VERSION "created by canmatrix"

NS_ :

BS_:

BU_: TCM iBooster HCU CIM SCM Right_Hand_Control Left_Hand_Control GPS VCM IC_2 XM GMRS Radio_CANtool Diagnostic_Tool_Digital_Wrench Information_System_Controller_1 STEERING_CONTROLLER VEHICLE_SECURITY RADIO_Hub ABS Battery_Management_Cntrl_2 Battery_Management_Cntrl_1 Auxiliary_Power_Unit_2 Auxiliary_Power_Unit_1 Electric_Propulsion_Cntrl_Unit_4 Electric_Propulsion_Cntrl_Unit_3 Electric_Propulsion_Cntrl_Unit_2 Electric_Propulsion_Cntrl_Unit_1 ECM IC

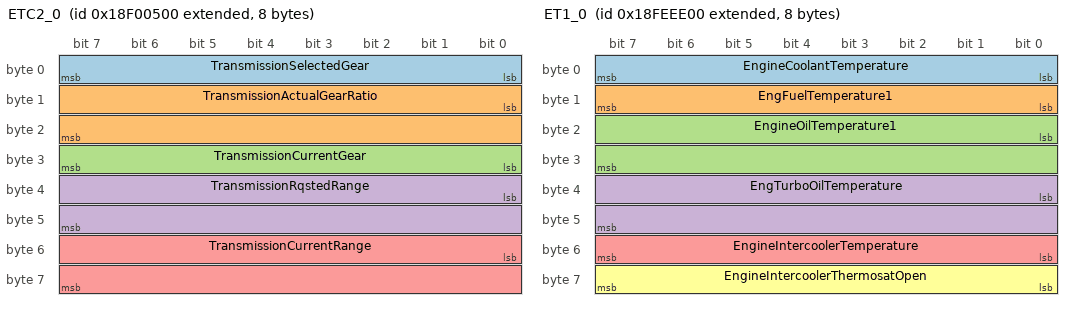
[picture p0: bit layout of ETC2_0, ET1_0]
BO_ 2565866752 ETC2_0: 8 ECM
 SG_ TransmissionSelectedGear : 0|8@1+ (1,-125) [-125.0|125.0] "" IC
 SG_ TransmissionActualGearRatio : 8|16@1+ (0.001,0) [0.0|64.255] "" IC
 SG_ TransmissionCurrentGear : 24|8@1+ (1,-125) [-125.0|125.0] "" IC
 SG_ TransmissionRqstedRange : 32|16@1+ (1,0) [0.0|65535.0] "" IC
 SG_ TransmissionCurrentRange : 48|16@1+ (1,0) [0.0|65535.0] "" IC

BO_ 2566843904 ET1_0: 8 ECM
 SG_ EngineCoolantTemperature : 0|8@1+ (1,-40) [-40.0|210.0] "°C" IC
 SG_ EngFuelTemperature1 : 8|8@1+ (1,-40) [-40.0|210.0] "°C" IC
 SG_ EngineOilTemperature1 : 16|16@1+ (0.03125,-273) [-273.0|1734.96875] "°C" IC
 SG_ EngTurboOilTemperature : 32|16@1+ (0.03125,-273) [-273.0|1734.96875] "°C" IC
 SG_ EngineIntercoolerTemperature : 48|8@1+ (1,-40) [-40.0|210.0] "°C" IC
 SG_ EngineIntercoolerThermosatOpen : 56|8@1+ (0.4,0) [0.0|100.0] "%" IC

BO_ 2566844928 FuelEconomy_0: 8 ECM
 SG_ EngineFuelRate : 0|16@1+ (0.05,0) [0.0|3212.75] "L/h" IC
 SG_ InstantaneousFuelEconomy : 16|16@1+ (0.00195312,0) [0.0|125.5] "km" IC
 SG_ AverageFuelEconomy : 32|16@1+ (0.00195312,0) [0.0|125.5] "km" IC
 SG_ EngineThrottlePosition : 48|8@1+ (0.4,0) [0.0|100.0] "%" IC

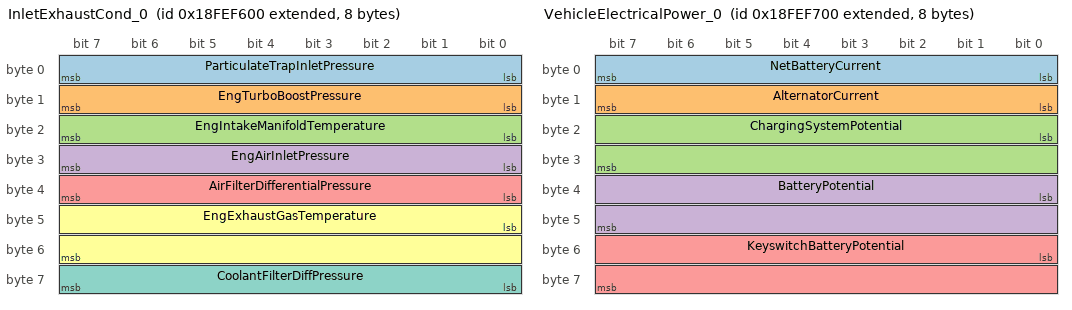
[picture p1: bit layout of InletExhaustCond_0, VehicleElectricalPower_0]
BO_ 2566845952 InletExhaustCond_0: 8 ECM
 SG_ ParticulateTrapInletPressure : 0|8@1+ (0.5,0) [0.0|125.0] "kPa" IC
 SG_ EngTurboBoostPressure : 8|8@1+ (2,0) [0.0|500.0] "kPa" IC
 SG_ EngIntakeManifoldTemperature : 16|8@1+ (1,-40) [-40.0|210.0] "°C" IC
 SG_ EngAirInletPressure : 24|8@1+ (2,0) [0.0|500.0] "kPa" IC
 SG_ AirFilterDifferentialPressure : 32|8@1+ (0.05,0) [0.0|12.5] "kPa" IC
 SG_ EngExhaustGasTemperature : 40|16@1+ (0.03125,-273) [-273.0|1734.96875] "°C" IC
 SG_ CoolantFilterDiffPressure : 56|8@1+ (0.5,0) [0.0|125.0] "kPa" IC

BO_ 2566846208 VehicleElectricalPower_0: 8 ECM
 SG_ NetBatteryCurrent : 0|8@1+ (1,-125) [-125.0|125.0] "A" IC
 SG_ AlternatorCurrent : 8|8@1+ (1,0) [0.0|250.0] "A" IC
 SG_ ChargingSystemPotential : 16|16@1+ (0.05,0) [0.0|3212.75] "V" IC
 SG_ BatteryPotential : 32|16@1+ (0.05,0) [0.0|3212.75] "V" IC
 SG_ KeyswitchBatteryPotential : 48|16@1+ (0.05,0) [0.0|3212.75] "V" IC

BO_ 2566844806 CruiseControlVehSpeed: 8 Right_Hand_Control
 SG_ pCruiseCntrlCounter : 50|4@1+ (1,0) [0.0|15.0] "" Vector__XXX
 SG_ TwoSpeedAxleSwitch : 0|2@1+ (1,0) [0.0|3.0] "" Vector__XXX
 SG_ ParkingBrakeSwitch : 2|2@1+ (1,0) [0.0|3.0] "" Vector__XXX
 SG_ Wheel_BasedVehicleSpeed : 8|16@1+ (0.00390625,0) [0.0|251.0] "km/h" Vector__XXX
 SG_ CruiseCtrlActive : 24|2@1+ (1,0) [0.0|3.0] "" Vector__XXX
 SG_ CruiseCtrlEnableSwitch : 26|2@1+ (1,0) [0.0|3.0] "" Vector__XXX
 SG_ BrakeSwitch : 28|2@1+ (1,0) [0.0|3.0] "" Vector__XXX
 SG_ ClutchSwitch : 30|2@1+ (1,0) [0.0|3.0] "" Vector__XXX
 SG_ CruiseCtrlSetSwitch : 32|2@1+ (1,0) [0.0|3.0] "" Vector__XXX
 SG_ CruiseCtrlCoastSwitch : 34|2@1+ (1,0) [0.0|3.0] "" Vector__XXX
 SG_ CruiseCtrlResumeSwitch : 36|2@1+ (1,0) [0.0|3.0] "" Vector__XXX
 SG_ CruiseCtrlAccelerateSwitch : 38|2@1+ (1,0) [0.0|3.0] "" Vector__XXX
 SG_ CruiseCtrlSetSpeed : 40|8@1+ (1,0) [0.0|250.0] "km/h" Vector__XXX
 SG_ pOdometerDriveBit : 6|2@1+ (1,0) [0.0|3.0] "" Vector__XXX
 SG_ CruiseCtrlPauseSw : 4|2@1+ (1,0) [0.0|3.0] "" Vector__XXX
 SG_ pCCChecksum : 56|8@1+ (1,0) [0.0|255.0] "" Vector__XXX
 SG_ pCruiseEnableStatus : 48|4@1+ (1,0) [0.0|15.0] "" Vector__XXX

BO_ 2565537345 RequestPGN: 3 Information_System_Controller_1
 SG_ RqstedPGN : 0|24@1+ (1,0) [0.0|16777200.0] "" Vector__XXX

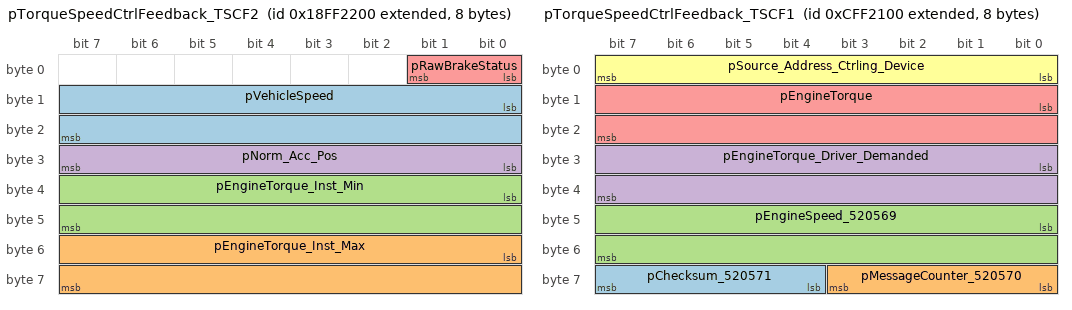
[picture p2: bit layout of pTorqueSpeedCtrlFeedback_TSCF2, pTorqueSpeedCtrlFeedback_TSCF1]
BO_ 2566857216 pTorqueSpeedCtrlFeedback_TSCF2: 8 ECM
 SG_ pVehicleSpeed : 8|16@1+ (0.00390625,0) [0.0|250.996] "km/h" Vector__XXX
 SG_ pEngineTorque_Inst_Max : 48|16@1- (0.03125,0) [-400.0|1607.96875] "Nm" Vector__XXX
 SG_ pEngineTorque_Inst_Min : 32|16@1- (0.03125,0) [-400.0|1607.96875] "Nm" Vector__XXX
 SG_ pNorm_Acc_Pos : 24|8@1+ (0.4,0) [0.0|100.0] "Percent" Vector__XXX
 SG_ pRawBrakeStatus : 0|2@1+ (1,0) [0.0|3.0] "state" Vector__XXX

BO_ 2365530368 pTorqueSpeedCtrlFeedback_TSCF1: 8 ECM
 SG_ pChecksum_520571 : 60|4@1+ (1,0) [0.0|15.0] "" Vector__XXX
 SG_ pMessageCounter_520570 : 56|4@1+ (1,0) [0.0|15.0] "" Vector__XXX
 SG_ pEngineSpeed_520569 : 40|16@1+ (1,0) [0.0|64255.0] "rpm" Vector__XXX
 SG_ pEngineTorque_Driver_Demanded : 24|16@1- (0.03125,0) [-400.0|1607.96875] "Nm" Vector__XXX
 SG_ pEngineTorque : 8|16@1- (0.03125,0) [-400.0|1607.96875] "Nm" Vector__XXX
 SG_ pSource_Address_Ctrling_Device : 0|8@1+ (1,0) [0.0|255.0] "Source Address" Vector__XXX

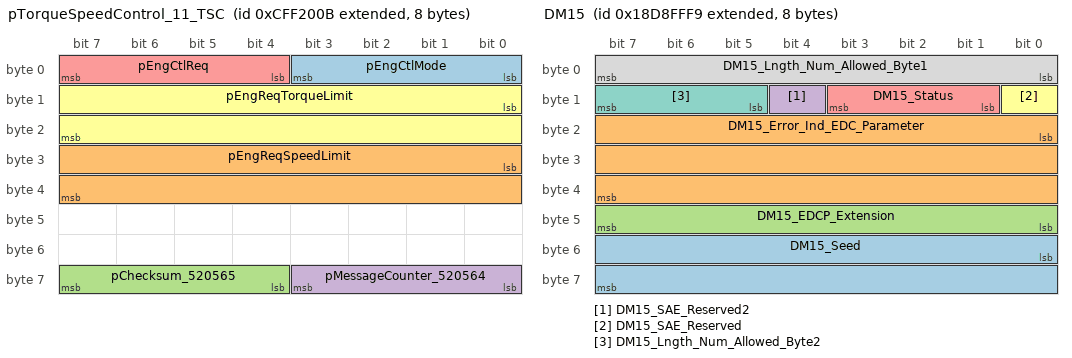
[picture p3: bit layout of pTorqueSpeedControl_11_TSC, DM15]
BO_ 2365530123 pTorqueSpeedControl_11_TSC: 8 ABS
 SG_ pEngCtlMode : 0|4@1+ (1,0) [0.0|15.0] "" Vector__XXX
 SG_ pEngReqSpeedLimit : 24|16@1+ (1,0) [0.0|64255.0] "rpm" Vector__XXX
 SG_ pChecksum_520565 : 60|4@1+ (1,0) [0.0|15.0] "" Vector__XXX
 SG_ pMessageCounter_520564 : 56|4@1+ (1,0) [0.0|15.0] "" Vector__XXX
 SG_ pEngCtlReq : 4|4@1+ (1,0) [0.0|15.0] "" Vector__XXX
 SG_ pEngReqTorqueLimit : 8|16@1- (0.03125,0) [-400.0|1607.96875] "Nm" Vector__XXX

BO_ 2566834822 DM1: 22 Right_Hand_Control
 SG_ DTC5 : 144|32@1+ (1,0) [0.0|4294967295.0] "" Vector__XXX
 SG_ DTC4 : 112|32@1+ (1,0) [0.0|4294967295.0] "" Vector__XXX
 SG_ DTC3 : 80|32@1+ (1,0) [0.0|4294967295.0] "" Vector__XXX
 SG_ DTC2 : 48|32@1+ (1,0) [0.0|4294967295.0] "" Vector__XXX
 SG_ DTC1 : 16|32@1+ (1,0) [0.0|4294967295.0] "" Vector__XXX
 SG_ DM_FlashRedStopLamp : 12|2@1+ (1,0) [0.0|3.0] "" Vector__XXX
 SG_ DM_FlashProtectLamp : 8|2@1+ (1,0) [0.0|3.0] "" Vector__XXX
 SG_ DM_FlashMalfuncIndicatorLamp : 14|2@1+ (1,0) [0.0|3.0] "" Vector__XXX
 SG_ DM_FlashAmberWarningLamp : 10|2@1+ (1,0) [0.0|3.0] "" Vector__XXX
 SG_ DM_ProtectLampStatus : 0|2@1+ (1,0) [0.0|3.0] "" Vector__XXX
 SG_ DM_RedStopLampState : 4|2@1+ (1,0) [0.0|3.0] "" Vector__XXX
 SG_ DM_AmberWrningLmpStatus : 2|2@1+ (1,0) [0.0|3.0] "" Vector__XXX
 SG_ DM_MalfuncnIndicatorLampStatus : 6|2@1+ (1,0) [0.0|3.0] "" Vector__XXX

BO_ 2564358137 DM15: 8 Diagnostic_Tool_Digital_Wrench
 SG_ DM15_Seed : 48|16@1+ (1,0) [0.0|65535.0] "" Vector__XXX
 SG_ DM15_Error_Ind_EDC_Parameter : 16|24@1+ (1,0) [0.0|16777215.0] "" Vector__XXX
 SG_ DM15_EDCP_Extension : 40|8@1+ (1,0) [0.0|255.0] "" Vector__XXX
 SG_ DM15_SAE_Reserved2 : 12|1@1+ (1,0) [1.0|1.0] "" Vector__XXX
 SG_ DM15_Status : 9|3@1+ (1,0) [0.0|7.0] "" Vector__XXX
 SG_ DM15_SAE_Reserved : 8|1@1+ (1,0) [1.0|1.0] "" Vector__XXX
 SG_ DM15_Lngth_Num_Allowed_Byte2 : 13|3@1+ (1,0) [0.0|7.0] "" Vector__XXX
 SG_ DM15_Lngth_Num_Allowed_Byte1 : 0|8@1+ (1,0) [0.0|255.0] "" Vector__XXX

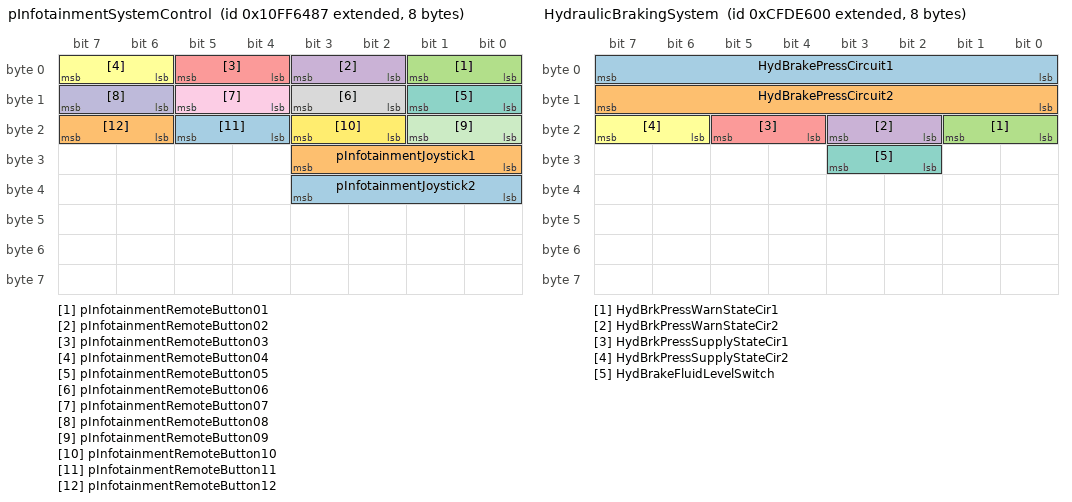
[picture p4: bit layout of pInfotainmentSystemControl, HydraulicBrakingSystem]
BO_ 2432656519 pInfotainmentSystemControl: 8 Left_Hand_Control
 SG_ pInfotainmentJoystick2 : 32|4@1+ (1,0) [0.0|15.0] "" Vector__XXX
 SG_ pInfotainmentJoystick1 : 24|4@1+ (1,0) [0.0|15.0] "" Vector__XXX
 SG_ pInfotainmentRemoteButton01 : 0|2@1+ (1,0) [0.0|3.0] "" Vector__XXX
 SG_ pInfotainmentRemoteButton02 : 2|2@1+ (1,0) [0.0|3.0] "" Vector__XXX
 SG_ pInfotainmentRemoteButton03 : 4|2@1+ (1,0) [0.0|3.0] "" Vector__XXX
 SG_ pInfotainmentRemoteButton04 : 6|2@1+ (1,0) [0.0|3.0] "" Vector__XXX
 SG_ pInfotainmentRemoteButton05 : 8|2@1+ (1,0) [0.0|3.0] "" Vector__XXX
 SG_ pInfotainmentRemoteButton06 : 10|2@1+ (1,0) [0.0|3.0] "" Vector__XXX
 SG_ pInfotainmentRemoteButton07 : 12|2@1+ (1,0) [0.0|3.0] "" Vector__XXX
 SG_ pInfotainmentRemoteButton08 : 14|2@1+ (1,0) [0.0|3.0] "" Vector__XXX
 SG_ pInfotainmentRemoteButton09 : 16|2@1+ (1,0) [0.0|3.0] "" Vector__XXX
 SG_ pInfotainmentRemoteButton10 : 18|2@1+ (1,0) [0.0|3.0] "" Vector__XXX
 SG_ pInfotainmentRemoteButton11 : 20|2@1+ (1,0) [0.0|3.0] "" Vector__XXX
 SG_ pInfotainmentRemoteButton12 : 22|2@1+ (1,0) [0.0|3.0] "" Vector__XXX

BO_ 2432656775 pOperatorSwitchStatus_135: 8 Left_Hand_Control
 SG_ pOperatorButton29 : 58|2@1+ (1,0) [0.0|3.0] "" Vector__XXX
 SG_ pOperatorButton1 : 0|2@1+ (1,0) [0.0|3.0] "" Vector__XXX
 SG_ pOperatorButton2 : 2|2@1+ (1,0) [0.0|3.0] "" Vector__XXX
 SG_ pOperatorButton3 : 4|2@1+ (1,0) [0.0|3.0] "" Vector__XXX
 SG_ pOperatorButton4 : 6|2@1+ (1,0) [0.0|3.0] "" Vector__XXX
 SG_ pOperatorButton5 : 8|2@1+ (1,0) [0.0|3.0] "" Vector__XXX
 SG_ pOperatorButton6 : 10|2@1+ (1,0) [0.0|3.0] "" Vector__XXX
 SG_ pOperatorButton7 : 12|2@1+ (1,0) [0.0|3.0] "" Vector__XXX
 SG_ pOperatorButton8 : 14|2@1+ (1,0) [0.0|3.0] "" Vector__XXX
 SG_ pOperatorButton9 : 16|2@1+ (1,0) [0.0|3.0] "" Vector__XXX
 SG_ pOperatorButton10 : 18|2@1+ (1,0) [0.0|3.0] "" Vector__XXX
 SG_ pOperatorButton11 : 20|2@1+ (1,0) [0.0|3.0] "" Vector__XXX
 SG_ pOperatorButton12 : 22|2@1+ (1,0) [0.0|3.0] "" Vector__XXX
 SG_ pOperatorButton13 : 24|2@1+ (1,0) [0.0|3.0] "" Vector__XXX
 SG_ pOperatorButton14 : 26|2@1+ (1,0) [0.0|3.0] "" Vector__XXX
 SG_ pOperatorButton15 : 28|2@1+ (1,0) [0.0|3.0] "" Vector__XXX
 SG_ pOperatorButton16 : 30|2@1+ (1,0) [0.0|3.0] "" Vector__XXX
 SG_ pOperatorButton17 : 32|2@1+ (1,0) [0.0|3.0] "" Vector__XXX
 SG_ pOperatorButton18 : 34|2@1+ (1,0) [0.0|3.0] "" Vector__XXX
 SG_ pOperatorButton19 : 36|2@1+ (1,0) [0.0|3.0] "" Vector__XXX
 SG_ pOperatorButton20 : 38|2@1+ (1,0) [0.0|3.0] "" Vector__XXX
 SG_ pOperatorButton21 : 40|2@1+ (1,0) [0.0|3.0] "" Vector__XXX
 SG_ pOperatorButton22 : 42|2@1+ (1,0) [0.0|3.0] "" Vector__XXX
 SG_ pOperatorButton23 : 44|2@1+ (1,0) [0.0|3.0] "" Vector__XXX
 SG_ pOperatorButton24 : 46|2@1+ (1,0) [0.0|3.0] "" Vector__XXX
 SG_ pOperatorButton25 : 48|2@1+ (1,0) [0.0|3.0] "" Vector__XXX
 SG_ pOperatorButton26 : 50|2@1+ (1,0) [0.0|3.0] "" Vector__XXX
 SG_ pOperatorButton27 : 52|2@1+ (1,0) [0.0|3.0] "" Vector__XXX
 SG_ pOperatorButton28 : 54|2@1+ (1,0) [0.0|3.0] "" Vector__XXX
 SG_ pSideStandStatus : 56|2@1+ (1,0) [0.0|3.0] "" Vector__XXX

BO_ 2365449728 HydraulicBrakingSystem: 8 ECM
 SG_ HydBrakePressCircuit1 : 0|8@1+ (100,0) [0.0|25000.0] "kPa" Vector__XXX
 SG_ HydBrakePressCircuit2 : 8|8@1+ (100,0) [0.0|25000.0] "kPa" Vector__XXX
 SG_ HydBrkPressWarnStateCir1 : 16|2@1+ (1,0) [0.0|3.0] "" Vector__XXX
 SG_ HydBrkPressWarnStateCir2 : 18|2@1+ (1,0) [0.0|3.0] "" Vector__XXX
 SG_ HydBrkPressSupplyStateCir1 : 20|2@1+ (1,0) [0.0|3.0] "" Vector__XXX
 SG_ HydBrkPressSupplyStateCir2 : 22|2@1+ (1,0) [0.0|3.0] "" Vector__XXX
 SG_ HydBrakeFluidLevelSwitch : 26|2@1+ (1,0) [0.0|3.0] "" Vector__XXX

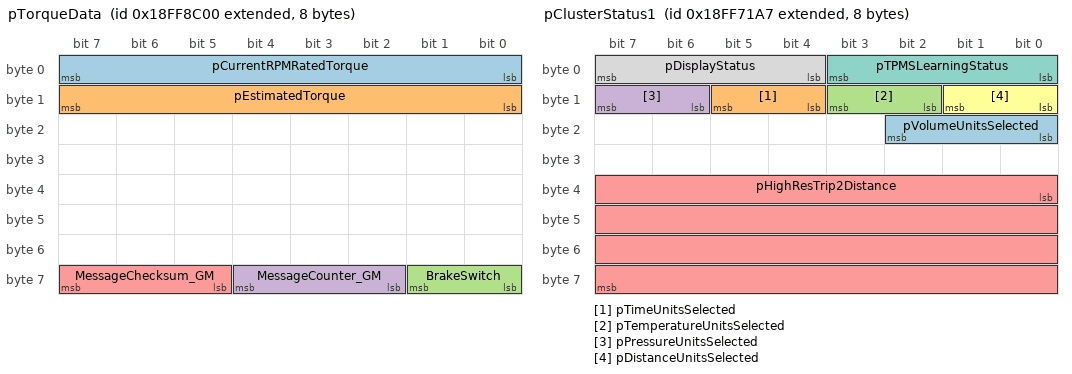
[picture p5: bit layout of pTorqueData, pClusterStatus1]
BO_ 2566884352 pTorqueData: 8 ECM
 SG_ pCurrentRPMRatedTorque : 0|8@1+ (0.03125,-1024) [-1024.0|1024.0] "Nm" Vector__XXX
 SG_ pEstimatedTorque : 8|8@1+ (0.03125,-1024) [-1024.0|1024.0] "Nm" Vector__XXX
 SG_ BrakeSwitch : 56|2@1+ (1,0) [0.0|3.0] "" Vector__XXX
 SG_ MessageCounter_GM : 58|3@1+ (1,0) [0.0|7.0] "" Vector__XXX
 SG_ MessageChecksum_GM : 61|3@1+ (1,0) [0.0|7.0] "" Vector__XXX

BO_ 2566842396 VehicleDirectionSpeed: 8 GPS
 SG_ CompassBearing : 0|16@1+ (0.0078125,0) [0.0|501.99] "Degree" Vector__XXX

BO_ 2566877607 pClusterStatus1: 8 IC_2
 SG_ pVolumeUnitsSelected : 16|3@1+ (1,0) [0.0|7.0] "" Vector__XXX
 SG_ pTimeUnitsSelected : 12|2@1+ (1,0) [0.0|3.0] "" Vector__XXX
 SG_ pTemperatureUnitsSelected : 10|2@1+ (1,0) [0.0|3.0] "" Vector__XXX
 SG_ pPressureUnitsSelected : 14|2@1+ (1,0) [0.0|3.0] "" Vector__XXX
 SG_ pHighResTrip2Distance : 32|32@1+ (0.005,0) [0.0|21055406.0] "km" Vector__XXX
 SG_ pDistanceUnitsSelected : 8|2@1+ (1,0) [0.0|3.0] "" Vector__XXX
 SG_ pTPMSLearningStatus : 0|4@1+ (1,0) [0.0|15.0] "" Vector__XXX
 SG_ pDisplayStatus : 4|4@1+ (1,0) [0.0|15.0] "" Vector__XXX

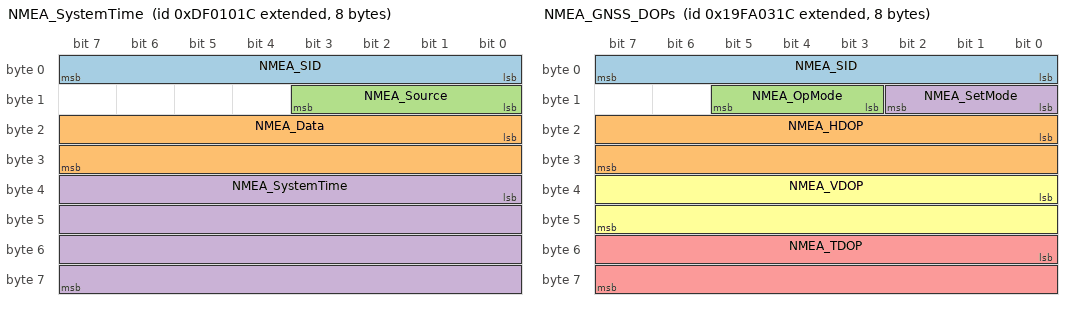
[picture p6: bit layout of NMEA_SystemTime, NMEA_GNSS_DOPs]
BO_ 2381320220 NMEA_SystemTime: 8 GPS
 SG_ NMEA_SID : 0|8@1+ (1,0) [0.0|255.0] "Int" Vector__XXX
 SG_ NMEA_Data : 16|16@1+ (1,0) [0.0|65535.0] "Days" Vector__XXX
 SG_ NMEA_Source : 8|4@1+ (1,0) [0.0|15.0] "" Vector__XXX
 SG_ NMEA_SystemTime : 32|32@1+ (0.0001,0) [0.0|429496.7295] "Seconds" Vector__XXX

BO_ 2314731804 NMEA_PositionRapidUpdate: 8 GPS
 SG_ NMEA_Latitude : 0|32@1- (1e-07,0) [-214.7483648|214.7483647] "Deg" Vector__XXX
 SG_ NMEA_Longitude : 32|32@1- (1e-07,0) [-214.7483648|214.7483647] "Deg" Vector__XXX

BO_ 2583298844 NMEA_GNSS_DOPs: 8 GPS
 SG_ NMEA_SID : 0|8@1+ (1,0) [0.0|255.0] "Int" Vector__XXX
 SG_ NMEA_HDOP : 16|16@1+ (0.01,0) [0.0|655.35] "" Vector__XXX
 SG_ NMEA_OpMode : 11|3@1+ (1,0) [0.0|7.0] "" Vector__XXX
 SG_ NMEA_SetMode : 8|3@1+ (1,0) [0.0|7.0] "" Vector__XXX
 SG_ NMEA_TDOP : 48|16@1+ (0.01,0) [0.0|655.35] "" Vector__XXX
 SG_ NMEA_VDOP : 32|16@1+ (0.01,0) [0.0|655.35] "" Vector__XXX

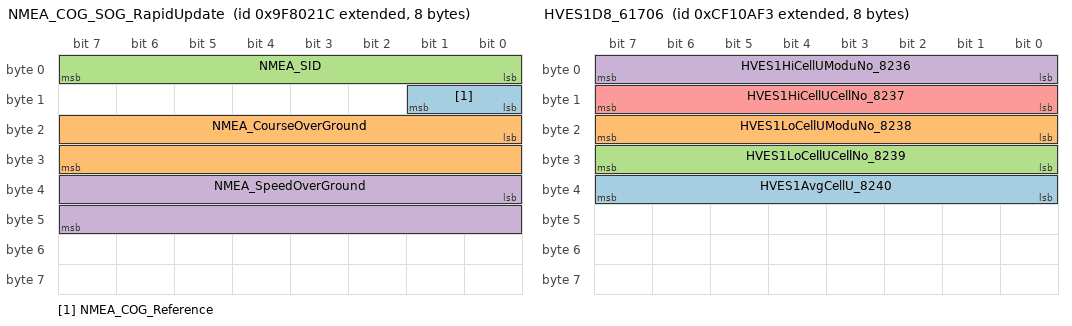
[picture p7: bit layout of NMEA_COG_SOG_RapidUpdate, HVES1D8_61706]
BO_ 2314732060 NMEA_COG_SOG_RapidUpdate: 8 GPS
 SG_ NMEA_COG_Reference : 8|2@1+ (1,0) [0.0|3.0] "" Vector__XXX
 SG_ NMEA_CourseOverGround : 16|16@1+ (0.0001,0) [0.0|6.5535] "Rad" Vector__XXX
 SG_ NMEA_SID : 0|8@1+ (1,0) [0.0|255.0] "Int" Vector__XXX
 SG_ NMEA_SpeedOverGround : 32|16@1+ (0.01,0) [0.0|655.35] "m/s" Vector__XXX

BO_ 2364607475 HVES1D9_61707: 8 Battery_Management_Cntrl_1
 SG_ HVES1LoCellTModuNo_8243 : 16|8@1+ (1,0) [0.0|250.0] "count" Vector__XXX
 SG_ HVES1LoCellTCellNo_8244 : 24|8@1+ (1,0) [0.0|250.0] "count" Vector__XXX
 SG_ HVES1HiCellTModuNo_8241 : 0|8@1+ (1,0) [0.0|250.0] "count" Vector__XXX
 SG_ HVES1HiCellTCellNo_8242 : 8|8@1+ (1,0) [0.0|250.0] "count" Vector__XXX

BO_ 2364607219 HVES1D8_61706: 8 Battery_Management_Cntrl_1
 SG_ HVES1AvgCellU_8240 : 32|8@1+ (1,0) [0.0|250.0] "count" Vector__XXX
 SG_ HVES1LoCellUModuNo_8238 : 16|8@1+ (1,0) [0.0|250.0] "count" Vector__XXX
 SG_ HVES1LoCellUCellNo_8239 : 24|8@1+ (1,0) [0.0|250.0] "count" Vector__XXX
 SG_ HVES1HiCellUModuNo_8236 : 0|8@1+ (1,0) [0.0|250.0] "count" Vector__XXX
 SG_ HVES1HiCellUCellNo_8237 : 8|8@1+ (1,0) [0.0|250.0] "count" Vector__XXX

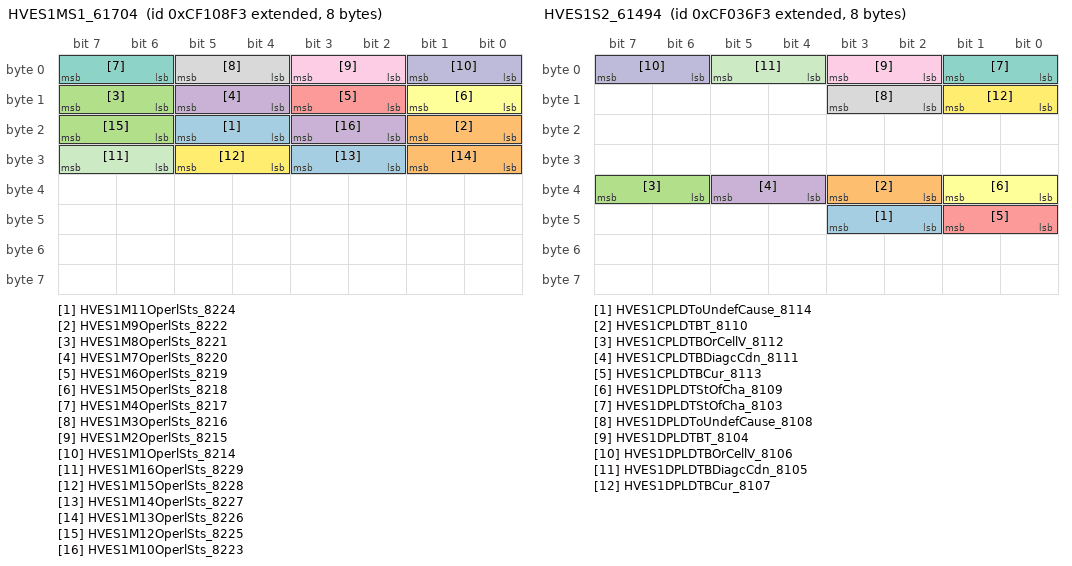
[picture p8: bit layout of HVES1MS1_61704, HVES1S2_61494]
BO_ 2364606707 HVES1MS1_61704: 8 Battery_Management_Cntrl_1
 SG_ HVES1M11OperlSts_8224 : 20|2@1+ (1,0) [0.0|3.0] "bit" Vector__XXX
 SG_ HVES1M9OperlSts_8222 : 16|2@1+ (1,0) [0.0|3.0] "bit" Vector__XXX
 SG_ HVES1M8OperlSts_8221 : 14|2@1+ (1,0) [0.0|3.0] "bit" Vector__XXX
 SG_ HVES1M7OperlSts_8220 : 12|2@1+ (1,0) [0.0|3.0] "bit" Vector__XXX
 SG_ HVES1M6OperlSts_8219 : 10|2@1+ (1,0) [0.0|3.0] "bit" Vector__XXX
 SG_ HVES1M5OperlSts_8218 : 8|2@1+ (1,0) [0.0|3.0] "bit" Vector__XXX
 SG_ HVES1M4OperlSts_8217 : 6|2@1+ (1,0) [0.0|3.0] "bit" Vector__XXX
 SG_ HVES1M3OperlSts_8216 : 4|2@1+ (1,0) [0.0|3.0] "bit" Vector__XXX
 SG_ HVES1M2OperlSts_8215 : 2|2@1+ (1,0) [0.0|3.0] "bit" Vector__XXX
 SG_ HVES1M1OperlSts_8214 : 0|2@1+ (1,0) [0.0|3.0] "bit" Vector__XXX
 SG_ HVES1M16OperlSts_8229 : 30|2@1+ (1,0) [0.0|3.0] "bit" Vector__XXX
 SG_ HVES1M15OperlSts_8228 : 28|2@1+ (1,0) [0.0|3.0] "bit" Vector__XXX
 SG_ HVES1M14OperlSts_8227 : 26|2@1+ (1,0) [0.0|3.0] "bit" Vector__XXX
 SG_ HVES1M13OperlSts_8226 : 24|2@1+ (1,0) [0.0|3.0] "bit" Vector__XXX
 SG_ HVES1M12OperlSts_8225 : 22|2@1+ (1,0) [0.0|3.0] "bit" Vector__XXX
 SG_ HVES1M10OperlSts_8223 : 18|2@1+ (1,0) [0.0|3.0] "bit" Vector__XXX

BO_ 2364552947 HVES1S2_61494: 8 Battery_Management_Cntrl_1
 SG_ HVES1CPLDToUndefCause_8114 : 42|2@1+ (1,0) [0.0|3.0] "bit" Vector__XXX
 SG_ HVES1CPLDTBT_8110 : 34|2@1+ (1,0) [0.0|3.0] "bit" Vector__XXX
 SG_ HVES1CPLDTBOrCellV_8112 : 38|2@1+ (1,0) [0.0|3.0] "bit" Vector__XXX
 SG_ HVES1CPLDTBDiagcCdn_8111 : 36|2@1+ (1,0) [0.0|3.0] "bit" Vector__XXX
 SG_ HVES1CPLDTBCur_8113 : 40|2@1+ (1,0) [0.0|3.0] "bit" Vector__XXX
 SG_ HVES1DPLDTStOfCha_8109 : 32|2@1+ (1,0) [0.0|3.0] "bit" Vector__XXX
 SG_ HVES1DPLDTStOfCha_8103 : 0|2@1+ (1,0) [0.0|3.0] "bit" Vector__XXX
 SG_ HVES1DPLDToUndefCause_8108 : 10|2@1+ (1,0) [0.0|3.0] "bit" Vector__XXX
 SG_ HVES1DPLDTBT_8104 : 2|2@1+ (1,0) [0.0|3.0] "bit" Vector__XXX
 SG_ HVES1DPLDTBOrCellV_8106 : 6|2@1+ (1,0) [0.0|3.0] "bit" Vector__XXX
 SG_ HVES1DPLDTBDiagcCdn_8105 : 4|2@1+ (1,0) [0.0|3.0] "bit" Vector__XXX
 SG_ HVES1DPLDTBCur_8107 : 8|2@1+ (1,0) [0.0|3.0] "bit" Vector__XXX

BO_ 2633785075 HVES1HIST_64606: 8 Battery_Management_Cntrl_1
 SG_ HVES1TotEgyThput_8211 : 24|32@1- (100,0) [0.0|421108121500.0] "Watt-hour" Vector__XXX
 SG_ HVES1TotAccumCha_8212 : 56|32@1- (100,0) [0.0|421108121500.0] "Ah" Vector__XXX
 SG_ HVES1StOfHealth_8121 : 0|8@1- (0.02044,0) [0.0|5.11] "V" Vector__XXX
 SG_ HVES1CtorOpenUndLoa_8122 : 8|16@1+ (1,0) [0.0|64255.0] "count" Vector__XXX

BO_ 2566675955 HVES1CFG_64605: 8 Battery_Management_Cntrl_1
 SG_ HVES1RecomMinSOC_8118 : 48|16@1- (0.0015625,0) [0.0|100.3984375] "%" Vector__XXX
 SG_ HVES1RecomMinOpergV_8116 : 16|16@1- (0.05,0) [0.0|3212.75] "V" Vector__XXX
 SG_ HVES1RecomMinOpergT_8208 : 96|16@1- (0.03125,-273) [-273.0|1734.96875] "deg C" Vector__XXX
 SG_ HVES1RecomMaxSOC_8119 : 64|16@1- (0.0015625,0) [0.0|100.3984375] "%" Vector__XXX
 SG_ HVES1RecomMaxOpergV_8117 : 32|16@1- (0.05,0) [0.0|3212.75] "V" Vector__XXX
 SG_ HVES1RecomMaxOpergT_8120 : 80|16@1- (0.03125,-273) [-273.0|1734.96875] "deg C" Vector__XXX
 SG_ HVES1NomVoltage_8115 : 0|16@1- (0.05,0) [0.0|3212.75] "V" Vector__XXX
 SG_ HVES1CellMinVLim_8210 : 120|8@1- (0.02044,0) [0.0|5.11] "V" Vector__XXX
 SG_ HVES1CellMaxVLim_8209 : 112|8@1- (0.02044,0) [0.0|5.11] "V" Vector__XXX

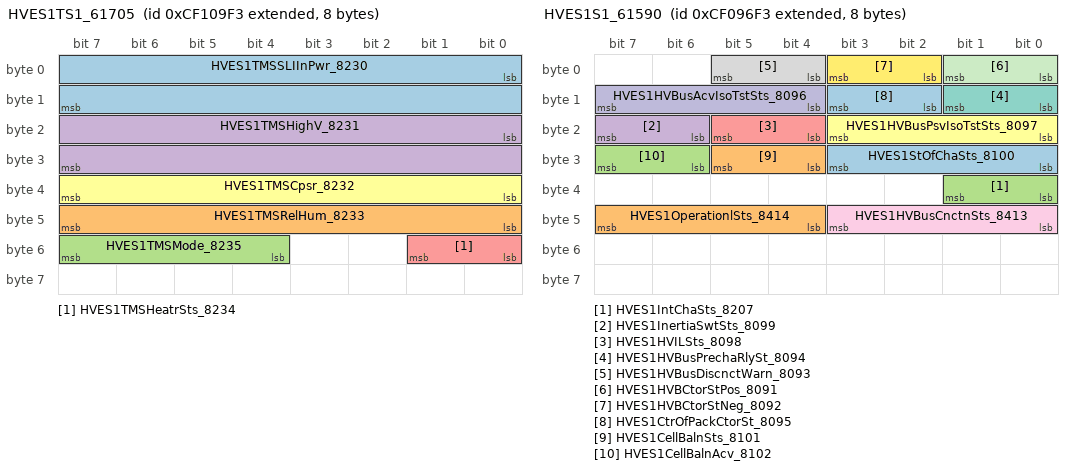
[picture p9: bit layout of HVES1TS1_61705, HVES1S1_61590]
BO_ 2364606963 HVES1TS1_61705: 8 Battery_Management_Cntrl_1
 SG_ HVES1TMSSLIInPwr_8230 : 0|16@1- (0.5,0) [0.0|32127.5] "W" Vector__XXX
 SG_ HVES1TMSRelHum_8233 : 40|8@1- (0.4,0) [0.0|100.0] "%" Vector__XXX
 SG_ HVES1TMSMode_8235 : 52|4@1- (1,0) [0.0|15.0] "bits" Vector__XXX
 SG_ HVES1TMSHighV_8231 : 16|16@1- (0.5,0) [0.0|32127.5] "W" Vector__XXX
 SG_ HVES1TMSHeatrSts_8234 : 48|2@1- (1,0) [0.0|3.0] "bits" Vector__XXX
 SG_ HVES1TMSCpsr_8232 : 32|8@1- (32,0) [0.0|8000.0] "rpm" Vector__XXX

BO_ 2364580083 HVES1D7_61600: 8 Battery_Management_Cntrl_1
 SG_ HVES1MaxChaVLim_8090 : 48|16@1- (0.05,0) [0.0|3212.75] "V" Vector__XXX
 SG_ HVES1DischaEgyCp_8205 : 0|24@1- (0.001,0) [0.0|16449.535] "kWh" Vector__XXX
 SG_ HVES1ChaEgyCp_8206 : 24|24@1- (0.001,0) [0.0|16449.535] "kWh" Vector__XXX

BO_ 2364577523 HVES1S1_61590: 8 Battery_Management_Cntrl_1
 SG_ HVES1StOfChaSts_8100 : 24|4@1+ (1,0) [0.0|15.0] "bits" Vector__XXX
 SG_ HVES1OperationlSts_8414 : 44|4@1+ (1,0) [0.0|15.0] "bit" Vector__XXX
 SG_ HVES1IntChaSts_8207 : 32|2@1- (1,0) [0.0|3.0] "bits" Vector__XXX
 SG_ HVES1InertiaSwtSts_8099 : 22|2@1+ (1,0) [0.0|3.0] "bits" Vector__XXX
 SG_ HVES1HVILSts_8098 : 20|2@1+ (1,0) [0.0|3.0] "bits" Vector__XXX
 SG_ HVES1HVBusPsvIsoTstSts_8097 : 16|4@1- (1,0) [0.0|15.0] "bits" Vector__XXX
 SG_ HVES1HVBusPrechaRlySt_8094 : 8|2@1+ (1,0) [0.0|3.0] "bits" Vector__XXX
 SG_ HVES1HVBusDiscnctWarn_8093 : 4|2@1+ (1,0) [0.0|15.0] "bits" Vector__XXX
 SG_ HVES1HVBusCnctnSts_8413 : 40|4@1- (1,0) [0.0|15.0] "bits" Vector__XXX
 SG_ HVES1HVBusAcvIsoTstSts_8096 : 12|4@1- (1,0) [0.0|15.0] "bits" Vector__XXX
 SG_ HVES1HVBCtorStPos_8091 : 0|2@1- (1,0) [0.0|3.0] "bit" Vector__XXX
 SG_ HVES1HVBCtorStNeg_8092 : 2|2@1- (1,0) [0.0|3.0] "bit" Vector__XXX
 SG_ HVES1CtrOfPackCtorSt_8095 : 10|2@1+ (1,0) [0.0|3.0] "bits" Vector__XXX
 SG_ HVES1CellBalnSts_8101 : 28|2@1+ (1,0) [0.0|3.0] "bit" Vector__XXX
 SG_ HVES1CellBalnAcv_8102 : 30|2@1+ (1,0) [0.0|3.0] "bit" Vector__XXX

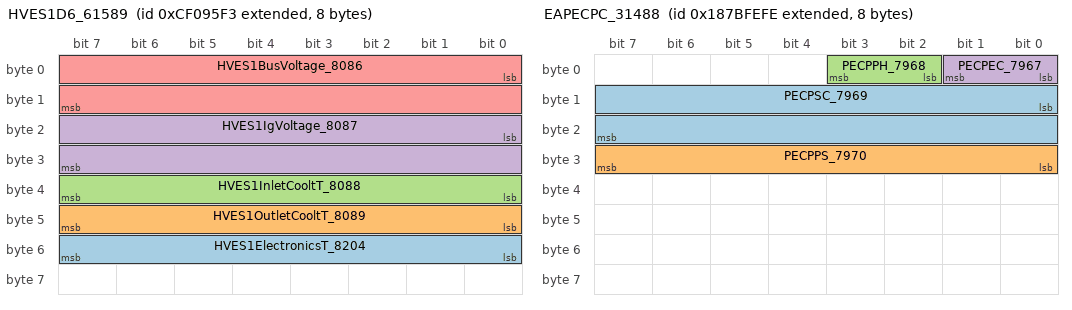
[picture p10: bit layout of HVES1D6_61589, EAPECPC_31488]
BO_ 2364577267 HVES1D6_61589: 8 Battery_Management_Cntrl_1
 SG_ HVES1ElectronicsT_8204 : 48|8@1- (1,-40) [-40.0|210.0] "deg C" Vector__XXX
 SG_ HVES1OutletCooltT_8089 : 40|8@1- (1,-40) [-40.0|210.0] "deg C" Vector__XXX
 SG_ HVES1InletCooltT_8088 : 32|8@1- (1,-40) [-40.0|210.0] "deg C" Vector__XXX
 SG_ HVES1IgVoltage_8087 : 16|16@1- (0.01,0) [0.0|642.55] "V" Vector__XXX
 SG_ HVES1BusVoltage_8086 : 0|16@1- (0.05,0) [0.0|3212.75] "V" Vector__XXX

BO_ 2364577011 HVES1D4_61588: 8 Battery_Management_Cntrl_1
 SG_ HVES1MinCellStOCha_8084 : 32|16@1- (0.0015625,0) [0.0|100.3984375] "%" Vector__XXX
 SG_ HVES1MaxCellStOCha_8085 : 48|16@1- (0.0015625,0) [0.0|100.3984375] "%" Vector__XXX
 SG_ HVES1DchaCurLim_8082 : 0|16@1- (0.05,-1600) [-1600.0|1612.75] "A" Vector__XXX
 SG_ HVES1ChaCurLim_8083 : 16|16@1- (0.05,-1600) [-1600.0|1612.75] "A" Vector__XXX

BO_ 2364576755 HVES1D4_61587: 8 Battery_Management_Cntrl_1
 SG_ HVES1DischargeCap_8079 : 0|16@1- (0.01,0) [0.0|642.55] "Ah" Vector__XXX
 SG_ HVES1ChargeCap_8080 : 16|16@1- (0.01,0) [0.0|642.55] "Ah" Vector__XXX
 SG_ HVES1CellBalnCt_8081 : 32|16@1- (1,0) [0.0|64255.0] "count" Vector__XXX

BO_ 2364576499 HVES1D3_61586: 8 Battery_Management_Cntrl_1
 SG_ HVES1LowestCellT_8076 : 16|16@1- (0.03125,-273) [-273.0|1734.96875] "degrees C" Vector__XXX
 SG_ HVES1HighestCellT_8075 : 0|16@1- (0.03125,-273) [-273.0|1734.96875] "degrees C" Vector__XXX
 SG_ HVES1CellTDftlSts_8078 : 56|2@1- (1,0) [0.0|3.0] "bits" Vector__XXX
 SG_ HVES1AverageCellT_8077 : 32|16@1- (0.03125,-273) [-273.0|1734.96875] "degrees C" Vector__XXX

BO_ 2364576243 HVES1D2_61585: 8 Battery_Management_Cntrl_1
 SG_ HVES1LowCellVolt_5923 : 32|16@1- (0.001,0) [0.0|64.255] "V" Vector__XXX
 SG_ HVES1HiCellVolt_5922 : 16|16@1- (0.001,0) [0.0|64.255] "V" Vector__XXX
 SG_ HVES1FastUpdStOCh_5921 : 0|16@1- (0.0015625,0) [0.0|100.3984375] "%" Vector__XXX
 SG_ HVES1CellVoltDftlSts_5924 : 56|4@1- (1,0) [0.0|15.0] "bot" Vector__XXX

BO_ 2364575987 HVES1D1_61584: 8 Battery_Management_Cntrl_1
 SG_ HVES1VoltageLevel_5919 : 32|16@1- (0.05,0) [0.0|3212.75] "V" Vector__XXX
 SG_ HVES1Current_5920 : 48|16@1- (0.05,-1600) [-1600.0|1612.75] "A" Vector__XXX
 SG_ HVES1AvlChPwr_5918 : 16|16@1- (0.05,0) [0.0|3212.75] "kW" Vector__XXX
 SG_ HVES1AvlDchaPwr_5917 : 0|16@1- (0.05,0) [0.0|3212.75] "kW" Vector__XXX

BO_ 2558263038 EAPECPC_31488: 8 Vector__XXX
 SG_ PECPSC_7969 : 8|16@1+ (0.5,0) [0.0|32767.5] "rpm" Vector__XXX
 SG_ PECPPS_7970 : 24|8@1+ (0.5,0) [0.0|127.5] "%" Vector__XXX
 SG_ PECPPH_7968 : 2|2@1+ (1,0) [0.0|3.0] "" Vector__XXX
 SG_ PECPEC_7967 : 0|2@1+ (1,0) [0.0|3.0] "" Vector__XXX

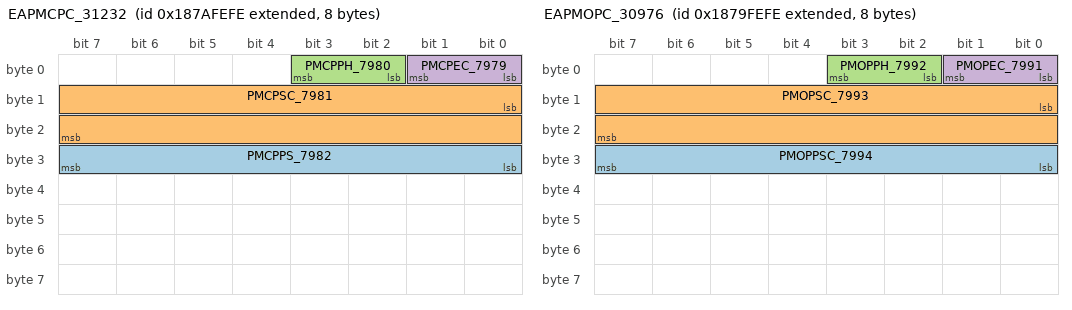
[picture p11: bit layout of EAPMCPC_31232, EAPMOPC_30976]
BO_ 2558197502 EAPMCPC_31232: 8 Vector__XXX
 SG_ PMCPPS_7982 : 24|8@1+ (0.5,0) [0.0|127.5] "%" Vector__XXX
 SG_ PMCPSC_7981 : 8|16@1+ (0.5,0) [0.0|32767.5] "rpm" Vector__XXX
 SG_ PMCPPH_7980 : 2|2@1+ (1,0) [0.0|3.0] "" Vector__XXX
 SG_ PMCPEC_7979 : 0|2@1+ (1,0) [0.0|3.0] "" Vector__XXX

BO_ 2558131966 EAPMOPC_30976: 8 Vector__XXX
 SG_ PMOPPSC_7994 : 24|8@1+ (0.5,0) [0.0|127.5] "%" Vector__XXX
 SG_ PMOPSC_7993 : 8|16@1+ (0.5,0) [0.0|32767.5] "rpm" Vector__XXX
 SG_ PMOPPH_7992 : 2|2@1+ (1,0) [0.0|3.0] "" Vector__XXX
 SG_ PMOPEC_7991 : 0|2@1+ (1,0) [0.0|3.0] "" Vector__XXX

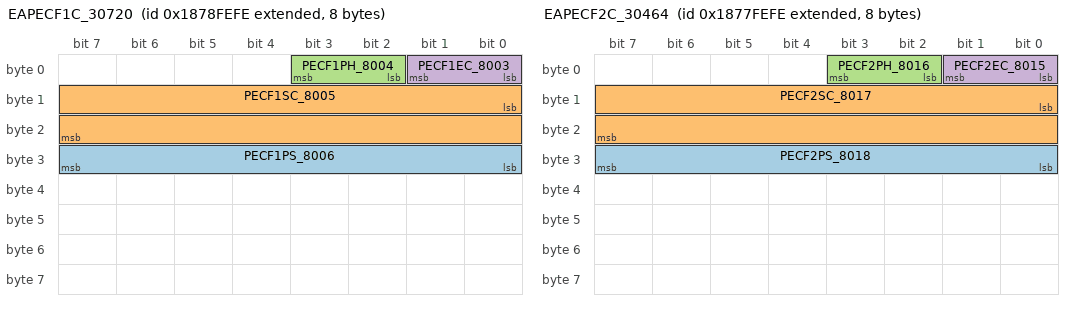
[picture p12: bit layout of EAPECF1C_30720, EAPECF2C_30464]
BO_ 2558066430 EAPECF1C_30720: 8 Vector__XXX
 SG_ PECF1PS_8006 : 24|8@1+ (0.5,0) [0.0|127.5] "%" Vector__XXX
 SG_ PECF1SC_8005 : 8|16@1+ (0.5,0) [0.0|32767.5] "rpm" Vector__XXX
 SG_ PECF1PH_8004 : 2|2@1+ (1,0) [0.0|3.0] "" Vector__XXX
 SG_ PECF1EC_8003 : 0|2@1+ (1,0) [0.0|3.0] "" Vector__XXX

BO_ 2558000894 EAPECF2C_30464: 8 Vector__XXX
 SG_ PECF2PS_8018 : 24|8@1+ (0.5,0) [0.0|127.5] "%" Vector__XXX
 SG_ PECF2SC_8017 : 8|16@1+ (0.5,0) [0.0|32767.5] "rpm" Vector__XXX
 SG_ PECF2PH_8016 : 2|2@1+ (1,0) [0.0|3.0] "" Vector__XXX
 SG_ PECF2EC_8015 : 0|2@1+ (1,0) [0.0|3.0] "" Vector__XXX

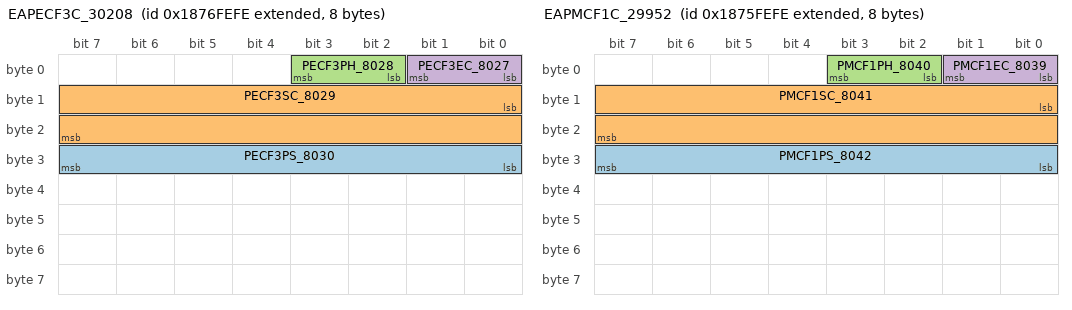
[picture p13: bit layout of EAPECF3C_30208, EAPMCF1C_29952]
BO_ 2557935358 EAPECF3C_30208: 8 Vector__XXX
 SG_ PECF3PS_8030 : 24|8@1+ (0.5,0) [0.0|127.5] "%" Vector__XXX
 SG_ PECF3SC_8029 : 8|16@1+ (0.5,0) [0.0|32767.5] "rpm" Vector__XXX
 SG_ PECF3PH_8028 : 2|2@1+ (1,0) [0.0|3.0] "" Vector__XXX
 SG_ PECF3EC_8027 : 0|2@1+ (1,0) [0.0|3.0] "" Vector__XXX

BO_ 2557869822 EAPMCF1C_29952: 8 Vector__XXX
 SG_ PMCF1PS_8042 : 24|8@1+ (0.5,0) [0.0|127.5] "%" Vector__XXX
 SG_ PMCF1SC_8041 : 8|16@1+ (0.5,0) [0.0|32767.5] "rpm" Vector__XXX
 SG_ PMCF1PH_8040 : 2|2@1+ (1,0) [0.0|3.0] "" Vector__XXX
 SG_ PMCF1EC_8039 : 0|2@1+ (1,0) [0.0|3.0] "" Vector__XXX

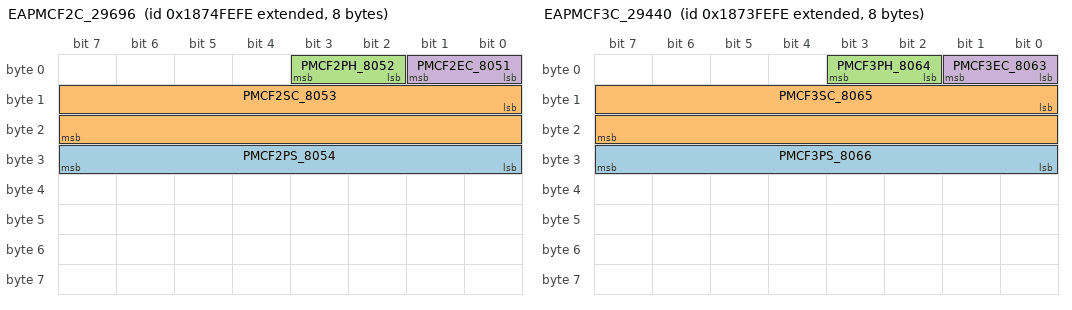
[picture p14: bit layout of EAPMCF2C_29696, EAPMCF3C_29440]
BO_ 2557804286 EAPMCF2C_29696: 8 Vector__XXX
 SG_ PMCF2PS_8054 : 24|8@1+ (0.5,0) [0.0|127.5] "%" Vector__XXX
 SG_ PMCF2SC_8053 : 8|16@1+ (0.5,0) [0.0|32767.5] "rpm" Vector__XXX
 SG_ PMCF2PH_8052 : 2|2@1+ (1,0) [0.0|3.0] "" Vector__XXX
 SG_ PMCF2EC_8051 : 0|2@1+ (1,0) [0.0|3.0] "" Vector__XXX

BO_ 2557738750 EAPMCF3C_29440: 8 Vector__XXX
 SG_ PMCF3PS_8066 : 24|8@1+ (0.5,0) [0.0|127.5] "%" Vector__XXX
 SG_ PMCF3SC_8065 : 8|16@1+ (0.5,0) [0.0|32767.5] "rpm" Vector__XXX
 SG_ PMCF3PH_8064 : 2|2@1+ (1,0) [0.0|3.0] "" Vector__XXX
 SG_ PMCF3EC_8063 : 0|2@1+ (1,0) [0.0|3.0] "" Vector__XXX

BO_ 2557673214 ODMCC_29184: 37 Vector__XXX
 SG_ ODMFB5CC_8203 : 272|24@1+ (1,0) [0.0|16449535.0] "" Vector__XXX
 SG_ ODMFB5CC_8202 : 248|24@1+ (1,0) [0.0|16449535.0] "" Vector__XXX
 SG_ ODMFB5CC_8201 : 224|24@1+ (1,0) [0.0|16449535.0] "" Vector__XXX
 SG_ ODMFB5CC_8200 : 200|24@1+ (1,0) [0.0|16449535.0] "" Vector__XXX
 SG_ ODMFB5CC_8199 : 176|24@1+ (1,0) [0.0|16449535.0] "" Vector__XXX
 SG_ ODMFB7CC_8198 : 152|24@1+ (1,0) [0.0|16449535.0] "" Vector__XXX
 SG_ ODMFB6CC_8197 : 128|24@1+ (1,0) [0.0|16449535.0] "" Vector__XXX
 SG_ ODMFB5CC_8196 : 104|24@1+ (1,0) [0.0|16449535.0] "" Vector__XXX
 SG_ ODMFB4CC_8195 : 80|24@1+ (1,0) [0.0|16449535.0] "" Vector__XXX
 SG_ ODMFB2CC_8193 : 32|24@1+ (1,0) [0.0|16449535.0] "" Vector__XXX
 SG_ ODMFB3CC_8194 : 56|24@1+ (1,0) [0.0|16449535.0] "" Vector__XXX
 SG_ ODMFB1CC_8192 : 8|24@1+ (1,0) [0.0|16449535.0] "" Vector__XXX
 SG_ ODMCIN_8191 : 0|8@1+ (1,0) [0.0|255.0] "" Vector__XXX

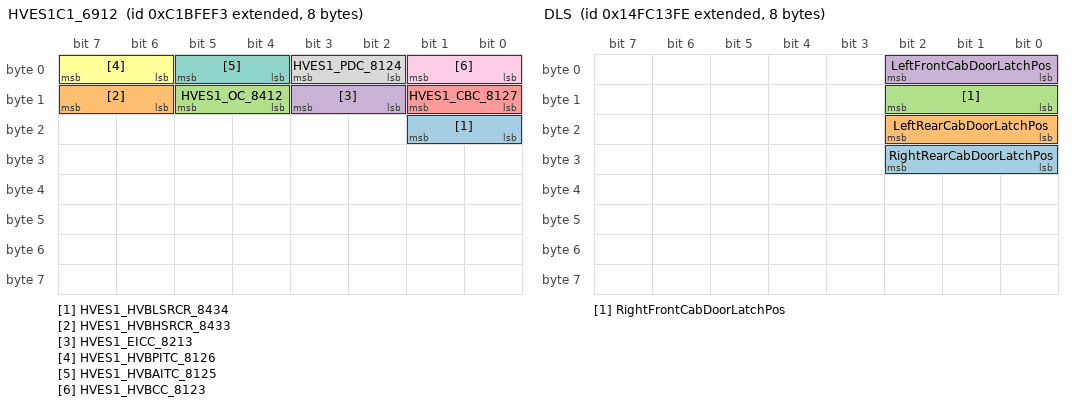
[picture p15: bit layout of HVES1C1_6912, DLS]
BO_ 2350644979 HVES1C1_6912: 8 Battery_Management_Cntrl_1
 SG_ HVES1_HVBLSRCR_8434 : 16|2@1+ (1,0) [0.0|3.0] "" Vector__XXX
 SG_ HVES1_HVBHSRCR_8433 : 14|2@1+ (1,0) [0.0|3.0] "" Vector__XXX
 SG_ HVES1_OC_8412 : 12|2@1+ (1,0) [0.0|3.0] "" Vector__XXX
 SG_ HVES1_EICC_8213 : 10|2@1+ (1,0) [0.0|3.0] "" Vector__XXX
 SG_ HVES1_CBC_8127 : 8|2@1+ (1,0) [0.0|3.0] "" Vector__XXX
 SG_ HVES1_HVBPITC_8126 : 6|2@1+ (1,0) [0.0|3.0] "" Vector__XXX
 SG_ HVES1_HVBAITC_8125 : 4|2@1+ (1,0) [0.0|3.0] "" Vector__XXX
 SG_ HVES1_PDC_8124 : 2|2@1+ (1,0) [0.0|3.0] "" Vector__XXX
 SG_ HVES1_HVBCC_8123 : 0|2@1+ (1,0) [0.0|3.0] "" Vector__XXX

BO_ 2566658558 PLST1: 8 Vector__XXX
 SG_ TotalHaulCycleCount : 32|32@1+ (1,0) [0.0|4211081215.0] "" Vector__XXX
 SG_ TotalDeliveredPayloadWeight : 0|32@1+ (100,0) [0.0|421108121500.0] "kg" Vector__XXX

BO_ 2566658302 PLST2: 8 Vector__XXX
 SG_ TotalPayloadTransactionCount : 0|32@1+ (1,0) [0.0|4211081215.0] "" Vector__XXX

BO_ 2499549182 PLT1: 8 Vector__XXX

BO_ 2499548926 PLT2: 8 Vector__XXX

BO_ 2499548670 VEP6: 8 Vector__XXX

BO_ 2499548158 DLS: 8 Vector__XXX
 SG_ RightRearCabDoorLatchPos : 24|3@1+ (1,0) [0.0|7.0] "" Vector__XXX
 SG_ LeftRearCabDoorLatchPos : 16|3@1+ (1,0) [0.0|7.0] "" Vector__XXX
 SG_ RightFrontCabDoorLatchPos : 8|3@1+ (1,0) [0.0|7.0] "" Vector__XXX
 SG_ LeftFrontCabDoorLatchPos : 0|3@1+ (1,0) [0.0|7.0] "" Vector__XXX

BO_ 2499547902 CDC: 8 Vector__XXX
 SG_ MirrorRight2HeatCmd : 54|2@1+ (1,0) [0.0|3.0] "" Vector__XXX
 SG_ MirrorLeft2HeatCmd : 52|2@1+ (1,0) [0.0|3.0] "" Vector__XXX
 SG_ MirrorRight1HeatCmd : 50|2@1+ (1,0) [0.0|3.0] "" Vector__XXX
 SG_ MirrorLeft1HeatCmd : 48|2@1+ (1,0) [0.0|3.0] "" Vector__XXX
 SG_ MirrorRight2VerticalCmd : 46|2@1+ (1,0) [0.0|3.0] "" Vector__XXX
 SG_ MirrorRight2HorizontalCmd : 44|2@1+ (1,0) [0.0|3.0] "" Vector__XXX
 SG_ MirrorLeft2VerticalCmd : 42|2@1+ (1,0) [0.0|3.0] "" Vector__XXX
 SG_ MirrorLeft2HorizontalCmd : 40|2@1+ (1,0) [0.0|3.0] "" Vector__XXX
 SG_ MirrorRight1VerticalCmd : 38|2@1+ (1,0) [0.0|3.0] "" Vector__XXX
 SG_ MirrorRight1HorizontalCmd : 36|2@1+ (1,0) [0.0|3.0] "" Vector__XXX
 SG_ MirrorLeft1VerticalCmd : 34|2@1+ (1,0) [0.0|3.0] "" Vector__XXX
 SG_ MirrorLeft1HorizontalCmd : 32|2@1+ (1,0) [0.0|3.0] "" Vector__XXX
 SG_ RightRearWindowPosCmd : 27|3@1+ (1,0) [0.0|7.0] "" Vector__XXX
 SG_ LeftRearWindowPosCmd : 24|3@1+ (1,0) [0.0|7.0] "" Vector__XXX
 SG_ RightFrontWindowPosCmd : 19|3@1+ (1,0) [0.0|7.0] "" Vector__XXX
 SG_ LeftFrontWindowPosCmd : 16|3@1+ (1,0) [0.0|7.0] "" Vector__XXX
 SG_ RemoteCabDoorLockReq : 8|3@1+ (1,0) [0.0|7.0] "" Vector__XXX
 SG_ DoorsLockActCmd : 0|3@1+ (1,0) [0.0|7.0] "" Vector__XXX

BO_ 2566656510 TGFI: 8 Vector__XXX
 SG_ EngTotalGasIdleFuelVolumeUsed : 32|32@1+ (0.5,0) [0.0|2105540607.5] "m³" Vector__XXX
 SG_ EngTotalGasFuelVolumeUsed : 0|32@1+ (0.5,0) [0.0|2105540607.5] "m³" Vector__XXX

BO_ 2565929214 ADASIS3: 8 Vector__XXX

BO_ 2565928958 ADASIS2: 8 Vector__XXX

BO_ 2565928702 ADASIS1: 8 Vector__XXX

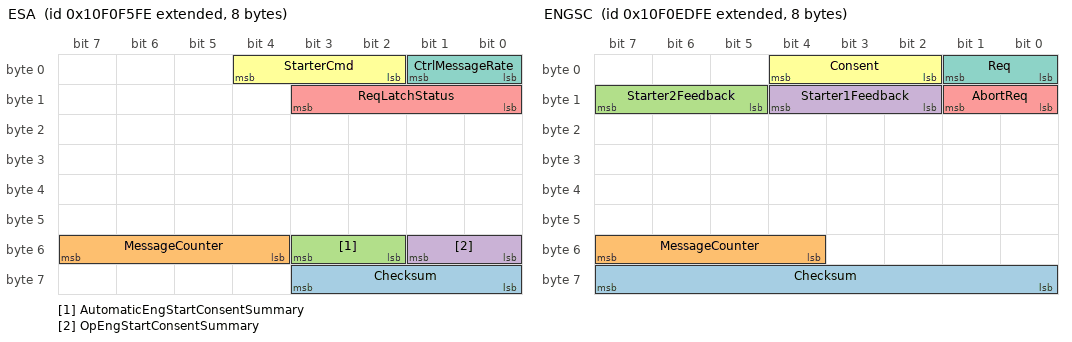
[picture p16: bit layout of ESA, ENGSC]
BO_ 2431710718 ESA: 8 Vector__XXX
 SG_ Checksum : 56|4@1+ (1,0) [0.0|15.0] "" Vector__XXX
 SG_ MessageCounter : 52|4@1+ (1,0) [0.0|15.0] "" Vector__XXX
 SG_ AutomaticEngStartConsentSummary : 50|2@1+ (1,0) [0.0|3.0] "" Vector__XXX
 SG_ OpEngStartConsentSummary : 48|2@1+ (1,0) [0.0|3.0] "" Vector__XXX
 SG_ ReqLatchStatus : 8|4@1+ (1,0) [0.0|15.0] "" Vector__XXX
 SG_ StarterCmd : 2|3@1+ (1,0) [0.0|7.0] "" Vector__XXX
 SG_ CtrlMessageRate : 0|2@1+ (1,0) [0.0|3.0] "" Vector__XXX

BO_ 2431708670 ENGSC: 8 Vector__XXX
 SG_ Checksum : 56|8@1+ (1,0) [0.0|255.0] "" Vector__XXX
 SG_ MessageCounter : 52|4@1+ (1,0) [0.0|15.0] "" Vector__XXX
 SG_ Starter2Feedback : 13|3@1+ (1,0) [0.0|7.0] "" Vector__XXX
 SG_ Starter1Feedback : 10|3@1+ (1,0) [0.0|7.0] "" Vector__XXX
 SG_ AbortReq : 8|2@1+ (1,0) [0.0|3.0] "" Vector__XXX
 SG_ Consent : 2|3@1+ (1,0) [0.0|7.0] "" Vector__XXX
 SG_ Req : 0|2@1+ (1,0) [0.0|3.0] "" Vector__XXX

BO_ 2566661118 LFC2: 8 Vector__XXX
 SG_ EngTotalDieselFuelDemand : 0|32@1+ (0.5,0) [0.0|2105540607.5] "L" Vector__XXX

BO_ 2633769726 EEC19: 8 Vector__XXX
 SG_ TotalEngEnergy : 0|32@1+ (1,0) [0.0|4211081215.0] "kWh" Vector__XXX

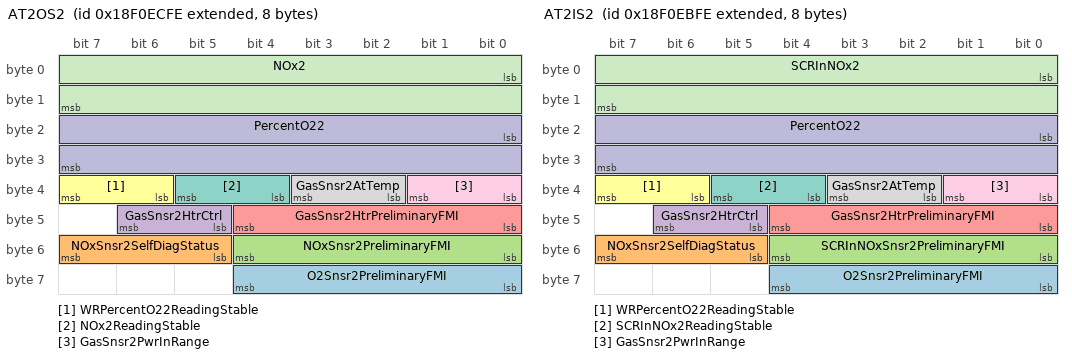
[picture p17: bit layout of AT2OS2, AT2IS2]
BO_ 2565926142 AT2OS2: 8 Vector__XXX
 SG_ O2Snsr2PreliminaryFMI : 56|5@1+ (1,0) [0.0|31.0] "" Vector__XXX
 SG_ NOxSnsr2SelfDiagStatus : 53|3@1+ (1,0) [0.0|7.0] "" Vector__XXX
 SG_ NOxSnsr2PreliminaryFMI : 48|5@1+ (1,0) [0.0|31.0] "" Vector__XXX
 SG_ GasSnsr2HtrCtrl : 45|2@1+ (1,0) [0.0|3.0] "" Vector__XXX
 SG_ GasSnsr2HtrPreliminaryFMI : 40|5@1+ (1,0) [0.0|31.0] "" Vector__XXX
 SG_ WRPercentO22ReadingStable : 38|2@1+ (1,0) [0.0|3.0] "" Vector__XXX
 SG_ NOx2ReadingStable : 36|2@1+ (1,0) [0.0|3.0] "" Vector__XXX
 SG_ GasSnsr2AtTemp : 34|2@1+ (1,0) [0.0|3.0] "" Vector__XXX
 SG_ GasSnsr2PwrInRange : 32|2@1+ (1,0) [0.0|3.0] "" Vector__XXX
 SG_ PercentO22 : 16|16@1+ (0.000514,-12) [-12.0|21.02707] "%" Vector__XXX
 SG_ NOx2 : 0|16@1+ (0.05,-200) [-200.0|3012.75] "ppm" Vector__XXX

BO_ 2565925886 AT2IS2: 8 Vector__XXX
 SG_ O2Snsr2PreliminaryFMI : 56|5@1+ (1,0) [0.0|31.0] "" Vector__XXX
 SG_ NOxSnsr2SelfDiagStatus : 53|3@1+ (1,0) [0.0|7.0] "" Vector__XXX
 SG_ SCRInNOxSnsr2PreliminaryFMI : 48|5@1+ (1,0) [0.0|31.0] "" Vector__XXX
 SG_ GasSnsr2HtrCtrl : 45|2@1+ (1,0) [0.0|3.0] "" Vector__XXX
 SG_ GasSnsr2HtrPreliminaryFMI : 40|5@1+ (1,0) [0.0|31.0] "" Vector__XXX
 SG_ WRPercentO22ReadingStable : 38|2@1+ (1,0) [0.0|3.0] "" Vector__XXX
 SG_ SCRInNOx2ReadingStable : 36|2@1+ (1,0) [0.0|3.0] "" Vector__XXX
 SG_ GasSnsr2AtTemp : 34|2@1+ (1,0) [0.0|3.0] "" Vector__XXX
 SG_ GasSnsr2PwrInRange : 32|2@1+ (1,0) [0.0|3.0] "" Vector__XXX
 SG_ PercentO22 : 16|16@1+ (0.000514,-12) [-12.0|21.02707] "%" Vector__XXX
 SG_ SCRInNOx2 : 0|16@1+ (0.05,-200) [-200.0|3012.75] "ppm" Vector__XXX

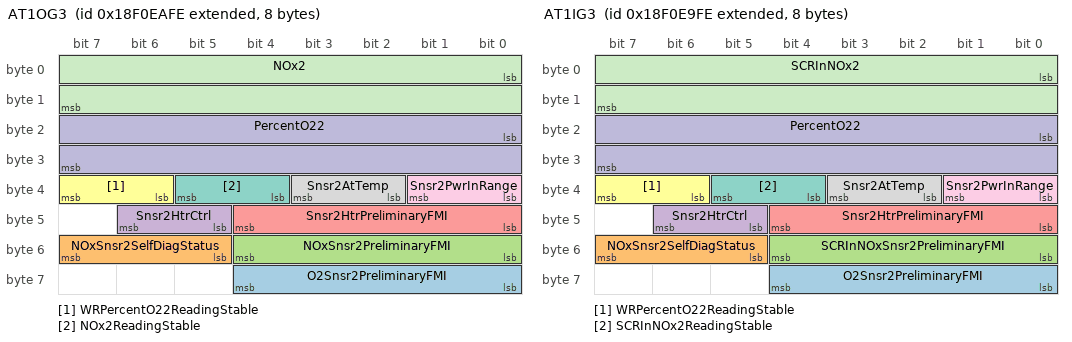
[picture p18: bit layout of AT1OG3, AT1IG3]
BO_ 2565925630 AT1OG3: 8 Vector__XXX
 SG_ O2Snsr2PreliminaryFMI : 56|5@1+ (1,0) [0.0|31.0] "" Vector__XXX
 SG_ NOxSnsr2SelfDiagStatus : 53|3@1+ (1,0) [0.0|7.0] "" Vector__XXX
 SG_ NOxSnsr2PreliminaryFMI : 48|5@1+ (1,0) [0.0|31.0] "" Vector__XXX
 SG_ Snsr2HtrCtrl : 45|2@1+ (1,0) [0.0|3.0] "" Vector__XXX
 SG_ Snsr2HtrPreliminaryFMI : 40|5@1+ (1,0) [0.0|31.0] "" Vector__XXX
 SG_ WRPercentO22ReadingStable : 38|2@1+ (1,0) [0.0|3.0] "" Vector__XXX
 SG_ NOx2ReadingStable : 36|2@1+ (1,0) [0.0|3.0] "" Vector__XXX
 SG_ Snsr2AtTemp : 34|2@1+ (1,0) [0.0|3.0] "" Vector__XXX
 SG_ Snsr2PwrInRange : 32|2@1+ (1,0) [0.0|3.0] "" Vector__XXX
 SG_ PercentO22 : 16|16@1+ (0.000514,-12) [-12.0|21.02707] "%" Vector__XXX
 SG_ NOx2 : 0|16@1+ (0.05,-200) [-200.0|3012.75] "ppm" Vector__XXX

BO_ 2565925374 AT1IG3: 8 Vector__XXX
 SG_ O2Snsr2PreliminaryFMI : 56|5@1+ (1,0) [0.0|31.0] "" Vector__XXX
 SG_ NOxSnsr2SelfDiagStatus : 53|3@1+ (1,0) [0.0|7.0] "" Vector__XXX
 SG_ SCRInNOxSnsr2PreliminaryFMI : 48|5@1+ (1,0) [0.0|31.0] "" Vector__XXX
 SG_ Snsr2HtrCtrl : 45|2@1+ (1,0) [0.0|3.0] "" Vector__XXX
 SG_ Snsr2HtrPreliminaryFMI : 40|5@1+ (1,0) [0.0|31.0] "" Vector__XXX
 SG_ WRPercentO22ReadingStable : 38|2@1+ (1,0) [0.0|3.0] "" Vector__XXX
 SG_ SCRInNOx2ReadingStable : 36|2@1+ (1,0) [0.0|3.0] "" Vector__XXX
 SG_ Snsr2AtTemp : 34|2@1+ (1,0) [0.0|3.0] "" Vector__XXX
 SG_ Snsr2PwrInRange : 32|2@1+ (1,0) [0.0|3.0] "" Vector__XXX
 SG_ PercentO22 : 16|16@1+ (0.000514,-12) [-12.0|21.02707] "%" Vector__XXX
 SG_ SCRInNOx2 : 0|16@1+ (0.05,-200) [-200.0|3012.75] "ppm" Vector__XXX

BO_ 2364598526 TFAC2: 8 Vector__XXX
 SG_ FuelAct4CtrlCmd : 48|16@1+ (0.0025,0) [0.0|160.6375] "%" Vector__XXX
 SG_ FuelAct3CtrlCmd : 32|16@1+ (0.0025,0) [0.0|100.0] "%" Vector__XXX

BO_ 2558525182 TSIC_32512: 8 Vector__XXX
 SG_ Num7586 : 24|8@1+ (1,0) [0.0|255.0] "" Vector__XXX
 SG_ Location_7585 : 16|8@1+ (1,0) [0.0|0.0] "" Vector__XXX
 SG_ Num_7584 : 8|8@1+ (1,0) [0.0|250.0] "" Vector__XXX
 SG_ NumOfTireSensors_7583 : 0|8@1+ (1,0) [0.0|250.0] "" Vector__XXX

BO_ 2350841598 ALTC: 8 Vector__XXX
 SG_ TrqRampMaxSpdCmd : 32|8@1+ (32,0) [0.0|8000.0] "rpm" Vector__XXX
 SG_ TrqRampTimeCmd : 24|8@1+ (0.1,0) [0.1|25.0] "s" Vector__XXX
 SG_ ExcitationMaxCurrentLmt : 16|8@1+ (0.25,0) [0.0|62.5] "A" Vector__XXX
 SG_ SetpointVoltageCmd : 0|16@1+ (0.001,0) [0.0|64.255] "V" Vector__XXX

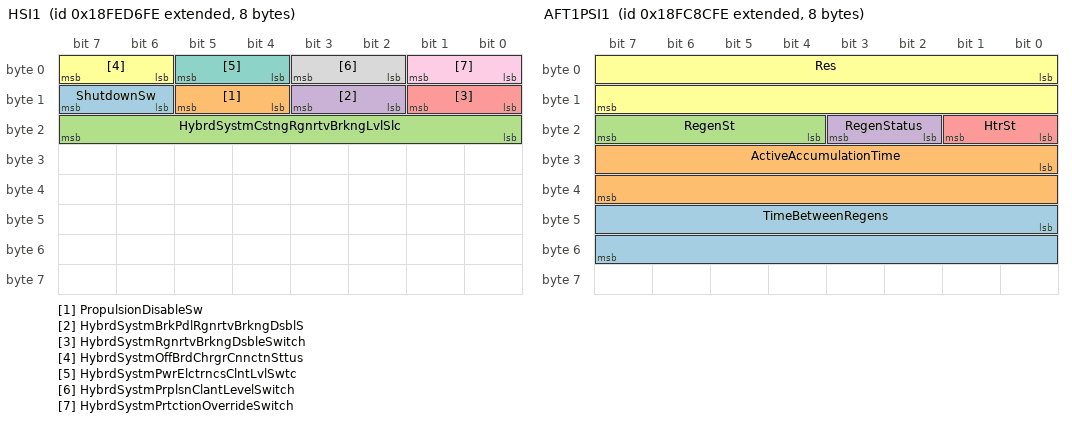
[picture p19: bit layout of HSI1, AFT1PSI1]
BO_ 2566838014 HSI1: 8 Vector__XXX
 SG_ ShutdownSw : 14|2@1+ (1,0) [0.0|3.0] "" Vector__XXX
 SG_ PropulsionDisableSw : 12|2@1+ (1,0) [0.0|3.0] "" Vector__XXX
 SG_ HybrdSystmCstngRgnrtvBrkngLvlSlc : 16|8@1+ (0.4,0) [0.0|100.0] "%" Vector__XXX
 SG_ HybrdSystmBrkPdlRgnrtvBrkngDsblS : 10|2@1+ (1,0) [0.0|3.0] "" Vector__XXX
 SG_ HybrdSystmRgnrtvBrkngDsbleSwitch : 8|2@1+ (1,0) [0.0|3.0] "" Vector__XXX
 SG_ HybrdSystmOffBrdChrgrCnnctnSttus : 6|2@1+ (1,0) [0.0|3.0] "" Vector__XXX
 SG_ HybrdSystmPwrElctrncsClntLvlSwtc : 4|2@1+ (1,0) [0.0|3.0] "" Vector__XXX
 SG_ HybrdSystmPrplsnClantLevelSwitch : 2|2@1+ (1,0) [0.0|3.0] "" Vector__XXX
 SG_ HybrdSystmPrtctionOverrideSwitch : 0|2@1+ (1,0) [0.0|3.0] "" Vector__XXX

BO_ 2566761726 EFI: 8 Vector__XXX
 SG_ EngIdleFuelFlowRateThreshold : 8|32@1+ (0.001,0) [0.0|4211081.215] "L/h" Vector__XXX
 SG_ NmbrOfFlCnsmptnMntrngTransducers : 0|8@1+ (1,0) [0.0|250.0] "" Vector__XXX

BO_ 2566756350 LFI3: 8 Vector__XXX
 SG_ EngFuelReturnTemp : 8|8@1+ (1,-40) [-40.0|210.0] "°C" Vector__XXX
 SG_ EngFuelSupplyTemp : 0|8@1+ (1,-40) [-40.0|210.0] "°C" Vector__XXX

BO_ 2566756094 LFI2: 8 Vector__XXX
 SG_ EngFuelReturnFlowRate : 32|32@1+ (0.001,0) [0.0|4211081.215] "L/h" Vector__XXX
 SG_ EngFuelSupplyFlowRate : 0|32@1+ (0.001,0) [0.0|4211081.215] "L/h" Vector__XXX

BO_ 2566687998 AFT1PSI1: 8 Vector__XXX
 SG_ TimeBetweenRegens : 40|16@1+ (6,0) [0.0|385530.0] "s" Vector__XXX
 SG_ ActiveAccumulationTime : 24|16@1+ (6,0) [0.0|385530.0] "s" Vector__XXX
 SG_ RegenSt : 20|4@1+ (1,0) [0.0|15.0] "" Vector__XXX
 SG_ RegenStatus : 18|2@1+ (1,0) [0.0|3.0] "" Vector__XXX
 SG_ HtrSt : 16|2@1+ (1,0) [0.0|3.0] "" Vector__XXX
 SG_ Res : 0|16@1+ (1,0) [0.0|62500.0] "kohm" Vector__XXX

CM_ BO_ 2565866752  "Electronic Transmission Controller 2";
CM_ BO_ 2566843904  "Engine Temperature 1";
CM_ BO_ 2566844928  "Engine Fuel Economy Data";
CM_ BO_ 2566845952  "Engine Intake and Exhaust Pressure and Temperature Information";
CM_ BO_ 2566846208  "Vehicle Electrical Power Information";
CM_ BO_ 2566844806  "Cruise Control Status and Vehicle Speed Information";
CM_ BO_ 2565537345  "Used to comfirm that a message has been received by a module.";
CM_ BO_ 2566857216  "Feedback from the engine or motor controller to be used in conjunction with making torque/speed requests.  To be used with PGN 65312 and PGN 65313.";
CM_ BO_ 2365530368  "Feedback from the engine or motor controller to be used in conjunction with making torque/speed requests.  To be used with PGN 65312 and PGN 65314.";
CM_ BO_ 2365530123  "Used to request/limit torque and speed of an engine or motor.  To be used with PGN 65313 and PGN 65314.";
CM_ BO_ 2566834822  "Active diagnostic trouble codes";
CM_ BO_ 2564358137  "Memory Access Response / Output State Control";
CM_ BO_ 2432656519  "Infotaiment Button Status";
CM_ BO_ 2432656775  "Indicates the status of multiple operator controlled switches.";
CM_ BO_ 2365449728  "Used for information on a hydraulic brake system.";
CM_ BO_ 2566884352  "Torque Data of Engine";
CM_ BO_ 2566842396  "Vehicle dynamics information";
CM_ BO_ 2566877607  "Instrument Cluster Information";
CM_ BO_ 2364607475  "Data set 9 (thermal) for High Voltage Energy Storage pack (or system) 1.";
CM_ BO_ 2364607219  "Data set 8 (electrical data) for High Voltage Energy Storage pack (or system) 1.";
CM_ BO_ 2364606707  "Module Status message 1 for High Voltage Energy Storage pack (or system) 1.";
CM_ BO_ 2364552947  "Status data set 2 for High Voltage Energy Storage pack (or system) 1.";
CM_ BO_ 2633785075  "Historical data for High Voltage Energy Storage pack (or system) 1.";
CM_ BO_ 2566675955  "Configuration data for High Voltage Energy Storage pack (or system) 1.  Note that configuration data should not dynamically change during vehicle operation.";
CM_ BO_ 2364606963  "A collection of data that High Voltage Energy Storage 1 Thermal Management System sends to the Hybrid Controller.";
CM_ BO_ 2364580083  "Data set 7 (electrical) for High Voltage Energy Storage pack (or system) 1.";
CM_ BO_ 2364577523  "Status data set 1 for High Voltage Energy Storage pack (or system) 1.";
CM_ BO_ 2364577267  "Data set 6 (external or interface data) for High Voltage Energy Storage pack (or system) 1.";
CM_ BO_ 2364577011  "Data set 5 (electrical data) for High Voltage Energy Storage pack (or system) 1.";
CM_ BO_ 2364576755  "Data set 4 (electrical data) for High Voltage Energy Storage pack (or system) 1.";
CM_ BO_ 2364576499  "Data set 3 (thermal data) for High Voltage Energy Storage pack (or system) 1.";
CM_ BO_ 2364576243  "Data set 2 (electrical data) for High Voltage Energy Storage pack (or system) 1.";
CM_ BO_ 2364575987  "Data set 1 (electrical data) for High Voltage Energy Storage pack (or system) 1.";
CM_ BO_ 2558263038  "Electrified Accessory Power Electronics Coolant Pump Command - The command message to the electrified accessory: Power Electronics Coolant Pump.  See PGN 64511 for the corresponding status message.";
CM_ BO_ 2558197502  "Electrified Accessory Propulsion Motor Coolant Pump Command - The command message to the electrified accessory: Propulsion Motor Coolant pump.  See PGN 64510 for the corresponding status message.";
CM_ BO_ 2558131966  "Electrified Accessory Propulsion Motor Oil Pump Command - The command message to the electrified accessory: Propulsion Motor Oil pump.  See PGN 64509 for the corresponding status message.";
CM_ BO_ 2558066430  "Electrified Accessory Power Electronics Coolant Fan 1 Command - The command message to the electrified accessory: Power Electronics Coolant Fan 1.  See PGN 64508 for the corresponding status message.";
CM_ BO_ 2558000894  "Electrified Accessory Power Electronics Coolant Fan 2 Command - The command message to the electrified accessory: Power Electronics Coolant Fan 2.  See PGN 64507 for the corresponding status message.";
CM_ BO_ 2557935358  "Electrified Accessory Power Electronics Coolant Fan 3 Command - The command message to the electrified accessory: Power Electronics Coolant Fan 3.  See PGN 64506 for the corresponding status message.";
CM_ BO_ 2557869822  "Electrified Accessory Propulsion Motor Coolant Fan 1 Command - The command message to the electrified accessory: Propulsion Motor Coolant Fan 1.  See PGN 64505 for the corresponding status message.";
CM_ BO_ 2557804286  "Electrified Accessory Propulsion Motor Coolant Fan 2 Command - The command message to the electrified accessory: Propulsion Motor Coolant Fan 2.  See PGN 64504 for the corresponding status message.";
CM_ BO_ 2557738750  "Electrified Accessory Propulsion Motor Coolant Fan 3 Command - The command message to the electrified accessory: Propulsion Motor Coolant Fan 3.  See PGN 64503 for the corresponding status message.";
CM_ BO_ 2350644979  "High Voltage Energy Storage 1 Control 1 - Control commands to be sent to High Voltage Energy Storage pack (or system) 1.";
CM_ BO_ 2566658558  "Payload System Totals 1
Payload measurement system accumulators related to the haul cycle productivity.";
CM_ BO_ 2566658302  "Payload System Totals 2
Payload measurement system accumulators.";
CM_ BO_ 2499549182  "Payload Temperature 1
Payload temperatures";
CM_ BO_ 2499548926  "Payload Temperature 2
Payload temperatures";
CM_ BO_ 2499548670  "Vehicle Electrical Power 6
Voltage and current measurements for batteries 3 and 4.";
CM_ BO_ 2499548158  "Door Latch Status
This message provides status of the cabin door  latches. Doors are numbered left to right, front to back.";
CM_ BO_ 2499547902  "Cab Door Control
This message requests or commands the cabin door functionality; door latches, windows, and mirrors. Doors are numbered left to right, front to back.";
CM_ BO_ 2566656510  "Total Gaseous Fuel Information
Reports the total fuel information of systems using gaseous fuel.";
CM_ BO_ 2565929214  "Advanced Driver Assistance Systems Interface Specification 3
Refer to ADASIS for specific message and parameter definitions. See the ADASIS1  (PGN xxx) for more information.";
CM_ BO_ 2565928958  "Advanced Driver Assistance Systems Interface Specification 2
Refer to ADASIS for specific message and parameter  definitions. See ADASIS1 (PGN 61686) for more information.";
CM_ BO_ 2565928702  "Advanced Driver Assistance Systems Interface Specification 1
Advanced Driver Assistance Systems Interface Specification (ADASIS) defines parameters that describe the upcoming vehicle's environment, including the attributes about the current ...";
CM_ BO_ 2431710718  "Engine Start Arbitrator
Message from the engine start arbitrator, used to manage engine starts.
Default broadcast rate of 20 ms unless the arbitrator is transmitting Engine Start Control Message Rate (SPN 7752) indicating a switch to 250 ms or on ...";
CM_ BO_ 2431708670  "Engine Start Control
Message used to manage engine starts.
Default broadcast rate of 20 ms unless the sending  device has received Engine Start Control Message Rate (SPN 7752j) from the engine start arbitrator indicating a  switch to 250 ms or on ...";
CM_ BO_ 2566661118  "Fuel Consumption (Liquid) 2
Engine fuel consumption accumulators.";
CM_ BO_ 2633769726  "Electronic Engine Controller 19
Engine related parameters";
CM_ BO_ 2565926142  "Aftertreatment 2 Outlet Sensor 2
The purpose of this PGN is to group the aftertreatment outlet sensor data for bank 2.  These values include the NOx, %O2, status of the sensors with respect to the power being supplied and the heating element, ...";
CM_ BO_ 2565925886  "Aftertreatment 2 Intake Sensor 2
The purpose of this PGN is to group the aftertreatment intake sensor data for bank 2.  These values include the NOx, %O2, status of the sensors with respect to the power being supplied and the heating element, ...";
CM_ BO_ 2565925630  "Aftertreatment 1 Outlet Gas 3
The purpose of this PGN is to group the aftertreatment outlet sensor data for bank 1.  These values include the NOx, %O2, Status of the sensors with respect to the power being supplied and the heating element, errors ...";
CM_ BO_ 2565925374  "Aftertreatment 1 Intake Gas 3
The purpose of this PGN is to group the aftertreatment intake sensor data for bank 1.  These values include the NOx, %O2, Status of the sensors with respect to the power being supplied and the heating element, errors ...";
CM_ BO_ 2364598526  "Engine Throttle / Fuel Actuator Control Command 2
Used to control networked electronic throttle control actuator and/or fuel control actuator valves.
Otherwise, this PGN can be used to monitor commanded % positioning to electronic throttle control ...";
CM_ BO_ 2558525182  "Tire Sensor Identification Command - The tire sensor identification number command for each monitored tire.
The command will be used to program sensor identification numbers for individual tire. Since there are multiple tire sensors to report, the ...";
CM_ BO_ 2350841598  "Alternator Control
Parameters to control the alternator.";
CM_ BO_ 2566838014  "Hybrid System Inputs 1
This message can be sent by any controller that has hybrid system related information.";
CM_ BO_ 2566761726  "Engine Fuel Information
Configuration information for engine fuel system.";
CM_ BO_ 2566756350  "Fuel Information 3 (Liquid)
Message for reporting information associated with liquid fuel.";
CM_ BO_ 2566756094  "Fuel Information 2 (Liquid)
Message for reporting information associated with liquid fuel.";
CM_ BO_ 2566687998  "Aftertreatment 1 Particulate Sensor Information 1
This message contains information for the particulate sensor in bank 1 of a 2 bank system or the particulate sensor in a single bank system.
This sensor is downstream of the DPF.";
CM_ SG_ 2565866752 TransmissionSelectedGear "The gear that the transmission will attempt to achieve during the current shift if a shift is in progress,
or the next shift if one is pending";
CM_ SG_ 2565866752 TransmissionActualGearRatio "Actual ratio of input shaft speed to output shaft speed";
CM_ SG_ 2565866752 TransmissionCurrentGear "The gear currently engaged in the transmission or the last gear engaged while the transmission is in
the process of shifting to the new or selected gear";
CM_ SG_ 2565866752 TransmissionRqstedRange "Range selected by the operator.";
CM_ SG_ 2565866752 TransmissionCurrentRange "Range currently being commanded by the transmission control system.";
CM_ SG_ 2566843904 EngineCoolantTemperature "Temperature of the liquid in the engine cooling system.";
CM_ SG_ 2566843904 EngFuelTemperature1 "Temperature of fuel (or gass) passing through the first fuel control system. Se SPN 3468 for the second control system.";
CM_ SG_ 2566843904 EngineOilTemperature1 "Temperature of the engine lubricant.";
CM_ SG_ 2566843904 EngTurboOilTemperature "Temperature of the turbocharger lubricant.";
CM_ SG_ 2566843904 EngineIntercoolerTemperature "Not approved for use at Polaris at this time.";
CM_ SG_ 2566843904 EngineIntercoolerThermosatOpen "Not approved for use at Polaris at this time.
(The current position of the thermostat used to regulate the temperature of the engine intercooler.)";
CM_ SG_ 2566844928 EngineFuelRate "Amount of fuel consumed by engine per unit of time";
CM_ SG_ 2566844928 InstantaneousFuelEconomy "Current fuel economy at current vehicle velocity.";
CM_ SG_ 2566844928 AverageFuelEconomy "Average of instantaneous fuel economy for that segment of vehicle operation of interest.";
CM_ SG_ 2566844928 EngineThrottlePosition "The position of the valve used to regulatethe supply of a fluid, usually air or fuel/air mixture, to an engine.";
CM_ SG_ 2566845952 ParticulateTrapInletPressure "Not approved for use at Polaris at this time.";
CM_ SG_ 2566845952 EngTurboBoostPressure "The gauge pressure measurement of the air intake manifold.  If there are multiple air pressure sensors in the intake stream, this is the last one in flow direction before entering the combustion chamber.";
CM_ SG_ 2566845952 EngIntakeManifoldTemperature "Temperature of pre-combustion air found in intake manifold of engine air supply system.";
CM_ SG_ 2566845952 EngAirInletPressure "Absolue air pressure at inlet to intake manifold or air box.";
CM_ SG_ 2566845952 AirFilterDifferentialPressure "Not approved for use at Polaris at this time.";
CM_ SG_ 2566845952 EngExhaustGasTemperature "Temperature of combustion byproducts leaving the engine. See SPNs 2433 and 2434 for engines with more than one exhaust gas temperature measurement.";
CM_ SG_ 2566845952 CoolantFilterDiffPressure "Not approved for use at Polaris at this time.";
CM_ SG_ 2566846208 NetBatteryCurrent "Net flow of electrical current into/out of the battery or batteries.";
CM_ SG_ 2566846208 AlternatorCurrent "Measure of electrical current flow from the alternator. Alternator Current (High Range/Resolution) parameter SPN 1795 has a higher range and resolution of the same parameter.";
CM_ SG_ 2566846208 ChargingSystemPotential "Electrical potential measured at the charging system output. The charging system may be any device charging the batteries. This includes alternators, generators, solid state charger,
and other charging devices.";
CM_ SG_ 2566846208 BatteryPotential "This parameter measures the first souce of battery potential as measured at the input of the ECM/actuator etc. coming from one or more batteries, irrespective of the distance between the component
and the battery.";
CM_ SG_ 2566846208 KeyswitchBatteryPotential "Battery potential measured at the input of the electronic control unit supplied through a keyswitch or similar switching device.";
CM_ SG_ 2566844806 pCruiseCntrlCounter "Rolling Counter (ensures updated message is used).";
CM_ SG_ 2566844806 TwoSpeedAxleSwitch "Switch signal which indicates the current axle range.";
CM_ SG_ 2566844806 ParkingBrakeSwitch "Switch signal which indicates when the parking brake is set. In general the switch actuated by the operator's park brake control,
whether a pedal, lever, or other control mechanism.";
CM_ SG_ 2566844806 Wheel_BasedVehicleSpeed "Speed of the vehicle as calculated from wheel or tailshaft speed.";
CM_ SG_ 2566844806 CruiseCtrlActive "Cruise control is switched on.  It is not ensured that the engine is controlled by cruise control, as in the case of a large driver's demand the engine is controlled by the driver while
cruise control is active.";
CM_ SG_ 2566844806 CruiseCtrlEnableSwitch "Switch signal which indicates that it is possible to manage the cruise control function";
CM_ SG_ 2566844806 BrakeSwitch "Switch signal which indicates that the driver operated brake foot pedal is being pressed";
CM_ SG_ 2566844806 ClutchSwitch "Switch signal which indicates that the clutch pedal is being pressed.  It is necessary for a safe drivetrain behavior that the clutch switch is set before the clutch is opened (cruise control function).";
CM_ SG_ 2566844806 CruiseCtrlSetSwitch "Switch signal of the cruise control activator which indicates that the activator is in the position 'set'.";
CM_ SG_ 2566844806 CruiseCtrlCoastSwitch "Switch signal of the cruise control activator which indicates that the activator is in the position 'coast'";
CM_ SG_ 2566844806 CruiseCtrlResumeSwitch "Switch signal of the cruise control activator which indicates that the activator is in the position 'resume'";
CM_ SG_ 2566844806 CruiseCtrlAccelerateSwitch "Switch signal of the cruise control activator which indicates that the activator is in the position 'accelerate'";
CM_ SG_ 2566844806 CruiseCtrlSetSpeed "Value of set (chosen) velocity of velocity control system.";
CM_ SG_ 2566844806 pOdometerDriveBit "Alternate state (A->B, B->A) each time the vehicle has moved a defined distance (currently 40m).";
CM_ SG_ 2566844806 CruiseCtrlPauseSw "Switch signal which indicates the positon of the Cruise Control Pause Switch used on Remote Cruise Control applications. The Cruise Control Pause Switch signal temporarily
disables the Cruise Control function.";
CM_ SG_ 2566844806 pCCChecksum "XOR of bytes 0-6 (ensures data is valid before use)";
CM_ SG_ 2566844806 pCruiseEnableStatus "The Cruise Control System has been enabled by the operator.  (Amber Light)";
CM_ SG_ 2566857216 pVehicleSpeed "Indication of the current vehicle speed.";
CM_ SG_ 2566857216 pEngineTorque_Inst_Max "Maximum instantaneous torque available from the engine.";
CM_ SG_ 2566857216 pEngineTorque_Inst_Min "Minimum instantaneous torque available from the engine.";
CM_ SG_ 2566857216 pNorm_Acc_Pos "Indication of the current accelerator pedal position normalized to 0 to 100 %.";
CM_ SG_ 2365530368 pChecksum_520571 "Used to verify the signal path from the transmitting device to the receiving device. The message checksum is calculated using the first 7 data bytes, the message counter and the bytes of the message identifier.";
CM_ SG_ 2365530368 pMessageCounter_520570 "Message counter that increments by one for each transmission from 0 to 15 and then rolls over.
The message counter is used to detect situations where the transmitting ECU malfunction repeats the same frame all the time";
CM_ SG_ 2365530368 pEngineSpeed_520569 "Indication of the current engine or motor speed.";
CM_ SG_ 2365530368 pEngineTorque_Driver_Demanded "Indication of the driver demanded engine or motor output torque.";
CM_ SG_ 2365530368 pEngineTorque "Indication of the actual engine or motor output torque.  Estimated torque is acceptable if actual is not available.";
CM_ SG_ 2365530368 pSource_Address_Ctrling_Device "Indication of the source address of the device from which the torque/speed request is being honored.  If an internal torque request is being honored, the controller will transmit its own source address.";
CM_ SG_ 2365530123 pEngCtlMode "Defines which sort of command is used.  Used to tell the engine or motor controller the type of torque/speed request or limit to use.";
CM_ SG_ 2365530123 pEngReqSpeedLimit "used when the pEngine Control Mode is in a speed request or limit mode. This value shall be ignored by the controller when pEngine Control Mode is set to No Control Request, Engine Torque Request, Engine Torque Limit, or any undefined values.";
CM_ SG_ 2365530123 pChecksum_520565 "Used to verify the signal path from the transmitting device to the receiving device. The message checksum is calculated using the first 7 data bytes, the message counter and the bytes of the message identifier.";
CM_ SG_ 2365530123 pMessageCounter_520564 "Message counter that increments by one for each transmission from 0 to 15 and then rolls over.";
CM_ SG_ 2365530123 pEngCtlReq "Used to tell the engine or motor controller what function is the requestor of the torque/speed request or limit.
This mode tells the engine control system the governor characteristics that are desired during speed control.";
CM_ SG_ 2365530123 pEngReqTorqueLimit "Used when the pEngine Control Mode is in a torque request or limit mode. This value shall be ignored by the controller when pEngine Control Mode is set to No Control Request, Engine Speed Request, Engine Speed Limit or any undefined values.
";
CM_ SG_ 2566834822 DTC5 "Diagnostic Trouble Code";
CM_ SG_ 2566834822 DTC4 "Diagnostic Trouble Code";
CM_ SG_ 2566834822 DTC3 "Diagnostic Trouble Code";
CM_ SG_ 2566834822 DTC2 "Diagnostic Trouble Code";
CM_ SG_ 2566834822 DTC1 "Diagnostic Trouble Code";
CM_ SG_ 2566834822 DM_FlashRedStopLamp "Flash status of the Red Stop Lamp";
CM_ SG_ 2566834822 DM_FlashProtectLamp "Flash status of the Stop Protect Lamp";
CM_ SG_ 2566834822 DM_FlashMalfuncIndicatorLamp "Flash status of the Malfunction Indicator Lamp";
CM_ SG_ 2566834822 DM_FlashAmberWarningLamp "Flash status of the Amber Warning Lamp";
CM_ SG_ 2566834822 DM_ProtectLampStatus "This lamp is used to relay trouble code informatio that is reporting a problem with a vehicle system that is most
probably not electronic subsystem related.";
CM_ SG_ 2566834822 DM_RedStopLampState "This lamp is uesed to relay trouble code information that is of a severe enought condition that it warrants stopping the vehicle.";
CM_ SG_ 2566834822 DM_AmberWrningLmpStatus "This lamp is used to relay trouble code information that is reporting a problem with the vehicle system but the vehicle need
not be immediately stopped.";
CM_ SG_ 2566834822 DM_MalfuncnIndicatorLampStatus "A lamp used to relay only emissions-related trouble code information.";
CM_ SG_ 2432656519 pInfotainmentJoystick2 "Switch signal which requests that all engine fueling and spark stop.";
CM_ SG_ 2432656519 pInfotainmentJoystick1 "Switch signal which requests that all engine fueling and spark stop.";
CM_ SG_ 2432656519 pInfotainmentRemoteButton01 "Volume Down";
CM_ SG_ 2432656519 pInfotainmentRemoteButton02 "Volume Up";
CM_ SG_ 2432656519 pInfotainmentRemoteButton03 "Tune Down";
CM_ SG_ 2432656519 pInfotainmentRemoteButton04 "Tune Up";
CM_ SG_ 2432656519 pInfotainmentRemoteButton05 "Source";
CM_ SG_ 2432656519 pInfotainmentRemoteButton06 "Mute";
CM_ SG_ 2432656519 pInfotainmentRemoteButton07 "ICOM";
CM_ SG_ 2432656519 pInfotainmentRemoteButton08 "COM";
CM_ SG_ 2432656519 pInfotainmentRemoteButton09 "Squelch (SQ) Down";
CM_ SG_ 2432656519 pInfotainmentRemoteButton10 "Squelch (SQ) Up";
CM_ SG_ 2432656519 pInfotainmentRemoteButton11 "Push To Talk (PTT)";
CM_ SG_ 2432656519 pInfotainmentRemoteButton12 "Preset";
CM_ SG_ 2432656775 pOperatorButton29 "Drive Mode - 1()";
CM_ SG_ 2432656775 pOperatorButton1 "Instrument Cluster Control - 1";
CM_ SG_ 2432656775 pOperatorButton2 "Instrument Cluster Control  - 2";
CM_ SG_ 2432656775 pOperatorButton3 "Headlamp - 1 (Low)";
CM_ SG_ 2432656775 pOperatorButton4 "Headlamp - 2 (High)";
CM_ SG_ 2432656775 pOperatorButton5 "Headlamp - 3 (Driving)";
CM_ SG_ 2432656775 pOperatorButton6 "Turn - 1 (Left)";
CM_ SG_ 2432656775 pOperatorButton7 "Turn - 2 (Right)";
CM_ SG_ 2432656775 pOperatorButton8 "Turn - 3 (Cancel)";
CM_ SG_ 2432656775 pOperatorButton9 "Hazard";
CM_ SG_ 2432656775 pOperatorButton10 "Cruise - 1 (On)";
CM_ SG_ 2432656775 pOperatorButton11 "Cruise - 2 (Set)";
CM_ SG_ 2432656775 pOperatorButton12 "Cruise - 3 (Accel)";
CM_ SG_ 2432656775 pOperatorButton13 "Horn";
CM_ SG_ 2432656775 pOperatorButton14 "Start";
CM_ SG_ 2432656775 pOperatorButton15 "Warmer - 1";
CM_ SG_ 2432656775 pOperatorButton16 "Warmer - 2";
CM_ SG_ 2432656775 pOperatorButton17 "Warmer - 3";
CM_ SG_ 2432656775 pOperatorButton18 "Warmer - 4";
CM_ SG_ 2432656775 pOperatorButton19 "Windshield Wiper";
CM_ SG_ 2432656775 pOperatorButton20 "Engine On";
CM_ SG_ 2432656775 pOperatorButton21 "Reverse";
CM_ SG_ 2432656775 pOperatorButton22 "Homelink 1";
CM_ SG_ 2432656775 pOperatorButton23 "Homelink 2";
CM_ SG_ 2432656775 pOperatorButton24 "Throttle Safety Switch - 1";
CM_ SG_ 2432656775 pOperatorButton25 "Windshield - 1 (Up)";
CM_ SG_ 2432656775 pOperatorButton26 "Windshield - 2 (Down)";
CM_ SG_ 2432656775 pOperatorButton27 "Hand Brake Switch";
CM_ SG_ 2432656775 pOperatorButton28 "Clutch Switch";
CM_ SG_ 2432656775 pSideStandStatus "Status of the side stand switch of a motorcycle";
CM_ SG_ 2365449728 HydBrakePressCircuit1 "Gague hydraulic pressure in circuit 1 of the hydraulic brake system. For single circuit systems use this SPN. For independant front/rear hydraulic circuits, use this SPN for front brake circuit pressure.";
CM_ SG_ 2365449728 HydBrakePressCircuit2 "Gague hydraulic pressure in circuit 2 of the hydraulic brake system. For independant front/rear hydraulic circuits, use this SPN for rear brake circuit pressure.";
CM_ SG_ 2365449728 HydBrkPressWarnStateCir1 "Signal which indicates whether the hydraulic brake pressure of circuit 1 is below the warning level.";
CM_ SG_ 2365449728 HydBrkPressWarnStateCir2 "Signal which indicates whether the hydraulic brake pressure of circuit 2 is below the warning level.";
CM_ SG_ 2365449728 HydBrkPressSupplyStateCir1 "Signal which indicates whether the hydraulic brake pressure supply of circuit 1 is reliable; that is, able to support continued braking.";
CM_ SG_ 2365449728 HydBrkPressSupplyStateCir2 "Signal which indicates whether the hydraulic brake pressure supply of circuit 2 is reliable; that is, able to support continued braking.";
CM_ SG_ 2365449728 HydBrakeFluidLevelSwitch "Signal which indicates whether the hydraulic fluid level in the reservoir(s) is sufficient.";
CM_ SG_ 2566884352 pCurrentRPMRatedTorque "Contains the rated torque for the current RPM (un-throttled and optimal spark).";
CM_ SG_ 2566884352 pEstimatedTorque "Estimated torque value based on current engine conditions.";
CM_ SG_ 2566884352 BrakeSwitch "Switch signal which indicates that the driver operated brake foot pedal is being pressed";
CM_ SG_ 2566884352 MessageChecksum_GM "The message checksum is used to verify the signal path from the transmitting device to the receiving device.";
CM_ SG_ 2566842396 CompassBearing "Present compass bearing of vehicle.";
CM_ SG_ 2566877607 pVolumeUnitsSelected "Active display volume units beased on user selection or auto-configuration.";
CM_ SG_ 2566877607 pTimeUnitsSelected "Active display time units beased on user selection or auto-configuration.";
CM_ SG_ 2566877607 pTemperatureUnitsSelected "Active display temperature units beased on user selection or auto-configuration.";
CM_ SG_ 2566877607 pPressureUnitsSelected "Active display pressure units beased on user selection or auto-configuration.";
CM_ SG_ 2566877607 pHighResTrip2Distance "Secondary distance travled during all or part of a journey.";
CM_ SG_ 2566877607 pDistanceUnitsSelected "Active display distance units beased on user selection or auto-configuration.";
CM_ SG_ 2566877607 pTPMSLearningStatus "Status of the Tire Pressure Monitor System learning process.";
CM_ SG_ 2566877607 pDisplayStatus "Status of the radio display to the radio stating what the display is showing";
CM_ SG_ 2381320220 NMEA_SID "Switch signal which indicates whether the accelerator pedal low idle switch is opened or closed.";
CM_ SG_ 2583298844 NMEA_SID "Switch signal which indicates whether the accelerator pedal low idle switch is opened or closed.";
CM_ SG_ 2314732060 NMEA_SID "Switch signal which indicates whether the accelerator pedal low idle switch is opened or closed.";
CM_ SG_ 2364607475 HVES1LoCellTModuNo_8243 "Identifies the location of the module containing the HVES1 Highest Cell Temperature (SPN 8075).";
CM_ SG_ 2364607475 HVES1LoCellTCellNo_8244 "Identifies the location of the HVES1 Highest Cell Temperature (SPN 8075) within the HVES1 Highest Cell Temperature Module Number (SPN 8241).";
CM_ SG_ 2364607475 HVES1HiCellTModuNo_8241 "Identifies the location of the module containing the HVES1 Highest Cell Voltage (SPN 5922).";
CM_ SG_ 2364607475 HVES1HiCellTCellNo_8242 "ntifies the location of HVES1 Highest Cell Voltage (SPN 5922) within the HVES1 Highest Cell Voltage Module Number (SPN 8236).";
CM_ SG_ 2364607219 HVES1AvgCellU_8240 "The average cell voltage in the High Voltage Energy Storage 1 pack (or system).";
CM_ SG_ 2364607219 HVES1LoCellUModuNo_8238 "Identifies the location of the module containing the HVES1 Lowest Cell Temperature (SPN 8076).";
CM_ SG_ 2364607219 HVES1LoCellUCellNo_8239 "Identifies the location of the HVES1 Lowest Cell Temperature (SPN 8076) within the HVES1 Lowest Cell Temperature Module Number (SPN 8243).";
CM_ SG_ 2364607219 HVES1HiCellUModuNo_8236 "Identifies the location of the module containing the HVES1 Highest Cell Voltage (SPN 5922).";
CM_ SG_ 2364607219 HVES1HiCellUCellNo_8237 "ntifies the location of HVES1 Highest Cell Voltage (SPN 5922) within the HVES1 Highest Cell Voltage Module Number (SPN 8236).";
CM_ SG_ 2364606707 HVES1M11OperlSts_8224 "Not Operational is used when the module is initializing or not able to function (e.g. internal module level monitors have failed).  Operational indicates that the module is fully functional.  Error is used when the module status is not known.";
CM_ SG_ 2364606707 HVES1M9OperlSts_8222 "Not Operational is used when the module is initializing or not able to function (e.g. internal module level monitors have failed).  Operational indicates that the module is fully functional.  Error is used when the module status is not known.";
CM_ SG_ 2364606707 HVES1M8OperlSts_8221 "Not Operational is used when the module is initializing or not able to function (e.g. internal module level monitors have failed).  Operational indicates that the module is fully functional.  Error is used when the module status is not known.";
CM_ SG_ 2364606707 HVES1M7OperlSts_8220 "Not Operational is used when the module is initializing or not able to function (e.g. internal module level monitors have failed).  Operational indicates that the module is fully functional.  Error is used when the module status is not known.";
CM_ SG_ 2364606707 HVES1M6OperlSts_8219 "Not Operational is used when the module is initializing or not able to function (e.g. internal module level monitors have failed).  Operational indicates that the module is fully functional.  Error is used when the module status is not known.";
CM_ SG_ 2364606707 HVES1M5OperlSts_8218 "Not Operational is used when the module is initializing or not able to function (e.g. internal module level monitors have failed).  Operational indicates that the module is fully functional.  Error is used when the module status is not known.";
CM_ SG_ 2364606707 HVES1M4OperlSts_8217 "Not Operational is used when the module is initializing or not able to function (e.g. internal module level monitors have failed).  Operational indicates that the module is fully functional.  Error is used when the module status is not known.";
CM_ SG_ 2364606707 HVES1M3OperlSts_8216 "Not Operational is used when the module is initializing or not able to function (e.g. internal module level monitors have failed).  Operational indicates that the module is fully functional.  Error is used when the module status is not known.";
CM_ SG_ 2364606707 HVES1M2OperlSts_8215 "Not Operational is used when the module is initializing or not able to function (e.g. internal module level monitors have failed).  Operational indicates that the module is fully functional.  Error is used when the module status is not known.";
CM_ SG_ 2364606707 HVES1M1OperlSts_8214 "Not Operational is used when the module is initializing or not able to function (e.g. internal module level monitors have failed).  Operational indicates that the module is fully functional.  Error is used when the module status is not known.";
CM_ SG_ 2364606707 HVES1M16OperlSts_8229 "Not Operational is used when the module is initializing or not able to function (e.g. internal module level monitors have failed).  Operational indicates that the module is fully functional.  Error is used when the module status is not known.";
CM_ SG_ 2364606707 HVES1M15OperlSts_8228 "Not Operational is used when the module is initializing or not able to function (e.g. internal module level monitors have failed).  Operational indicates that the module is fully functional.  Error is used when the module status is not known.";
CM_ SG_ 2364606707 HVES1M14OperlSts_8227 "Not Operational is used when the module is initializing or not able to function (e.g. internal module level monitors have failed).  Operational indicates that the module is fully functional.  Error is used when the module status is not known.";
CM_ SG_ 2364606707 HVES1M13OperlSts_8226 "Not Operational is used when the module is initializing or not able to function (e.g. internal module level monitors have failed).  Operational indicates that the module is fully functional.  Error is used when the module status is not known.";
CM_ SG_ 2364606707 HVES1M12OperlSts_8225 "Not Operational is used when the module is initializing or not able to function (e.g. internal module level monitors have failed).  Operational indicates that the module is fully functional.  Error is used when the module status is not known.";
CM_ SG_ 2364606707 HVES1M10OperlSts_8223 "Not Operational is used when the module is initializing or not able to function (e.g. internal module level monitors have failed).  Operational indicates that the module is fully functional.  Error is used when the module status is not known.";
CM_ SG_ 2364552947 HVES1CPLDToUndefCause_8114 "Indicates whether or not HVES1 charge power is being limited due to an undefined cause.";
CM_ SG_ 2364552947 HVES1CPLDTBT_8110 "Indicates whether or not HVES1 charge power is being limited due to battery temperature.";
CM_ SG_ 2364552947 HVES1CPLDTBOrCellV_8112 "Indicates whether or not HVES1 charge power is being limited due to a battery or cell voltage level.";
CM_ SG_ 2364552947 HVES1CPLDTBDiagcCdn_8111 "Indicates whether or not HVES1 charge power is being limited due to a battery diagnostic condition.";
CM_ SG_ 2364552947 HVES1CPLDTBCur_8113 "Indicates whether or not HVES1 charge power is being limited due to battery current.";
CM_ SG_ 2364552947 HVES1DPLDTStOfCha_8109 "Indicates whether or not HVES1 charge power is being limited due to state of charge.";
CM_ SG_ 2364552947 HVES1DPLDTStOfCha_8103 "Indicates whether or not HVES1 discharge power is being limited due to state of charge.";
CM_ SG_ 2364552947 HVES1DPLDToUndefCause_8108 "Indicates whether or not HVES1 discharge power is being limited due to an undefined cause.";
CM_ SG_ 2364552947 HVES1DPLDTBT_8104 "Indicates whether or not HVES1 discharge power is being limited due to battery temperature.";
CM_ SG_ 2364552947 HVES1DPLDTBOrCellV_8106 "Indicates whether or not HVES1 discharge power is being limited due to a battery or cell voltage level.";
CM_ SG_ 2364552947 HVES1DPLDTBDiagcCdn_8105 "Indicates whether or not HVES1 discharge power is being limited due to a battery diagnostic condition.";
CM_ SG_ 2364552947 HVES1DPLDTBCur_8107 "Indicates whether or not HVES1 discharge power is being limited due to battery current.";
CM_ SG_ 2633785075 HVES1TotEgyThput_8211 "The total energy throughput which has flowed through High Voltage Energy Storage 1 pack (or system).  This parameter is the sum of the absolute values of the Energy into and out of HVES1.  ";
CM_ SG_ 2633785075 HVES1TotAccumCha_8212 "The total accumulated amp hours which have flowed through High Voltage Energy Storage 1 pack (or system).  This parameter is the sum of the absolute values of the Ampere hours into and out of HVES1.  ";
CM_ SG_ 2633785075 HVES1StOfHealth_8121 "This value should begin at 100%, and end at 0% when “no” energy is able to be put in or taken out.  “No” could be absolute zero, or it could be some rated value of the pack.";
CM_ SG_ 2633785075 HVES1CtorOpenUndLoa_8122 "The current level shall be defined by the HVES manufacturer, but in general should be a level at which the contactor life may be reduced if repeated cycles occur.";
CM_ SG_ 2566675955 HVES1RecomMinSOC_8118 "Per the HVES manufacturer, this is the recommended minimum state of charge for High Voltage Energy Storage 1 pack (or system) operation.  Operating below this value may compromise HVES life.";
CM_ SG_ 2566675955 HVES1RecomMinOpergV_8116 "Per the HVES manufacturer, this is the minimum recommended voltage level for High Voltage Energy Storage 1 pack (or system) operation.  Operating below this value may compromise HVES life.";
CM_ SG_ 2566675955 HVES1RecomMinOpergT_8208 "Per the HVES manufacturer, this is the recommended minimum temperature for High Voltage Energy Storage 1 pack (or system) operation.  Operating below this value may damage HVES hardware, or compromise HVES life.";
CM_ SG_ 2566675955 HVES1RecomMaxSOC_8119 "Per the HVES manufacturer, this is the recommended maximum state of charge for High Voltage Energy Storage 1 pack (or system) operation.  Operating above this value may compromise HVES life.";
CM_ SG_ 2566675955 HVES1RecomMaxOpergV_8117 "Per the HVES manufacturer, this is the maximum recommended voltage level for High Voltage Energy Storage 1 pack (or system) operation.  Operating above this value may compromise HVES life.";
CM_ SG_ 2566675955 HVES1RecomMaxOpergT_8120 "Per the HVES manufacturer, this is the recommended maximum temperature for High Voltage Energy Storage 1 pack (or system) operation.  Operating above this value may damage HVES hardware, or compromise HVES life.";
CM_ SG_ 2566675955 HVES1NomVoltage_8115 "Per the HVES manufacturer, this is the nominal operating voltage of the High Voltage Energy Storage 1 pack (or system), e.g. “300V” or “600V”.";
CM_ SG_ 2566675955 HVES1CellMinVLim_8210 "Per the HVES manufacturer, this is the minimum cell voltage for High Voltage Energy Storage 1 pack (or system) operation.  Operating below this value may damage HVES hardware, or compromise HVES life.";
CM_ SG_ 2566675955 HVES1CellMaxVLim_8209 "Per the HVES manufacturer, this is the maximum cell voltage for High Voltage Energy Storage 1 pack (or system) operation.  Operating above this value may damage HVES hardware, or compromise HVES life.";
CM_ SG_ 2364606963 HVES1TMSSLIInPwr_8230 "In multiple HVES configurations, this is the low-voltage power consumed by the HVES1 Thermal Management System (TMS).   If there is only one HVES, or a single TMS for all HVES, then this represents the total low-voltage power consumed.  ";
CM_ SG_ 2364606963 HVES1TMSRelHum_8233 "When the High Voltage Energy Storage 1 Thermal Management System is equipped with a relative humidity sensor, this is the  measured Relative Humidity.";
CM_ SG_ 2364606963 HVES1TMSMode_8235 " The heat transfer medium may be (e.g. liquid or air).  The cooling system may be fans, liquid coolant, or a combination of mediums.  The system may include an air and/or liquid conditioning system with active Cooling, Heating, and/or Drying capabilities.";
CM_ SG_ 2364606963 HVES1TMSHighV_8231 "In multiple HVES configurations, this is the high-voltage power consumed by the HVES1 Thermal Management System (TMS).   If there is only one HVES, or a single TMS for all HVES, then this represents the total high voltage power consumed.";
CM_ SG_ 2364606963 HVES1TMSHeatrSts_8234 "This is the state of the High Voltage Energy Storage 1 heater";
CM_ SG_ 2364606963 HVES1TMSCpsr_8232 "When the High Voltage Energy Storage 1 Thermal Management System is equipped with an active cooling system (e.g. air conditioner), this is the Compressor Speed.";
CM_ SG_ 2364580083 HVES1MaxChaVLim_8090 "The maximum voltage level not to be exceeded while charging the High Voltage Energy Storage 1 pack (or system).  If this parameter is not supported, the maximum charge voltage should be limited to SPN 8117 (HVES1 Recommended Maximum Operating Voltage).";
CM_ SG_ 2364580083 HVES1DischaEgyCp_8205 "The amount of stored electrical energy in High Voltage Energy Storage 1 pack (or system) that is available for use by the hybrid system, i.e. “how full is the tank”.  See HVES1 Discharge Capacity (SPN 8079) for Ampere-hours (Ah).";
CM_ SG_ 2364580083 HVES1ChaEgyCp_8206 "The amount of stored electrical energy in High Voltage Energy Storage 1 pack (or system) that is available for use by the hybrid system, i.e. “how full is the tank”.  See HVES1 Discharge Capacity (SPN 8079) for Ampere-hours (Ah).";
CM_ SG_ 2364577523 HVES1StOfChaSts_8100 "Status of the High Voltage Energy Storage 1 pack (or system) State of Charge (SOC).  Note:  A given HVES controller may not support all of the states.";
CM_ SG_ 2364577523 HVES1OperationlSts_8414 "Provides feedback on where the HVES1 pack (or system) is in its operating spectrum, and includes feedback in response to the Operation Consent [i.e. HVES1 Operation Consent (SPN 8412)] and Power Down Command";
CM_ SG_ 2364577523 HVES1IntChaSts_8207 "Indicates that the charger in the HVES1 is on.  External chargers may use the External Energy Source Connection Status (SPN 7898) and related SPNs.";
CM_ SG_ 2364577523 HVES1InertiaSwtSts_8099 "Switch indicating that an impact has been sensed by the HVES1 pack (or system).   May require action.  For example, a controller may elect to take HVES1 off-line to reduce an electrocution hazard during or after a vehicle crash.";
CM_ SG_ 2364577523 HVES1HVILSts_8098 "Status of the High Voltage Interlock Loop from the viewpoint of the High Voltage Energy Storage 1 pack (or system).";
CM_ SG_ 2364577523 HVES1HVBusPsvIsoTstSts_8097 "Status of the high-voltage bus electrical passive isolation test as performed by the High Voltage Energy Storage 1 pack (or system).";
CM_ SG_ 2364577523 HVES1HVBusPrechaRlySt_8094 " Position of the high-voltage bus contactor pre-charge relay.  When this relay is closed, the High Voltage Energy Storage 1 pack (or system) is bringing the high-voltage bus up to its operating level.";
CM_ SG_ 2364577523 HVES1HVBusDiscnctWarn_8093 "Indicates that the High Voltage Energy Storage 1 pack (or system) is about to disconnect from the high voltage bus due to unacceptable conditions.";
CM_ SG_ 2364577523 HVES1HVBusCnctnSts_8413 "This parameter provides high level feedback on the HVES1 pack (or system) high voltage bus connection.  For specific contactor information, see  (SPN 8091),  (SPN 8095), and  (SPN 8094).";
CM_ SG_ 2364577523 HVES1HVBusAcvIsoTstSts_8096 "Status of the high-voltage bus electrical active isolation test as performed by the High Voltage Energy Storage 1 pack (or system).";
CM_ SG_ 2364577523 HVES1HVBCtorStPos_8091 " When this contactor is closed, the positive side of HVES1 is connected to the positive side.  In systems where all contactors are controlled as a single unit, this parameter may be used to convey the overall contactor status.";
CM_ SG_ 2364577523 HVES1HVBCtorStNeg_8092 " If a system controls the positive, negative, and center contactors as a single unit, then SPN 8091 should be used to convey overall contactor status.";
CM_ SG_ 2364577523 HVES1CtrOfPackCtorSt_8095 " When this contactor is closed, the positive half of the HVES1 pack (or system) is connected to the negative half.  If a system controls the positive, negative, and center contactors as a single unit, then SPN 8091 should be used.";
CM_ SG_ 2364577523 HVES1CellBalnSts_8101 "Indicates whether or not the cells in the High Voltage Energy Storage 1 pack (or system) are balanced.";
CM_ SG_ 2364577267 HVES1ElectronicsT_8204 "The temperature of the electronics or control modules in the High Voltage Energy Storage 1 pack (or system).  If there are mulitple temperature sensors then this parameter would be set to the maximum sensor reading.";
CM_ SG_ 2364577267 HVES1OutletCooltT_8089 "The temperature of liquid coolant as it exits the High Voltage Energy Storage 1 pack (or system).";
CM_ SG_ 2364577267 HVES1InletCooltT_8088 "The temperature of liquid coolant as it enters the High Voltage Energy Storage 1 pack (or system).";
CM_ SG_ 2364577267 HVES1IgVoltage_8087 "The voltage level at the ignition input of the High Voltage Energy Storage 1 pack (or system) controller.";
CM_ SG_ 2364577267 HVES1BusVoltage_8086 "The voltage level of the high voltage bus, as measured by the High Voltage Energy Storage 1 pack (or system) on the bus side (not the battery side) of its contactors.";
CM_ SG_ 2364577011 HVES1MinCellStOCha_8084 "Indicates the state of charge of the lowest-charged cell in the High Voltage Energy Storage 1 pack (or system).  0% means no charge remaining, 100% means the cell is fully charged.   If a single state of charge value covers more than one cell, the value";
CM_ SG_ 2364577011 HVES1MaxCellStOCha_8085 "Indicates the state of charge of the highest-charged cell in the High Voltage Energy Storage 1 pack (or system).  0% means no charge remaining, 100% means the cell is fully charged.  If a single state of charge value covers more than one cell";
CM_ SG_ 2364577011 HVES1DchaCurLim_8082 "The maximum permissible current flow out of the High Voltage Energy Storage 1 pack (or system).  This parameter is defined from the high voltage energy storage system's point of view.  A negative value represents current flowing out of";
CM_ SG_ 2364577011 HVES1ChaCurLim_8083 "The maximum permissible current flow into the High Voltage Energy Storage 1 pack (or system).  This parameter is defined from the high voltage energy storage system's point of view.  A positive value represents current flowing into";
CM_ SG_ 2364576755 HVES1DischargeCap_8079 "The amount of stored electrical charge in the High Voltage Energy Storage 1 pack (or system) that is available for use by the hybrid system, i.e. “how full is the tank”.  See HVES1 Discharge Energy Capacity (SPN 8205) for kilowatt-hours (kWh).";
CM_ SG_ 2364576755 HVES1ChargeCap_8080 "The amount of unused electrical charge storage in the High Voltage Energy Storage 1 pack (or system) that is available to be filled by charging, i.e. “how much empty space is remaining in the tank”.  See HVES1 Charge Energy Capacity (SPN 8206)";
CM_ SG_ 2364576755 HVES1CellBalnCt_8081 "The number of cells that are currently being balanced in the High Voltage Energy Storage 1 pack (or system).";
CM_ SG_ 2364576499 HVES1LowestCellT_8076 "The lowest temperature level reported by any cell in the High Voltage Energy Storage 1 pack (or system).  If a single temperature sensor covers more than one cell, the value in this parameter is for the smallest group of cells measured.";
CM_ SG_ 2364576499 HVES1HighestCellT_8075 "The highest temperature level reported by any cell in the High Voltage Energy Storage 1 pack (or system).  If a single temperature sensor covers more than one cell, the value in this parameter is for the smallest group of cells measured.";
CM_ SG_ 2364576499 HVES1AverageCellT_8077 "The average temperature level of all cells in the High Voltage Energy Storage 1 pack (or system).";
CM_ SG_ 2364576243 HVES1LowCellVolt_5923 "The lowest voltage level reported by any cell in the High Voltage Energy Storage 1 pack (or system).   If a single voltage sensor covers more than one cell, the value in this parameter is for the smallest group of cells measured.  See HVES1 Lowest";
CM_ SG_ 2364576243 HVES1HiCellVolt_5922 "Highest Cell Voltage Cell Number (SPN 8237) for cell location information.";
CM_ SG_ 2364576243 HVES1FastUpdStOCh_5921 "Indicates the High Voltage Energy Storage 1 pack (or system) state of charge.  0% means no charge remaining, 100% means the system is fully charged in terms of physical limits of the energy storage system.  Acceptable state of charge upper and";
CM_ SG_ 2364576243 HVES1CellVoltDftlSts_5924 "Indicates whether or not the differential between the highest and lowest cell voltages are within acceptable limits, according to the High Voltage Energy Storage 1 pack (or system).   The actual voltage differential can be calculated by ";
CM_ SG_ 2364575987 HVES1VoltageLevel_5919 "The voltage level of the High Voltage Energy Storage 1 pack (or system).  This parameter should be synchronized with SPN 5920 (HVES1 Current) such that a realized power value can be calculated.  If the HVES component physically ";
CM_ SG_ 2364575987 HVES1Current_5920 "The current in or out of the High Voltage Energy
";
CM_ SG_ 2364575987 HVES1AvlChPwr_5918 "The rate at which the High Voltage Energy Storage 1 pack (or system) can currently receive energy from a regenerative or recharging system.";
CM_ SG_ 2364575987 HVES1AvlDchaPwr_5917 "The rate at which the High Voltage Energy Storage 1 pack (or system) can currently provide energy for propulsion or other uses.";
CM_ SG_ 2558263038 PECPSC_7969 "Speed command to the Power Electronics Coolant Pump.
";
CM_ SG_ 2558263038 PECPPS_7970 "Power Electronics Coolant Pump Percent Speed Command";
CM_ SG_ 2558263038 PECPPH_7968 "Command to allow the Power Electronics Coolant Pump to remain alive independently of the electrical enable input to the Accessory Motor.
00 - Power Hold Disabled
01 - Power Hold Enabled
10 - Reserved
11 - Don't Care/Take no action";
CM_ SG_ 2558263038 PECPEC_7967 "Enable and direction command to the Power Electonics Coolant Pump.
00 - Accessory Motor Off
01 - Accessory Motor On Normal/Default Direction
10 - Accessory Motor On Reverse Direction
11 - Don't Care/Take no action";
CM_ SG_ 2558197502 PMCPPS_7982 "Speed command to the Propulsion Motor Coolant Pump in percentage of maximum speed.";
CM_ SG_ 2558197502 PMCPSC_7981 "Speed command to the Propulsion Motor Coolant Pump. ";
CM_ SG_ 2558197502 PMCPPH_7980 "Command to allow the Propulsion Motor Coolant Pump to remain alive independently of the electrical enable input to the Accessory Motor.
00 - Power Hold Disabled
01 - Power Hold Enabled
10 - Reserved
11 - Don't Care/Take no action";
CM_ SG_ 2558197502 PMCPEC_7979 "Enable and direction command to the Propulsion Motor Coolant Pump.
00 - Accessory Motor Off
01 - Accessory Motor On Normal/Default Direction
10 - Accessory Motor On Reverse Direction
11 - Don't Care/Take no action";
CM_ SG_ 2558131966 PMOPPSC_7994 "Speed command to the Propulsion Motor Oil Pump in percentage of maximum speed.
";
CM_ SG_ 2558131966 PMOPSC_7993 "Speed command to the Propulsion Motor Oil Pump. ";
CM_ SG_ 2558131966 PMOPPH_7992 "Command to allow the Propulsion Motor Oil Pump to remain alive independently of the electrical enable input to the Accessory Motor.
00 - Power Hold Disabled
01 - Power Hold Enabled
10 - Reserved
11 - Don't Care/Take no action";
CM_ SG_ 2558131966 PMOPEC_7991 "Enable and direction command to the Propulsion Motor Oil Pump.
00 - Accessory Motor Off
01 - Accessory Motor On Normal/Default Direction
10 - Accessory Motor On Reverse Direction
11 - Don't Care/Take no action";
CM_ SG_ 2558066430 PECF1PS_8006 "Speed command to the Power Electronics Coolant Fan 1 in percentage of maximum speed.";
CM_ SG_ 2558066430 PECF1SC_8005 "Speed command to the Power Electronics Coolant Fan 1.";
CM_ SG_ 2558066430 PECF1PH_8004 "Command to allow the Power Electronics Coolant Fan 1 to remain alive independently of the electrical enable input to the Accessory Motor.
00 - Power Hold Disabled
01 - Power Hold Enabled
10 - Reserved
11 - Don't Care/Take no action";
CM_ SG_ 2558066430 PECF1EC_8003 "Enable and direction command to the Power Electonics Coolant Fan 1.
00 - Accessory Motor Off
01 - Accessory Motor On Normal/Default Direction
10 - Accessory Motor On Reverse Direction
11 - Don't Care/Take no action";
CM_ SG_ 2558000894 PECF2PS_8018 "Speed command to the Power Electronics Coolant Fan 2 in percentage of maximum speed.";
CM_ SG_ 2558000894 PECF2SC_8017 "Speed command to the Power Electronics Coolant Fan 2.";
CM_ SG_ 2558000894 PECF2PH_8016 "Command to allow the Power Electronics Coolant Fan 2 to remain alive independently of the electrical enable input to the Accessory Motor.
00 - Power Hold Disabled
01 - Power Hold Enabled
10 - Reserved
11 - Don't Care/Take no action";
CM_ SG_ 2558000894 PECF2EC_8015 "Enable and direction command to the Power Electonics Coolant Fan 2.
00 - Accessory Motor Off
01 - Accessory Motor On Normal/Default Direction
10 - Accessory Motor On Reverse Direction
11 - Don't Care/Take no action";
CM_ SG_ 2557935358 PECF3PS_8030 "Speed command to the Power Electronics Coolant Fan 3 in percentage of maximum speed.";
CM_ SG_ 2557935358 PECF3SC_8029 "Speed command to the Power Electronics Coolant Fan 3.";
CM_ SG_ 2557935358 PECF3PH_8028 "Command to allow the Power Electronics Coolant Fan 3 to remain alive independently of the electrical enable input to the Accessory Motor.
00 - Power Hold Disabled
01 - Power Hold Enabled
10 - Reserved
11 - Don't Care/Take no action";
CM_ SG_ 2557935358 PECF3EC_8027 "Enable and direction command to the Power Electonics Coolant Fan 3.
00 - Accessory Motor Off
01 - Accessory Motor On Normal/Default Direction
10 - Accessory Motor On Reverse Direction
11 - Don't Care/Take no action";
CM_ SG_ 2557869822 PMCF1PS_8042 "Speed command to the Propulsion Motor Coolant Fan 1 in percentage of maximum speed.";
CM_ SG_ 2557869822 PMCF1SC_8041 "Speed command to the Propulsion Motor Coolant Fan 1.";
CM_ SG_ 2557869822 PMCF1PH_8040 "Command to allow the Propulsion Motor Coolant Fan 1 to remain alive independently of the electrical enable input to the Accessory Motor.
00 - Power Hold Disabled
01 - Power Hold Enabled
10 - Reserved
11 - Don't Care/Take no action";
CM_ SG_ 2557869822 PMCF1EC_8039 "Enable and direction command to the Propulsion Motor Coolant Fan 1.
00 - Accessory Motor Off
01 - Accessory Motor On Normal/Default Direction
10 - Accessory Motor On Reverse Direction
11 - Don't Care/Take no action";
CM_ SG_ 2557804286 PMCF2PS_8054 "Speed command to the Propulsion Motor Coolant Fan 2 in percentage of maximum speed.";
CM_ SG_ 2557804286 PMCF2SC_8053 "Speed command to the Propulsion Motor Coolant Fan 2.";
CM_ SG_ 2557804286 PMCF2PH_8052 "Command to allow the Propulsion Motor Coolant Fan 2 to remain alive independently of the electrical enable input to the Accessory Motor.
00 - Power Hold Disabled
01 - Power Hold Enabled
10 - Reserved
11 - Don't Care/Take no action";
CM_ SG_ 2557804286 PMCF2EC_8051 "Enable and direction command to the Power Motor Coolant Fan 2.
00 - Accessory Motor Off
01 - Accessory Motor On Normal/Default Direction
10 - Accessory Motor On Reverse Direction
11 - Don't Care/Take no action";
CM_ SG_ 2557738750 PMCF3PS_8066 "Speed command to the Propulsion Motor Coolant Fan 3 in percentage of maximum speed.";
CM_ SG_ 2557738750 PMCF3SC_8065 "Speed command to the Propulsion Motor Coolant Fan 3.";
CM_ SG_ 2557738750 PMCF3PH_8064 "Command to allow the Propulsion Motor Coolant Fan 3 to remain alive independently of the electrical enable input to the Accessory Motor.
00 - Power Hold Disabled
01 - Power Hold Enabled
10 - Reserved
11 - Don't Care/Take no action";
CM_ SG_ 2557738750 PMCF3EC_8063 "Enable and direction command to the Power Motor Coolant Fan 3.
00 - Accessory Motor Off
01 - Accessory Motor On Normal/Default Direction
10 - Accessory Motor On Reverse Direction
11 - Don't Care/Take no action";
CM_ SG_ 2557673214 ODMFB5CC_8203 "New starting value for total count of particles detected in Ferrous bin 6.";
CM_ SG_ 2557673214 ODMFB5CC_8202 "New starting value for total count of particles detected in Ferrous bin 5.";
CM_ SG_ 2557673214 ODMFB5CC_8201 "New starting value for total count of particles detected in Ferrous bin 4.";
CM_ SG_ 2557673214 ODMFB5CC_8200 "New starting value for total count of particles detected in Ferrous bin 3.";
CM_ SG_ 2557673214 ODMFB5CC_8199 "New starting value for total count of particles detected in Ferrous bin 2.";
CM_ SG_ 2557673214 ODMFB7CC_8198 "New starting value for total count of particles detected in Non-Ferrous bin 1.";
CM_ SG_ 2557673214 ODMFB6CC_8197 "New starting value for total count of particles detected in Ferrous bin 6.";
CM_ SG_ 2557673214 ODMFB5CC_8196 "New starting value for total count of particles detected in Ferrous bin 5.";
CM_ SG_ 2557673214 ODMFB4CC_8195 "New starting value for total count of particles detected in Ferrous bin 3.";
CM_ SG_ 2557673214 ODMFB2CC_8193 "New starting value for total count of particles detected in Ferrous bin 2.";
CM_ SG_ 2557673214 ODMFB3CC_8194 "New starting value for total count of particles detected in Ferrous bin 4.";
CM_ SG_ 2557673214 ODMCIN_8191 "Identification number of the Oil Debris Monitoring (ODM) sensor being configured. Identification numbers are application specific.";
CM_ SG_ 2566658558 TotalHaulCycleCount "The total accumulated number of haul cycles over the life of the product.
This should be a monotonically increasing number that sums Haul Cycle Count (SPN 6847). If transactions are supported via Payload Delivery Transaction Status (SPN 7702) then ...";
CM_ SG_ 2566658558 TotalDeliveredPayloadWeight "The accumulated delivered payload mass over the life of the product.
This should be a monotonically increasing number that sums delivered payload weights (SPN 6849) If transactions are supported (Payload Delivery Transaction Status, SPN 7702) then ...";
CM_ SG_ 2566658302 TotalPayloadTransactionCount "The accumulated number of completed payload delivery transactions over the life of the product.
If transaction status monitoring is supported via Payload Delivery Transaction Status (SPN 7702) then total payload transaction count may increment when ...";
CM_ SG_ 2499548158 RightRearCabDoorLatchPos "Status of the right rear cab door latch. Door latches may have 3 positions indicating fully open, 1st detent or \"ajar\", and 2nd detent or fully closed.
000 = Door Latch Open
001 = Door Latch Fully Closed/Latched
010 = Door Latch Ajar
011 = ...";
CM_ SG_ 2499548158 LeftRearCabDoorLatchPos "Status of the left rear cab door latch. Door latches may have 3 positions indicating fully open, 1st detent or \"ajar\", and 2nd detent or fully closed.
000 = Door Latch Open
001 = Door Latch Fully Closed/Latched
010 = Door Latch Ajar
011 = ...";
CM_ SG_ 2499548158 RightFrontCabDoorLatchPos "Status of the right front cab door latch (passenger door for left-hand steer vehicles). Door latches may have 3 positions indicating fully open, 1st detent or \"ajar\", and 2nd detent or fully closed.
000 = Door Latch Open
001 = Door Latch Fully ...";
CM_ SG_ 2499548158 LeftFrontCabDoorLatchPos "Status of the left front cab door latch (driver door for left-hand steer vehicles). Door latches may have 3 positions indicating fully open, 1st detent or \"ajar\", and 2nd detent or fully closed.
000 = Door Latch Open
001 = Door Latch Fully ...";
CM_ SG_ 2499547902 MirrorRight2HeatCmd "Command to activate heater for second mirror on the right side (passenger side for left-hand steer vehicle).  Mirror heat may be expected to latch in the \"on\" state upon receipt of the command, stay on while the command is \"take no action\" and turn ...";
CM_ SG_ 2499547902 MirrorLeft2HeatCmd "Command to activate heater for second mirror on the left side (driver side for left-hand steer vehicle).  Mirror heat may be expected to latch in the \"on\" state upon receipt of the command, stay on while the command is \"take no action\" and turn off ...";
CM_ SG_ 2499547902 MirrorRight1HeatCmd "Command to activate heater for primary mirror on the right side (passenger side for left-hand steer vehicle).  Mirror heat may be expected to latch in the \"on\" state upon receipt of the command, stay on while the command is \"take no action\" and turn ...";
CM_ SG_ 2499547902 MirrorLeft1HeatCmd "Command to activate heater for primary mirror on the left side (driver side for left-hand steer vehicle).  Mirror heat may be expected to latch in the \"on\" state upon receipt of the command, stay on while the command is \"take no action\" and turn off ...";
CM_ SG_ 2499547902 MirrorRight2VerticalCmd "Commands vertical position change of the second mirror on the right side (passenger side for lefthand steer vehicles).
00 = Move up
01 = Move down
10 = Reserved
11 = Take no action";
CM_ SG_ 2499547902 MirrorRight2HorizontalCmd "Commands horizontal position change of the second mirror on the right side (passenger side for lefthand steer vehicles).
00 = Move left
01 = Move right
10 = Reserved
11 = Take no action";
CM_ SG_ 2499547902 MirrorLeft2VerticalCmd "Commands vertical position change of the second mirror on the left side (driver side for left-hand steer vehicles).
00 = Move up
01 = Move down
10 = Reserved
11 = Take no action";
CM_ SG_ 2499547902 MirrorLeft2HorizontalCmd "Commands horizontal position change of the second mirror on the left side (driver side for left-hand steer vehicles).
00 = Move left
01 = Move right
10 = Reserved
11 = Take no action";
CM_ SG_ 2499547902 MirrorRight1VerticalCmd "Commands vertical position change of the primary mirror on the right side (passenger side for lefthand steer vehicles).
00 = Move up
01 = Move down
10 = Reserved
11 = Take no action";
CM_ SG_ 2499547902 MirrorRight1HorizontalCmd "Commands horizontal position change of the primary mirror on the right side (passenger side for lefthand steer vehicles).
00 = Move left
01 = Move right
10 = Reserved
11 = Take no action";
CM_ SG_ 2499547902 MirrorLeft1VerticalCmd "Commands vertical position change of the primary mirror on the left side (driver side for left-hand steer vehicles).
00 = Move up
01 = Move down
10 = Reserved
11 = Take no action";
CM_ SG_ 2499547902 MirrorLeft1HorizontalCmd "Commands horizontal position change of the primary mirror on the left side (driver side for left-hand steer vehicles).
00 = Move left
01 = Move right
10 = Reserved
11 = Take no action";
CM_ SG_ 2499547902 RightRearWindowPosCmd "Commands position change of the right rear window.
000 = Window move up
001 = Window move down
010 = Window auto up
011 = Window auto down
100 = Reserved
101 = Reserved
110 = Reserved
111 = Take no action";
CM_ SG_ 2499547902 LeftRearWindowPosCmd "Commands position change of left rear window.
000 = Window move up
001 = Window move down
010 = Window auto up
011 = Window auto down
100 = Reserved
101 = Reserved
110 = Reserved
111 = Take no action";
CM_ SG_ 2499547902 RightFrontWindowPosCmd "Commands position change of right front window (passenger door window on left-hand steer vehicles).
000 = Window move up
001 = Window move down
010 = Window auto up
011 = Window auto down
100 = Reserved
101 = Reserved
110 = Reserved
111 = ...";
CM_ SG_ 2499547902 LeftFrontWindowPosCmd "Commands position change of left front window (driver door window on left-hand steer vehicles).
000 = Window move up
001 = Window move down
010 = Window auto up
011 = Window auto down
100 = Reserved
101 = Reserved
110 = Reserved
111 = Take ...";
CM_ SG_ 2499547902 RemoteCabDoorLockReq "Request to the cab door lock controller from Remote Keyless Entry or or other external device to lock or unlock doors.
This parameter is different from Cab Doors Lock Actuation Command (SPN xxxx) because this is a request to actuate door locks ...";
CM_ SG_ 2499547902 DoorsLockActCmd "Commands cab door latch state change: lock or unlock.
000 = Unlock left front cab door latch (driver door on LH steer vehicles)
001 = Unlock right front cab door latch (front passenger door for LH steer vehicles)
010 = Unlock left rear cab door ...";
CM_ SG_ 2566656510 EngTotalGasIdleFuelVolumeUsed "Accumulated volume of engine gaseous fuel used during vehicle operation under idle conditions, in standard cubic meters.";
CM_ SG_ 2566656510 EngTotalGasFuelVolumeUsed "Accumulated volume of engine gaseous fuel used during vehicle operation, in standard cubic meters.
See SPN 1040 for alternate units.";
CM_ SG_ 2431710718 Checksum "Checksum to allow detection of data integrity issues. The receiving node shall calculate the checksum and compare its calculated value with the received checksum. In case of a mismatch the message shall be discarded.
The message checksum is ...";
CM_ SG_ 2431710718 MessageCounter "Message counter to allow detection of data integrity issues. The counter is incremented every time a device sends out the Engine Start Control message. When the counter has reached a value of 15 it starts over at 0 for the next message cycle ...";
CM_ SG_ 2431710718 AutomaticEngStartConsentSummary "Arbitrator’s summary of the consent statuses of all devices which the arbitrator considers for automatic start requests. The purpose of this parameter is for requesters to determine if an automatic start request would be honored at the current time.
...";
CM_ SG_ 2431710718 OpEngStartConsentSummary "Arbitrator’s summary of the consent statuses of all devices which the arbitrator considers for operator start requests. The purpose of this parameter is for requesters to determine if an operator start request would be honored at the current time.
...";
CM_ SG_ 2431710718 ReqLatchStatus "Indicates the arbitrator’s latch status for engine start requests. All “unlatched” states shall transition to state “0 - Start Request not received” after 1000 ms unless a different state becomes more appropriate in the meantime. While this time may ...";
CM_ SG_ 2431710718 StarterCmd "Command from the arbitrator to the engine starter controller(s).
The arbitrator takes input from consenters and requesters to initiate an engine start. This signal is used by the arbitrator to command the first or second starter instance.
Starter ...";
CM_ SG_ 2431710718 CtrlMessageRate "This signal is sent by the arbitrator to control the rate at which other participants send the Engine Start Control Message (ENGSC). The arbitrator sets this signal to the slower rate after the first engine start attempt after initial power-up is ...";
CM_ SG_ 2431708670 Checksum "Checksum to allow detection of data integrity issues. The receiving node shall calculate the checksum and compare its calculated value with the received checksum. In case of a mismatch the message shall be discarded.
The message checksum is ...";
CM_ SG_ 2431708670 MessageCounter "Message counter to allow detection of data integrity issues. The counter is incremented every time a device sends out the Engine Start Control message. When the counter has reached a value of 15 it starts over at 0 for the next message cycle ...";
CM_ SG_ 2431708670 Starter2Feedback "Feedback of the current state of second engine starter. This signal is intended to be used by the arbitrator as feedback to its command signal (SPN 7753).
Additional details regarding the starter state may be available in SPN 1675.
000 = Starter ...";
CM_ SG_ 2431708670 Starter1Feedback "Feedback of the current state of first engine starter. This signal is intended to be used by the arbitrator as feedback to its command signal (SPN 7753).
Additional details regarding the starter state may be available in SPN 1675.
000 = Starter ...";
CM_ SG_ 2431708670 AbortReq "Indicates the sender’s desire to abort an engine start. This signal is used by requesters and consenters to request that the arbitrator cancel an engine start that is in progress.
The sender of this signal may increase the broadcast rate ...";
CM_ SG_ 2431708670 Consent "Indicates the sender’s consent to start the engine for different start types. An operator-requested engine start is a start that is initiated directly by the operator (i.e. via the key switch). An automatic engine start is one that is initiated by a ...";
CM_ SG_ 2431708670 Req "Indicates the sender’s desire to start the engine. The engine start arbitrator latches this signal and, if possible, completes the engine start regardless of a change of state of this signal. Use Engine Start Abort Request (SPN 7747) to un-latch the ...";
CM_ SG_ 2566661118 EngTotalDieselFuelDemand "Accumulated amount of liquid fuel that would have been used during engine operation, including actual diesel fuel used and the diesel fuel that was displaced by gaseous fuel.
This is the cumulative value of SPN 7596.";
CM_ SG_ 2633769726 TotalEngEnergy "The total amount of energy delivered by the engine. It is accumulated over the life of the engine.";
CM_ SG_ 2565926142 O2Snsr2PreliminaryFMI "Used to identify the applicable J1939-73 FMI detected in the aftertreatment outlet oxygen second sensor by the manufacturer’s sensor control software in exhaust bank 2.  When there is no failure FMI 31 is sent.  In the case of multiple failures the ...";
CM_ SG_ 2565926142 NOxSnsr2SelfDiagStatus "Self-diagnosis result status for second NOx sensor ATO2 (Aftertreatment Outlet Bank 2)
000 Diagnosis not active
001 NOx Sensor ATO2 Self Diagnosis active flag
010 NOx Sensor ATO2 Self Diagnosis Result Complete
011 NOx Sensor ATO2 Self Diagnosis ...";
CM_ SG_ 2565926142 NOxSnsr2PreliminaryFMI "Used to identify the applicable J1939-73 FMI detected in the aftertreatment outlet NOx second sensor by the manufacturer’s sensor control software in exhaust bank 2.  When there is no failure FMI 31 is sent.  In the case of multiple failures the ...";
CM_ SG_ 2565926142 GasSnsr2HtrCtrl "Indicates the heater status in the warm-up process.  Upon receiving a power-up command, the gas second sensor ramps up according to a manufacturer defined profile.  The Preheat 1, Preheat 2, and Automatic messages are regions within this profile in ...";
CM_ SG_ 2565926142 GasSnsr2HtrPreliminaryFMI "Used to identify the applicable J1939-73 FMI detected in the heater of the outlet exhaust gas second sensor, either NOx or O2, by the manufacturer’s sensor control software in exhaust bank 2.  When there is no failure FMI 31 is sent.  In the case of ...";
CM_ SG_ 2565926142 WRPercentO22ReadingStable "Indicates that the percent oxygen reading of the aftertreatment outlet gas second sensor, either NOx or O2, is stable as determined by the manufacturer's control software in exhaust bank 2.
For a single exhaust bank system, refer to parameters in ...";
CM_ SG_ 2565926142 NOx2ReadingStable "Indicates that the NOx reading of the aftertreatment outlet NOx second sensor is stable as determined by the manufacturer’s control software in exhaust bank 2.
For a single exhaust bank system, refer to parameters in PGNs 61454, 61455, 64946, ...";
CM_ SG_ 2565926142 GasSnsr2AtTemp "Indicates that the heater element of the aftertreatment outlet gas second sensor, either NOx or O2, is within the manufacturer’s specified range for accurate measurements in exhaust bank 2.
For a single exhaust bank system, refer to parameters in ...";
CM_ SG_ 2565926142 GasSnsr2PwrInRange "Indicates that the power supplied to the aftertreatment outlet gas second sensor, either NOx or O2, is within the manufacturer’s specification in exhaust bank 2.
For a single exhaust bank system, refer to parameters in PGNs 61454, 61455, 64946, ...";
CM_ SG_ 2565926142 PercentO22 "The actual oxidation factor (percent oxygen) of the gas within the exhaust stream.  For positive values, the parameter represents the percent oxygen in excess of the amount required for stoichiometric combustion.  For negative values, the parameter ...";
CM_ SG_ 2565926142 NOx2 "The amount of combined NO and NO2 in the exhaust entering the aftertreatment system measured by the second NOx sensor at the aftertreatment outlet, represented in NOx molecule parts per million non-NOx molecules in exhaust bank 2.
For a single ...";
CM_ SG_ 2565925886 O2Snsr2PreliminaryFMI "Used to identify the applicable J1939-73 FMI detected in the aftertreatment intake oxygen second sensor by the manufacturer’s sensor control software in exhaust bank 2.  When there is no failure FMI 31 is sent.  In the case of multiple failures the ...";
CM_ SG_ 2565925886 NOxSnsr2SelfDiagStatus "Self-diagnosis result status for NOx second sensor ATI2 (Aftertreatment Intake Bank 2)
000 Diagnosis not active
001 NOx Sensor ATI2 Self Diagnosis active flag
010 NOx Sensor ATI2 Self Diagnosis Result Complete
011 NOx Sensor ATI2 Self Diagnosis ...";
CM_ SG_ 2565925886 SCRInNOxSnsr2PreliminaryFMI "Used to identify the applicable J1939-73 FMI detected in the aftertreatment intake NOx second sensor by the manufacturer’s sensor control software in exhaust bank 2.  When there is no failure FMI 31 is sent.  In the case of multiple failures the ...";
CM_ SG_ 2565925886 GasSnsr2HtrCtrl "Indicates the heater status in the warm-up process.  Upon receiving a power-up command, the second gas sensor ramps up according to a manufacturer defined profile.  The Preheat 1, Preheat 2, and Automatic messages are regions within this profile in ...";
CM_ SG_ 2565925886 GasSnsr2HtrPreliminaryFMI "Used to identify the applicable J1939-73 FMI detected in the heater of the intake exhaust gas second sensor, either NOx or O2, by the manufacturer’s sensor control software in exhaust bank 2.  When there is no failure FMI 31 is sent.  In the case of ...";
CM_ SG_ 2565925886 WRPercentO22ReadingStable "Indicates that the percent oxygen reading of the aftertreatment intake gas second sensor, either NOx or O2, is stable as determined by the manufacturer's control software in exhaust bank 2.
For a single exhaust bank system, refer to parameters in ...";
CM_ SG_ 2565925886 SCRInNOx2ReadingStable "Indicates that the NOx reading of the aftertreatment intake NOx second sensor is stable as determined by the manufacturer’s control software in exhaust bank 2.
For a single exhaust bank system, refer to parameters in PGNs 61454, 61455, 64946, ...";
CM_ SG_ 2565925886 GasSnsr2AtTemp "Indicates that the heater element of the aftertreatment intake gas second sensor, either NOx or O2, is within the manufacturer’s specified range for accurate measurements in exhaust bank 2.
For a single exhaust bank system, refer to parameters in ...";
CM_ SG_ 2565925886 GasSnsr2PwrInRange "Indicates that the power supplied to the aftertreatment intake gas second sensor, either NOx or O2, is within the manufacturer’s specification in exhaust bank 2.
For a single exhaust bank system, refer to parameters in PGNs 61454, 61455, 64946, ...";
CM_ SG_ 2565925886 PercentO22 "The actual oxidation factor (percent oxygen) of the gas within the exhaust stream.  For positive values, the parameter represents the percent oxygen in excess of the amount required for stoichiometric combustion.  For negative values, the parameter ...";
CM_ SG_ 2565925886 SCRInNOx2 "The amount of combined NO and NO2 in the exhaust entering the aftertreatment system measured by the second NOx sensor at the aftertreatment intake, represented in NOx molecule parts per million non-NOx molecules in exhaust bank 2.
For a single ...";
CM_ SG_ 2565925630 O2Snsr2PreliminaryFMI "Used to identify the applicable J1939-73 FMI detected in the aftertreatment outlet oxygen second sensor by the manufacturer’s sensor control software in exhaust bank 1.  When there is no failure FMI 31 is sent.  In the case of multiple failures the ...";
CM_ SG_ 2565925630 NOxSnsr2SelfDiagStatus "Self-diagnosis result status for NOx second sensor ATO1 (Aftertreatment Outlet Bank 1)
000 Diagnosis not active
001 NOx Sensor ATO1 Self Diagnosis active flag
010 NOx Sensor ATO1 Self Diagnosis Result Complete
011 NOx Sensor ATO1 Self Diagnosis ...";
CM_ SG_ 2565925630 NOxSnsr2PreliminaryFMI "Used to identify the applicable J1939-73 FMI detected in the aftertreatment outlet NOx second sensor by the manufacturer’s sensor control software in exhaust bank 1.  When there is no failure FMI 31 is sent.  In the case of multiple failures the ...";
CM_ SG_ 2565925630 Snsr2HtrCtrl "Indicates the heater status in the warm-up process.  Upon receiving a power-up command, the gas second sensor ramps up according to a manufacturer defined profile.  The Preheat 1, Preheat 2, and Automatic messages are regions within this profile in ...";
CM_ SG_ 2565925630 Snsr2HtrPreliminaryFMI "Used to identify the applicable J1939-73 FMI detected in the heater of the outlet exhaust gas second sensor, either NOx or O2, by the manufacturer’s sensor control software in exhaust bank 1.  When there is no failure FMI 31 is sent.  In the case of ...";
CM_ SG_ 2565925630 WRPercentO22ReadingStable "Indicates that the percent oxygen reading of the aftertreatment outlet gas second sensor, either NOx or O2, is stable as determined by the manufacturer's control software in exhaust bank 1.
00 - Not stable
01 - Stable
10 - Error
11 - Not ...";
CM_ SG_ 2565925630 NOx2ReadingStable "Indicates that the NOx reading of the aftertreatment outlet NOx second sensor is stable as determined by the manufacturer’s control software in exhaust bank 1.
00 - Not stable
01 - Stable
10 - Error
11 - Not available";
CM_ SG_ 2565925630 Snsr2AtTemp "Indicates that the heater element of the aftertreatment outlet gas second sensor, either NOx or O2, is within the manufacturer’s specified range for accurate measurements in exhaust bank 1.
00 - Not in range
01 - In range
10 - Error
11 - Not ...";
CM_ SG_ 2565925630 Snsr2PwrInRange "Indicates that the second measurement of power supplied to the aftertreatment outlet gas sensor, either NOx or O2, is within the manufacturer’s specification in exhaust bank 1. This parameter reports the status as reported by the sensor.
00 - Not ...";
CM_ SG_ 2565925630 PercentO22 "The second measurement of the actual oxidation factor (percent oxygen) of the gas within the exhaust stream.  For positive values, the parameter represents the percent oxygen in excess of the amount required for stoichiometric combustion.  For ...";
CM_ SG_ 2565925630 NOx2 "The second measurement of the amount of combined NO and NO2 in the exhaust exiting the aftertreatment system measured by a NOx sensor at the aftertreatment outlet, represented in NOx molecule parts per million non-NOx molecules in exhaust bank 1.";
CM_ SG_ 2565925374 O2Snsr2PreliminaryFMI "Used to identify the second applicable J1939-73 FMI detected in the aftertreatment intake oxygen sensor by the manufacturer’s sensor control software in exhaust bank 1.  When there is no failure FMI 31 is sent.  In the case of multiple failures the ...";
CM_ SG_ 2565925374 NOxSnsr2SelfDiagStatus "Self-diagnosis result status for the second NOx sensor ATI1 (Aftertreatment Intake Bank 1)
000 Diagnosis not active
001 NOx Sensor ATI1 Self Diagnosis active flag
010 NOx Sensor ATI1 Self Diagnosis Result Complete
011 NOx Sensor ATI1 Self ...";
CM_ SG_ 2565925374 SCRInNOxSnsr2PreliminaryFMI "Used to identify the applicable J1939-73 FMI detected in the aftertreatment intake NOx second sensor by the manufacturer’s sensor control software in exhaust bank 1.  When there is no failure FMI 31 is sent.  In the case of multiple failures the ...";
CM_ SG_ 2565925374 Snsr2HtrCtrl "Indicates the heater status in the warm-up process.  Upon receiving a power-up command, the second gas sensor ramps up according to a manufacturer defined profile.  The Preheat 1, Preheat 2, and Automatic messages are regions within this profile in ...";
CM_ SG_ 2565925374 Snsr2HtrPreliminaryFMI "Used to identify the second applicable J1939-73 FMI detected in the heater of the intake exhaust gas sensor, either NOx or O2, by the manufacturer’s sensor control software in exhaust bank 1.  When there is no failure FMI 31 is sent.  In the case of ...";
CM_ SG_ 2565925374 WRPercentO22ReadingStable "Indicates that the second measurement of the percent oxygen reading of the aftertreatment intake gas sensor, either NOx or O2, is stable as determined by the manufacturer's control software in exhaust bank 1.
00 - Not stable
01 - Stable
10 - ...";
CM_ SG_ 2565925374 SCRInNOx2ReadingStable "Indicates that the NOx reading of the aftertreatment intake NOx second sensor is stable as determined by the manufacturer’s control software in exhaust bank 1.
00 - Not stable
01 - Stable
10 - Error
11 - Not available";
CM_ SG_ 2565925374 Snsr2AtTemp "Indicates that the heater element of the aftertreatment intake gas second sensor, either NOx or O2, is within the manufacturer’s specified range for accurate measurements in exhaust bank 1.
00 - Not in range
01 - In range
10 - Error
11 - Not ...";
CM_ SG_ 2565925374 Snsr2PwrInRange "Indicates that the second measurement of power supplied to the aftertreatment intake gas sensor, either NOx or O2, is within the manufacturer’s specification in exhaust bank 1.  This parameter reports the status as reported by the sensor.
00 - Not ...";
CM_ SG_ 2565925374 PercentO22 "The second measurement of the actual oxidation factor (Percent Oxygen) of the gas within the exhaust stream. For positive values, the parameter represents the percent oxygen in excess of the amount required for stoichiometric combustion. For ...";
CM_ SG_ 2565925374 SCRInNOx2 "The second measurement of the amount of combined NO and NO2 in the exhaust entering the aftertreatment system measured by a NOx sensor at the aftertreatment intake, represented in NOx molecule parts per million non-NOx molecules in exhaust bank 1 ...";
CM_ SG_ 2364598526 FuelAct4CtrlCmd "The control command to fuel actuator 4, normalized to percent, where 0% represents fully closed and 100% represents fully open.  Typically, this fuel actuator is used to regulate low pressure natural gas flow rate, mixing into the air flow, which ...";
CM_ SG_ 2364598526 FuelAct3CtrlCmd "The control command to fuel actuator 3, normalized to percent, where 0% represents fully closed and 100% represents fully open.  Typically, this fuel actuator is used to regulate low pressure natural gas flow rate, mixing into the air flow, which ...";
CM_ SG_ 2558525182 Num7586 "The identification number of tire sensor for the tire specified in the tire sensor tire number (SPN 7584) or tire sensor location (SPN 7585).";
CM_ SG_ 2558525182 Location_7585 "The location of monitored tire that corresponds with the tire sensor identification number SPN 7586. In order to specify the monitored tire by tire number, use the tire number SPN 7584.
The high order 4 bits indicate the vehicle axle position of ...";
CM_ SG_ 2558525182 Num_7584 "The number of the monitored tire that corresponds with the tire sensor identification number SPN 7586. In order to specify the monitored tire by location, use the tire location SPN 7585.
The value 0xFF indicates this SPN is not used.";
CM_ SG_ 2558525182 NumOfTireSensors_7583 "Total count of monitored tire sensor identification numbers represented in this instance of the parameter group.";
CM_ SG_ 2350841598 TrqRampMaxSpdCmd "The Alternator Torque Ramp Time Command (SPN 7591) is applied if the alternator speed is less than Alternator Torque Ramp Maximum Speed Command (SPN 7592). If the alternator speed is greater than Alternator Torque Ramp Maximum Speed Command, then ...";
CM_ SG_ 2350841598 TrqRampTimeCmd "Sets the torque ramp rate in which the alternator can respond to a change in electrical load. 100% represents the reference engine torque (SPN 544).
This value will be applied if the alternator speed is less than Alternator Torque Ramp Maximum ...";
CM_ SG_ 2350841598 ExcitationMaxCurrentLmt "Command sent to alternator to set the maximum excitation current of the alternator.";
CM_ SG_ 2350841598 SetpointVoltageCmd "Setpoint voltage command to alternator. The setpoint voltage is the point that is regulated by the alternator. This may or may not be the output of the alternator.";
CM_ SG_ 2566838014 ShutdownSw "When the operator enables this switch, all hybrid system functionality is disabled including propulsion, regenerative braking, and hybrid powered accessories.  For electric hybrids, the hybrid system shall be placed in an electrically off state ...";
CM_ SG_ 2566838014 PropulsionDisableSw "When the operator enables this switch, the propulsion aspect of hybrid system operation will be disabled.  However, hybrid powered accessories may be on and the engine may still run.  Regenerative braking is allowed unless disabled by SPN 7552 ...";
CM_ SG_ 2566838014 HybrdSystmCstngRgnrtvBrkngLvlSlc "Indicates the coasting regenerative braking level selector position.  Coasting regenerative braking occurs when neither the accelerator nor the brake pedal are depressed.
The coasting regenerative braking level is the position of the driver’s ...";
CM_ SG_ 2566838014 HybrdSystmBrkPdlRgnrtvBrkngDsblS "Indicates the brake pedal regenerative braking disable switch position.  This switch allows the operator to disable regenerative braking (e.g. such as during slippery road conditions) that is controlled by brake pedal application.   Regenerative ...";
CM_ SG_ 2566838014 HybrdSystmRgnrtvBrkngDsbleSwitch "Indicates the regenerative braking disable switch position.  This switch gives the operator the ability to disable all regenerative braking from all inputs (e.g. such as during slippery road conditions).
00 = Regenerative Braking Disable Switch is ...";
CM_ SG_ 2566838014 HybrdSystmOffBrdChrgrCnnctnSttus "Indicates the off-board plug-in charger connection status.  One of the uses of this signal is to protect against vehicle motion while a charger is plugged in.
00 = Off-board charger is not connected
01 = Off-board charger is connected
10 = Error
...";
CM_ SG_ 2566838014 HybrdSystmPwrElctrncsClntLvlSwtc "Indicates the coolant level switch position in the hybrid system power electronics (e.g. Inverters, DC/DC converters) cooling system.
00 = Coolant Level is not sufficient
01 = Coolant Level is sufficient
10 = Error
11 = Not Available";
CM_ SG_ 2566838014 HybrdSystmPrplsnClantLevelSwitch "Indicates the coolant level switch position in the hybrid system propulsion (e.g. electric motor, generator) cooling system.
00 = Coolant Level is not sufficient
01 = Coolant Level is sufficient
10 = Error
11 = Not Available";
CM_ SG_ 2566838014 HybrdSystmPrtctionOverrideSwitch "Indicates the Protection Override switch position.  This switch allows the operator to override hybrid system protection features and failure modes allowing hybrid system to continue to operate if possible.
00 = Not Active
01 = Active
10 = Error
...";
CM_ SG_ 2566761726 EngIdleFuelFlowRateThreshold "A configuration value that indicates the maximum flow rate for engine idle operation.";
CM_ SG_ 2566761726 NmbrOfFlCnsmptnMntrngTransducers "The number of fuel consumption monitoring transducers installed in the fuel consumption monitoring system.";
CM_ SG_ 2566756350 EngFuelReturnTemp "The temperature of the fuel flowing through a fuel return line from the engine back to the fuel tank.";
CM_ SG_ 2566756350 EngFuelSupplyTemp "The temperature of the fuel flowing through a fuel supply line from the fuel tank to the engine.";
CM_ SG_ 2566756094 EngFuelReturnFlowRate "The rate of fuel flowing through a fuel return line carrying fuel from the engine back to fuel tank.";
CM_ SG_ 2566756094 EngFuelSupplyFlowRate "The rate of fuel flowing through a fuel supply line carrying fuel from the fuel tank to the engine.";
CM_ SG_ 2566687998 TimeBetweenRegens "This is the time between the last two successful regenerations of the particulate sensor for the current power cycle. This parameter reflects the time when the engine was running, not a duration based on a real time clock. If two successful ...";
CM_ SG_ 2566687998 ActiveAccumulationTime "This is the amount of time since the last successful regeneration completed.  The sensor has been accumulating particulate matter since that time.";
CM_ SG_ 2566687998 RegenSt "Indicates if the particulate sensor regeneration is currently active, and if so, the reason for the regeneration.
0000 - Regeneration is not active
0001 - Regneration is active and has been initiated by request via SPN 6783
0010 - Regeneration is ...";
CM_ SG_ 2566687998 RegenStatus "The status of the most recent attempt of this power cycle to activate the particulate sensor regeneration process. This will not be updated until the regeneration is no longer active, as indicated by SPN 6774.
Power cycle refers to the time that ...";
CM_ SG_ 2566687998 HtrSt "The states of the particulate sensor heater.  The heater will change states from 11 to 10, 10 to 01, and 01 to 00 in a typical heating event.
00 - Heater is in closed loop control
01 - Heater is being held at a specified level
10 - Heater is in ...";
CM_ SG_ 2566687998 Res "This sensor is located in the exhaust stream somewhere after the DPF, but not necessarily immediately after the DPF.  It provides a resistance value that can be used to determine particulate matter in the exhaust stream. The value in this parameter ...";

BA_DEF_ BO_ "GenMsgCycleTime" INT 0 3600000;
BA_DEF_ BO_ "GenMsgCycleTimeFast" INT 0 3600000;
BA_DEF_ BO_ "GenMsgDelayTime" INT 0 1000;
BA_DEF_ BO_ "GenMsgILSupport" ENUM  "No","Yes";
BA_DEF_ BO_ "GenMsgRequestable" INT 0 1;
BA_DEF_ BO_ "GenMsgSendType" ENUM  "cyclic","spontaneous","cyclicIfActive","spontaneousWithDelay","cyclicAndSpontaneous","cyclicAndSpontaneousWithDelay","spontaneousWithRepetition","cyclicIfActiveAndSpontaneousWD";
BA_DEF_ BO_ "GenMsgStartDelayTime" INT 0 100000;
BA_DEF_ BO_ "J1939PGNameSecSrc0Dest3" STRING;
BA_DEF_ BO_ "J1939PGPrio" INT 0 7;
BA_DEF_ BO_ "J1939PGPrioSrc0Dest3" INT 0 7;
BA_DEF_ BO_ "J1939PGRelationDest3Src0" INT 0 254;
BA_DEF_ BO_ "J1939PGRelationSrc0Dest3" INT 0 254;
BA_DEF_ BO_ "J1939PGRepCycleSrc0Dest3" INT -1 65535;
BA_DEF_ BO_ "J1939PGRepTypeSrc0Dest3" INT 0 4;
BA_DEF_ BO_ "J1939PGRepetitionCycle" INT 0 65535;
BA_DEF_ BO_ "J1939PGRepetitionType" ENUM  "always","when active","on request";
BA_DEF_ BO_ "J1939PGtoECUSrc0Dest3" INT 0 254;
BA_DEF_ BO_ "J1939PGtoWSMSrc0Dest3" INT 0 254;
BA_DEF_ BO_ "TpJ1939VarDlc" ENUM  "No","Yes";
BA_DEF_ BO_ "VFrameFormat" ENUM  "StandardCAN","ExtendedCAN","reserved","J1939PG";
BA_DEF_ SG_ "GenSigEVName" STRING;
BA_DEF_ SG_ "GenSigILSupport" ENUM  "No","Yes";
BA_DEF_ SG_ "GenSigSendType" ENUM  "Cyclic","OnWrite","OnWriteWithRepetition","OnChange","OnChangeWithRepetition","IfActive","IfActiveWithRepetition","NoSigSendType";
BA_DEF_ SG_ "GenSigStartValue" INT 0 10000;
BA_DEF_ SG_ "SPN" INT 0 524287;
BA_DEF_ SG_ "SigType" ENUM  "Default","Range","RangeSigned","ASCII","Discrete","Control","ReferencePGN","DTC","StringDelimiter","StringLength","StringLengthControl","MessageCounter","MessageChecksum";
BA_DEF_ SG_ "SystemSignalLongSymbol" STRING;
BA_DEF_DEF_ "GenMsgCycleTime" 0;
BA_DEF_DEF_ "GenMsgCycleTimeFast" 0;
BA_DEF_DEF_ "GenMsgDelayTime" 0;
BA_DEF_DEF_ "GenMsgILSupport" "Yes";
BA_DEF_DEF_ "GenMsgRequestable" 1;
BA_DEF_DEF_ "GenMsgSendType" "noMsgSendType";
BA_DEF_DEF_ "GenMsgStartDelayTime" 0;
BA_DEF_DEF_ "GenSigEVName" "Env@Nodename_@Signame";
BA_DEF_DEF_ "GenSigILSupport" "Yes";
BA_DEF_DEF_ "GenSigSendType" "NoSigSendType";
BA_DEF_DEF_ "GenSigStartValue" 0;
BA_DEF_DEF_ "J1939PGNameSecSrc0Dest3" "(null)";
BA_DEF_DEF_ "J1939PGPrio" 6;
BA_DEF_DEF_ "J1939PGPrioSrc0Dest3" 6;
BA_DEF_DEF_ "J1939PGRelationDest3Src0" 254;
BA_DEF_DEF_ "J1939PGRelationSrc0Dest3" 254;
BA_DEF_DEF_ "J1939PGRepCycleSrc0Dest3" -1;
BA_DEF_DEF_ "J1939PGRepTypeSrc0Dest3" 3;
BA_DEF_DEF_ "J1939PGRepetitionCycle" 100;
BA_DEF_DEF_ "J1939PGRepetitionType" "always";
BA_DEF_DEF_ "J1939PGtoECUSrc0Dest3" -1;
BA_DEF_DEF_ "J1939PGtoWSMSrc0Dest3" -1;
BA_DEF_DEF_ "SPN" 0;
BA_DEF_DEF_ "SigType" "Default";
BA_DEF_DEF_ "SystemSignalLongSymbol" "";
BA_DEF_DEF_ "TpJ1939VarDlc" "No";
BA_DEF_DEF_ "VFrameFormat" "J1939PG";
BA_ "GenMsgCycleTime" BO_ 2565866752 100;
BA_ "GenMsgSendType" BO_ 2565866752 0;
BA_ "GenMsgCycleTime" BO_ 2566843904 1000;
BA_ "GenMsgSendType" BO_ 2566843904 0;
BA_ "GenMsgCycleTime" BO_ 2566844928 100;
BA_ "GenMsgSendType" BO_ 2566844928 0;
BA_ "GenMsgCycleTime" BO_ 2566845952 500;
BA_ "GenMsgSendType" BO_ 2566845952 0;
BA_ "GenMsgCycleTime" BO_ 2566846208 1000;
BA_ "GenMsgSendType" BO_ 2566846208 0;
BA_ "GenMsgCycleTime" BO_ 2566844806 100;
BA_ "GenMsgSendType" BO_ 2566844806 4.90833586961908E-316;
BA_ "GenMsgCycleTime" BO_ 2565537345 100;
BA_ "GenMsgSendType" BO_ 2565537345 4.90720860944153E-316;
BA_ "GenMsgCycleTime" BO_ 2566857216 10;
BA_ "GenMsgSendType" BO_ 2566857216 0;
BA_ "GenMsgCycleTime" BO_ 2365530368 10;
BA_ "GenMsgSendType" BO_ 2365530368 0;
BA_ "GenMsgCycleTime" BO_ 2365530123 10;
BA_ "GenMsgSendType" BO_ 2365530123 0;
BA_ "GenMsgCycleTime" BO_ 2566834822 100;
BA_ "GenMsgSendType" BO_ 2566834822 4.90264818590416E-316;
BA_ "GenMsgCycleTime" BO_ 2564358137 100;
BA_ "GenMsgSendType" BO_ 2564358137 0;
BA_ "GenMsgCycleTime" BO_ 2432656519 200;
BA_ "GenMsgSendType" BO_ 2432656519 1.79355710753289E-316;
BA_ "GenMsgCycleTime" BO_ 2432656775 100;
BA_ "GenMsgSendType" BO_ 2432656775 1.7919428962548E-316;
BA_ "GenMsgCycleTime" BO_ 2365449728 100;
BA_ "GenMsgSendType" BO_ 2365449728 1.79186147423637E-316;
BA_ "GenMsgCycleTime" BO_ 2566884352 20;
BA_ "GenMsgSendType" BO_ 2566884352 1.78475167196645E-316;
BA_ "GenMsgCycleTime" BO_ 2566842396 100;
BA_ "GenMsgSendType" BO_ 2566842396 1.78376354067477E-316;
BA_ "GenMsgCycleTime" BO_ 2566877607 1000;
BA_ "GenMsgSendType" BO_ 2566877607 1.80827947327393E-316;
BA_ "GenMsgCycleTime" BO_ 2381320220 100;
BA_ "GenMsgSendType" BO_ 2381320220 1.8082383670122E-316;
BA_ "GenMsgCycleTime" BO_ 2314731804 100;
BA_ "GenMsgSendType" BO_ 2314731804 1.80822967145683E-316;
BA_ "GenMsgCycleTime" BO_ 2583298844 100;
BA_ "GenMsgSendType" BO_ 2583298844 1.80822571893166E-316;
BA_ "GenMsgCycleTime" BO_ 2314732060 100;
BA_ "GenMsgSendType" BO_ 2314732060 1.80820911832596E-316;
BA_ "GenMsgCycleTime" BO_ 2364607475 100;
BA_ "GenMsgSendType" BO_ 2364607475 0;
BA_ "GenMsgCycleTime" BO_ 2364607219 100;
BA_ "GenMsgSendType" BO_ 2364607219 0;
BA_ "GenMsgCycleTime" BO_ 2364606707 100;
BA_ "GenMsgSendType" BO_ 2364606707 0;
BA_ "GenMsgCycleTime" BO_ 2364552947 100;
BA_ "GenMsgSendType" BO_ 2364552947 0;
BA_ "GenMsgSendType" BO_ 2633785075 7;
BA_ "GenMsgSendType" BO_ 2566675955 7;
BA_ "GenMsgCycleTime" BO_ 2364606963 100;
BA_ "GenMsgSendType" BO_ 2364606963 0;
BA_ "GenMsgCycleTime" BO_ 2364580083 100;
BA_ "GenMsgSendType" BO_ 2364580083 0;
BA_ "GenMsgCycleTime" BO_ 2364577523 100;
BA_ "GenMsgCycleTimeFast" BO_ 2364577523 20;
BA_ "GenMsgSendType" BO_ 2364577523 0;
BA_ "GenMsgCycleTime" BO_ 2364577267 100;
BA_ "GenMsgSendType" BO_ 2364577267 0;
BA_ "GenMsgCycleTime" BO_ 2364577011 20;
BA_ "GenMsgSendType" BO_ 2364577011 0;
BA_ "GenMsgCycleTime" BO_ 2364576755 100;
BA_ "GenMsgSendType" BO_ 2364576755 0;
BA_ "GenMsgCycleTime" BO_ 2364576499 20;
BA_ "GenMsgCycleTime" BO_ 2364576243 20;
BA_ "GenMsgSendType" BO_ 2364576243 0;
BA_ "GenMsgCycleTime" BO_ 2364575987 20;
BA_ "GenMsgSendType" BO_ 2364575987 0;
BA_ "GenMsgCycleTime" BO_ 2558263038 1000;
BA_ "GenMsgSendType" BO_ 2558263038 0;
BA_ "GenMsgCycleTime" BO_ 2558197502 1000;
BA_ "GenMsgSendType" BO_ 2558197502 0;
BA_ "GenMsgCycleTime" BO_ 2558131966 1000;
BA_ "GenMsgSendType" BO_ 2558131966 0;
BA_ "GenMsgCycleTime" BO_ 2558066430 1000;
BA_ "GenMsgSendType" BO_ 2558066430 0;
BA_ "GenMsgCycleTime" BO_ 2558000894 1000;
BA_ "GenMsgSendType" BO_ 2558000894 0;
BA_ "GenMsgCycleTime" BO_ 2557935358 1000;
BA_ "GenMsgSendType" BO_ 2557935358 0;
BA_ "GenMsgCycleTime" BO_ 2557869822 1000;
BA_ "GenMsgSendType" BO_ 2557869822 0;
BA_ "GenMsgCycleTime" BO_ 2557804286 1000;
BA_ "GenMsgSendType" BO_ 2557804286 0;
BA_ "GenMsgCycleTime" BO_ 2557738750 1000;
BA_ "GenMsgSendType" BO_ 2557738750 0;
BA_ "GenMsgCycleTime" BO_ 2350644979 20;
BA_ "GenMsgSendType" BO_ 2350644979 0;
BA_ "GenMsgCycleTime" BO_ 2566658558 5000;
BA_ "GenMsgSendType" BO_ 2566658558 0;
BA_ "GenMsgCycleTime" BO_ 2566658302 5000;
BA_ "GenMsgSendType" BO_ 2566658302 0;
BA_ "GenMsgCycleTime" BO_ 2499549182 1000;
BA_ "GenMsgSendType" BO_ 2499549182 0;
BA_ "GenMsgCycleTime" BO_ 2499548926 1000;
BA_ "GenMsgSendType" BO_ 2499548926 0;
BA_ "GenMsgCycleTime" BO_ 2499548670 100;
BA_ "GenMsgSendType" BO_ 2499548670 0;
BA_ "GenMsgCycleTime" BO_ 2499548158 1000;
BA_ "GenMsgDelayTime" BO_ 2499548158 100;
BA_ "GenMsgSendType" BO_ 2499548158 0;
BA_ "GenMsgCycleTime" BO_ 2499547902 1000;
BA_ "GenMsgDelayTime" BO_ 2499547902 100;
BA_ "GenMsgSendType" BO_ 2499547902 0;
BA_ "GenMsgDelayTime" BO_ 2431710718 20;
BA_ "GenMsgDelayTime" BO_ 2431708670 20;
BA_ "GenMsgCycleTime" BO_ 2565926142 50;
BA_ "GenMsgSendType" BO_ 2565926142 0;
BA_ "GenMsgCycleTime" BO_ 2565925886 50;
BA_ "GenMsgSendType" BO_ 2565925886 0;
BA_ "GenMsgCycleTime" BO_ 2565925630 50;
BA_ "GenMsgSendType" BO_ 2565925630 0;
BA_ "GenMsgCycleTime" BO_ 2565925374 50;
BA_ "GenMsgSendType" BO_ 2565925374 0;
BA_ "GenMsgCycleTime" BO_ 2364598526 50;
BA_ "GenMsgSendType" BO_ 2364598526 0;
BA_ "TpJ1939VarDlc" BO_ 2558525182 1;
BA_ "GenMsgCycleTime" BO_ 2350841598 200;
BA_ "GenMsgSendType" BO_ 2350841598 0;
BA_ "GenMsgCycleTime" BO_ 2566838014 1000;
BA_ "GenMsgSendType" BO_ 2566838014 0;
BA_ "GenMsgCycleTime" BO_ 2566756350 1000;
BA_ "GenMsgSendType" BO_ 2566756350 0;
BA_ "GenMsgCycleTime" BO_ 2566756094 1000;
BA_ "GenMsgSendType" BO_ 2566756094 0;
BA_ "GenMsgCycleTime" BO_ 2566687998 200;
BA_ "GenMsgSendType" BO_ 2566687998 0;
BA_ "SPN" SG_ 2565866752 TransmissionSelectedGear 524;
BA_ "SigType" SG_ 2565866752 TransmissionSelectedGear 1.7E-308;
BA_ "SPN" SG_ 2565866752 TransmissionActualGearRatio 526;
BA_ "SigType" SG_ 2565866752 TransmissionActualGearRatio 1.7E-308;
BA_ "SPN" SG_ 2565866752 TransmissionCurrentGear 523;
BA_ "SigType" SG_ 2565866752 TransmissionCurrentGear 1.7E-308;
BA_ "SPN" SG_ 2565866752 TransmissionRqstedRange 162;
BA_ "SigType" SG_ 2565866752 TransmissionRqstedRange 1.7E-308;
BA_ "SPN" SG_ 2565866752 TransmissionCurrentRange 163;
BA_ "SigType" SG_ 2565866752 TransmissionCurrentRange 1.7E-308;
BA_ "SPN" SG_ 2566843904 EngineCoolantTemperature 110;
BA_ "SigType" SG_ 2566843904 EngineCoolantTemperature 1.7E-308;
BA_ "SPN" SG_ 2566843904 EngFuelTemperature1 174;
BA_ "SigType" SG_ 2566843904 EngFuelTemperature1 1.7E-308;
BA_ "SPN" SG_ 2566843904 EngineOilTemperature1 175;
BA_ "SigType" SG_ 2566843904 EngineOilTemperature1 1.7E-308;
BA_ "SPN" SG_ 2566843904 EngTurboOilTemperature 176;
BA_ "SigType" SG_ 2566843904 EngTurboOilTemperature 1.7E-308;
BA_ "SPN" SG_ 2566843904 EngineIntercoolerTemperature 52;
BA_ "SigType" SG_ 2566843904 EngineIntercoolerTemperature 1.7E-308;
BA_ "SPN" SG_ 2566843904 EngineIntercoolerThermosatOpen 1134;
BA_ "SigType" SG_ 2566843904 EngineIntercoolerThermosatOpen 1.7E-308;
BA_ "SPN" SG_ 2566844928 EngineFuelRate 183;
BA_ "SigType" SG_ 2566844928 EngineFuelRate 1.7E-308;
BA_ "SPN" SG_ 2566844928 InstantaneousFuelEconomy 184;
BA_ "SigType" SG_ 2566844928 InstantaneousFuelEconomy 1.7E-308;
BA_ "SPN" SG_ 2566844928 AverageFuelEconomy 185;
BA_ "SigType" SG_ 2566844928 AverageFuelEconomy 1.7E-308;
BA_ "SPN" SG_ 2566844928 EngineThrottlePosition 51;
BA_ "SigType" SG_ 2566844928 EngineThrottlePosition 1.7E-308;
BA_ "SPN" SG_ 2566845952 ParticulateTrapInletPressure 81;
BA_ "SigType" SG_ 2566845952 ParticulateTrapInletPressure 1.7E-308;
BA_ "SPN" SG_ 2566845952 EngTurboBoostPressure 102;
BA_ "SigType" SG_ 2566845952 EngTurboBoostPressure 1.7E-308;
BA_ "SPN" SG_ 2566845952 EngIntakeManifoldTemperature 105;
BA_ "SigType" SG_ 2566845952 EngIntakeManifoldTemperature 1.7E-308;
BA_ "SPN" SG_ 2566845952 EngAirInletPressure 106;
BA_ "SigType" SG_ 2566845952 EngAirInletPressure 1.7E-308;
BA_ "SPN" SG_ 2566845952 AirFilterDifferentialPressure 107;
BA_ "SigType" SG_ 2566845952 AirFilterDifferentialPressure 1.7E-308;
BA_ "SPN" SG_ 2566845952 EngExhaustGasTemperature 173;
BA_ "SigType" SG_ 2566845952 EngExhaustGasTemperature 1.7E-308;
BA_ "SPN" SG_ 2566845952 CoolantFilterDiffPressure 112;
BA_ "SigType" SG_ 2566845952 CoolantFilterDiffPressure 1.7E-308;
BA_ "SPN" SG_ 2566846208 NetBatteryCurrent 114;
BA_ "SigType" SG_ 2566846208 NetBatteryCurrent 1.7E-308;
BA_ "SPN" SG_ 2566846208 AlternatorCurrent 115;
BA_ "SigType" SG_ 2566846208 AlternatorCurrent 1.7E-308;
BA_ "SPN" SG_ 2566846208 ChargingSystemPotential 167;
BA_ "SigType" SG_ 2566846208 ChargingSystemPotential 1.7E-308;
BA_ "SPN" SG_ 2566846208 BatteryPotential 168;
BA_ "SigType" SG_ 2566846208 BatteryPotential 1.7E-308;
BA_ "SPN" SG_ 2566846208 KeyswitchBatteryPotential 158;
BA_ "SigType" SG_ 2566846208 KeyswitchBatteryPotential 1.7E-308;
BA_ "GenSigStartValue" SG_ 2566844806 pCruiseCntrlCounter 7;
BA_ "SPN" SG_ 2566844806 pCruiseCntrlCounter 524080;
BA_ "SPN" SG_ 2566844806 TwoSpeedAxleSwitch 69;
BA_ "SigType" SG_ 2566844806 TwoSpeedAxleSwitch 1.7E-308;
BA_ "SPN" SG_ 2566844806 ParkingBrakeSwitch 70;
BA_ "SigType" SG_ 2566844806 ParkingBrakeSwitch 1.7E-308;
BA_ "SPN" SG_ 2566844806 Wheel_BasedVehicleSpeed 84;
BA_ "SigType" SG_ 2566844806 Wheel_BasedVehicleSpeed 1.7E-308;
BA_ "SPN" SG_ 2566844806 CruiseCtrlActive 595;
BA_ "SigType" SG_ 2566844806 CruiseCtrlActive 1.7E-308;
BA_ "SPN" SG_ 2566844806 CruiseCtrlEnableSwitch 596;
BA_ "SigType" SG_ 2566844806 CruiseCtrlEnableSwitch 1.7E-308;
BA_ "SPN" SG_ 2566844806 BrakeSwitch 597;
BA_ "SigType" SG_ 2566844806 BrakeSwitch 1.7E-308;
BA_ "SPN" SG_ 2566844806 ClutchSwitch 598;
BA_ "SigType" SG_ 2566844806 ClutchSwitch 1.7E-308;
BA_ "SPN" SG_ 2566844806 CruiseCtrlSetSwitch 599;
BA_ "SigType" SG_ 2566844806 CruiseCtrlSetSwitch 1.7E-308;
BA_ "SPN" SG_ 2566844806 CruiseCtrlCoastSwitch 600;
BA_ "SigType" SG_ 2566844806 CruiseCtrlCoastSwitch 1.7E-308;
BA_ "SPN" SG_ 2566844806 CruiseCtrlResumeSwitch 601;
BA_ "SigType" SG_ 2566844806 CruiseCtrlResumeSwitch 1.7E-308;
BA_ "SPN" SG_ 2566844806 CruiseCtrlAccelerateSwitch 602;
BA_ "SigType" SG_ 2566844806 CruiseCtrlAccelerateSwitch 1.7E-308;
BA_ "SPN" SG_ 2566844806 CruiseCtrlSetSpeed 86;
BA_ "SigType" SG_ 2566844806 CruiseCtrlSetSpeed 1.7E-308;
BA_ "SPN" SG_ 2566844806 pOdometerDriveBit 523994;
BA_ "SigType" SG_ 2566844806 pOdometerDriveBit 1.7E-308;
BA_ "SPN" SG_ 2566844806 CruiseCtrlPauseSw 1633;
BA_ "SigType" SG_ 2566844806 CruiseCtrlPauseSw 1.7E-308;
BA_ "SPN" SG_ 2566844806 pCCChecksum 524079;
BA_ "SigType" SG_ 2566844806 pCCChecksum 1.7E-308;
BA_ "SPN" SG_ 2566844806 pCruiseEnableStatus 524108;
BA_ "SigType" SG_ 2566844806 pCruiseEnableStatus 1.7E-308;
BA_ "SPN" SG_ 2565537345 RqstedPGN 2540;
BA_ "SigType" SG_ 2565537345 RqstedPGN 1.7E-308;
BA_ "SPN" SG_ 2566857216 pVehicleSpeed 520573;
BA_ "SPN" SG_ 2566857216 pEngineTorque_Inst_Max 520576;
BA_ "SPN" SG_ 2566857216 pEngineTorque_Inst_Min 520575;
BA_ "SPN" SG_ 2566857216 pNorm_Acc_Pos 520574;
BA_ "SPN" SG_ 2566857216 pRawBrakeStatus 520572;
BA_ "SPN" SG_ 2365530368 pChecksum_520571 520571;
BA_ "SPN" SG_ 2365530368 pMessageCounter_520570 520570;
BA_ "SPN" SG_ 2365530368 pEngineSpeed_520569 520569;
BA_ "SPN" SG_ 2365530368 pEngineTorque_Driver_Demanded 520568;
BA_ "SPN" SG_ 2365530368 pEngineTorque 520567;
BA_ "SPN" SG_ 2365530368 pSource_Address_Ctrling_Device 520566;
BA_ "SPN" SG_ 2365530123 pEngCtlMode 520560;
BA_ "SigType" SG_ 2365530123 pEngCtlMode 1.7E-308;
BA_ "SPN" SG_ 2365530123 pEngReqSpeedLimit 520563;
BA_ "SigType" SG_ 2365530123 pEngReqSpeedLimit 1.7E-308;
BA_ "SPN" SG_ 2365530123 pChecksum_520565 520565;
BA_ "SPN" SG_ 2365530123 pMessageCounter_520564 524122;
BA_ "SPN" SG_ 2365530123 pEngCtlReq 520561;
BA_ "SigType" SG_ 2365530123 pEngCtlReq 1.7E-308;
BA_ "SPN" SG_ 2365530123 pEngReqTorqueLimit 520562;
BA_ "SigType" SG_ 2365530123 pEngReqTorqueLimit 1.7E-308;
BA_ "SigType" SG_ 2566834822 DTC5 7;
BA_ "SigType" SG_ 2566834822 DTC4 7;
BA_ "SigType" SG_ 2566834822 DTC3 7;
BA_ "SigType" SG_ 2566834822 DTC2 7;
BA_ "SigType" SG_ 2566834822 DTC1 7;
BA_ "SPN" SG_ 2566834822 DM_FlashRedStopLamp 3039;
BA_ "SPN" SG_ 2566834822 DM_FlashProtectLamp 3041;
BA_ "SPN" SG_ 2566834822 DM_FlashMalfuncIndicatorLamp 3038;
BA_ "SPN" SG_ 2566834822 DM_FlashAmberWarningLamp 3040;
BA_ "SPN" SG_ 2566834822 DM_ProtectLampStatus 987;
BA_ "SigType" SG_ 2566834822 DM_ProtectLampStatus 1.7E-308;
BA_ "SPN" SG_ 2566834822 DM_RedStopLampState 623;
BA_ "SigType" SG_ 2566834822 DM_RedStopLampState 1.7E-308;
BA_ "SPN" SG_ 2566834822 DM_AmberWrningLmpStatus 624;
BA_ "SigType" SG_ 2566834822 DM_AmberWrningLmpStatus 1.7E-308;
BA_ "SPN" SG_ 2566834822 DM_MalfuncnIndicatorLampStatus 1213;
BA_ "SigType" SG_ 2566834822 DM_MalfuncnIndicatorLampStatus 1.7E-308;
BA_ "GenSigStartValue" SG_ 2564358137 DM15_SAE_Reserved2 1;
BA_ "GenSigStartValue" SG_ 2564358137 DM15_SAE_Reserved 1;
BA_ "SPN" SG_ 2432656519 pInfotainmentJoystick2 520364;
BA_ "SPN" SG_ 2432656519 pInfotainmentJoystick1 520363;
BA_ "SPN" SG_ 2432656519 pInfotainmentRemoteButton01 524031;
BA_ "SigType" SG_ 2432656519 pInfotainmentRemoteButton01 1.7E-308;
BA_ "SPN" SG_ 2432656519 pInfotainmentRemoteButton02 524030;
BA_ "SigType" SG_ 2432656519 pInfotainmentRemoteButton02 1.7E-308;
BA_ "SPN" SG_ 2432656519 pInfotainmentRemoteButton03 524029;
BA_ "SigType" SG_ 2432656519 pInfotainmentRemoteButton03 1.7E-308;
BA_ "SPN" SG_ 2432656519 pInfotainmentRemoteButton04 524028;
BA_ "SigType" SG_ 2432656519 pInfotainmentRemoteButton04 1.7E-308;
BA_ "SPN" SG_ 2432656519 pInfotainmentRemoteButton05 524027;
BA_ "SigType" SG_ 2432656519 pInfotainmentRemoteButton05 1.7E-308;
BA_ "SPN" SG_ 2432656519 pInfotainmentRemoteButton06 524026;
BA_ "SigType" SG_ 2432656519 pInfotainmentRemoteButton06 1.7E-308;
BA_ "SPN" SG_ 2432656519 pInfotainmentRemoteButton07 524025;
BA_ "SigType" SG_ 2432656519 pInfotainmentRemoteButton07 1.7E-308;
BA_ "SPN" SG_ 2432656519 pInfotainmentRemoteButton08 524024;
BA_ "SigType" SG_ 2432656519 pInfotainmentRemoteButton08 1.7E-308;
BA_ "SPN" SG_ 2432656519 pInfotainmentRemoteButton09 524023;
BA_ "SigType" SG_ 2432656519 pInfotainmentRemoteButton09 1.7E-308;
BA_ "SPN" SG_ 2432656519 pInfotainmentRemoteButton10 524022;
BA_ "SigType" SG_ 2432656519 pInfotainmentRemoteButton10 1.7E-308;
BA_ "SPN" SG_ 2432656519 pInfotainmentRemoteButton11 524021;
BA_ "SigType" SG_ 2432656519 pInfotainmentRemoteButton11 1.7E-308;
BA_ "SPN" SG_ 2432656519 pInfotainmentRemoteButton12 524020;
BA_ "SigType" SG_ 2432656519 pInfotainmentRemoteButton12 1.7E-308;
BA_ "SPN" SG_ 2432656775 pOperatorButton29 524060;
BA_ "SPN" SG_ 2432656775 pOperatorButton1 524059;
BA_ "SigType" SG_ 2432656775 pOperatorButton1 1.7E-308;
BA_ "SPN" SG_ 2432656775 pOperatorButton2 524058;
BA_ "SigType" SG_ 2432656775 pOperatorButton2 1.7E-308;
BA_ "SPN" SG_ 2432656775 pOperatorButton3 524057;
BA_ "SigType" SG_ 2432656775 pOperatorButton3 1.7E-308;
BA_ "SPN" SG_ 2432656775 pOperatorButton4 524056;
BA_ "SigType" SG_ 2432656775 pOperatorButton4 1.7E-308;
BA_ "SPN" SG_ 2432656775 pOperatorButton5 524055;
BA_ "SigType" SG_ 2432656775 pOperatorButton5 1.7E-308;
BA_ "SPN" SG_ 2432656775 pOperatorButton6 524054;
BA_ "SigType" SG_ 2432656775 pOperatorButton6 1.7E-308;
BA_ "SPN" SG_ 2432656775 pOperatorButton7 524053;
BA_ "SigType" SG_ 2432656775 pOperatorButton7 1.7E-308;
BA_ "SPN" SG_ 2432656775 pOperatorButton8 524052;
BA_ "SigType" SG_ 2432656775 pOperatorButton8 1.7E-308;
BA_ "SPN" SG_ 2432656775 pOperatorButton9 524051;
BA_ "SigType" SG_ 2432656775 pOperatorButton9 1.7E-308;
BA_ "SPN" SG_ 2432656775 pOperatorButton10 524050;
BA_ "SigType" SG_ 2432656775 pOperatorButton10 1.7E-308;
BA_ "SPN" SG_ 2432656775 pOperatorButton11 524049;
BA_ "SigType" SG_ 2432656775 pOperatorButton11 1.7E-308;
BA_ "SPN" SG_ 2432656775 pOperatorButton12 524048;
BA_ "SigType" SG_ 2432656775 pOperatorButton12 1.7E-308;
BA_ "SPN" SG_ 2432656775 pOperatorButton13 524047;
BA_ "SigType" SG_ 2432656775 pOperatorButton13 1.7E-308;
BA_ "SPN" SG_ 2432656775 pOperatorButton14 524046;
BA_ "SigType" SG_ 2432656775 pOperatorButton14 1.7E-308;
BA_ "SPN" SG_ 2432656775 pOperatorButton15 524045;
BA_ "SigType" SG_ 2432656775 pOperatorButton15 1.7E-308;
BA_ "SPN" SG_ 2432656775 pOperatorButton16 524044;
BA_ "SigType" SG_ 2432656775 pOperatorButton16 1.7E-308;
BA_ "SPN" SG_ 2432656775 pOperatorButton17 524043;
BA_ "SigType" SG_ 2432656775 pOperatorButton17 1.7E-308;
BA_ "SPN" SG_ 2432656775 pOperatorButton18 524042;
BA_ "SigType" SG_ 2432656775 pOperatorButton18 1.7E-308;
BA_ "SPN" SG_ 2432656775 pOperatorButton19 524041;
BA_ "SigType" SG_ 2432656775 pOperatorButton19 1.7E-308;
BA_ "SPN" SG_ 2432656775 pOperatorButton20 524040;
BA_ "SigType" SG_ 2432656775 pOperatorButton20 1.7E-308;
BA_ "SPN" SG_ 2432656775 pOperatorButton21 524039;
BA_ "SigType" SG_ 2432656775 pOperatorButton21 1.7E-308;
BA_ "SPN" SG_ 2432656775 pOperatorButton22 524038;
BA_ "SigType" SG_ 2432656775 pOperatorButton22 1.7E-308;
BA_ "SPN" SG_ 2432656775 pOperatorButton23 524037;
BA_ "SigType" SG_ 2432656775 pOperatorButton23 1.7E-308;
BA_ "SPN" SG_ 2432656775 pOperatorButton24 524036;
BA_ "SigType" SG_ 2432656775 pOperatorButton24 1.7E-308;
BA_ "SPN" SG_ 2432656775 pOperatorButton25 524035;
BA_ "SigType" SG_ 2432656775 pOperatorButton25 1.7E-308;
BA_ "SPN" SG_ 2432656775 pOperatorButton26 524034;
BA_ "SigType" SG_ 2432656775 pOperatorButton26 1.7E-308;
BA_ "SPN" SG_ 2432656775 pOperatorButton27 520322;
BA_ "SigType" SG_ 2432656775 pOperatorButton27 1.7E-308;
BA_ "SPN" SG_ 2432656775 pOperatorButton28 524032;
BA_ "SigType" SG_ 2432656775 pOperatorButton28 1.7E-308;
BA_ "SPN" SG_ 2432656775 pSideStandStatus 524098;
BA_ "SigType" SG_ 2432656775 pSideStandStatus 1.7E-308;
BA_ "SPN" SG_ 2365449728 HydBrakePressCircuit1 2580;
BA_ "SigType" SG_ 2365449728 HydBrakePressCircuit1 1.7E-308;
BA_ "SPN" SG_ 2365449728 HydBrakePressCircuit2 2581;
BA_ "SigType" SG_ 2365449728 HydBrakePressCircuit2 1.7E-308;
BA_ "SPN" SG_ 2365449728 HydBrkPressWarnStateCir1 2584;
BA_ "SigType" SG_ 2365449728 HydBrkPressWarnStateCir1 1.7E-308;
BA_ "SPN" SG_ 2365449728 HydBrkPressWarnStateCir2 2585;
BA_ "SigType" SG_ 2365449728 HydBrkPressWarnStateCir2 1.7E-308;
BA_ "SPN" SG_ 2365449728 HydBrkPressSupplyStateCir1 2582;
BA_ "SigType" SG_ 2365449728 HydBrkPressSupplyStateCir1 1.7E-308;
BA_ "SPN" SG_ 2365449728 HydBrkPressSupplyStateCir2 2583;
BA_ "SigType" SG_ 2365449728 HydBrkPressSupplyStateCir2 1.7E-308;
BA_ "SPN" SG_ 2365449728 HydBrakeFluidLevelSwitch 2931;
BA_ "SigType" SG_ 2365449728 HydBrakeFluidLevelSwitch 1.7E-308;
BA_ "SPN" SG_ 2566884352 pCurrentRPMRatedTorque 520245;
BA_ "SigType" SG_ 2566884352 pCurrentRPMRatedTorque 1.7E-308;
BA_ "SPN" SG_ 2566884352 pEstimatedTorque 520246;
BA_ "SigType" SG_ 2566884352 pEstimatedTorque 1.7E-308;
BA_ "SPN" SG_ 2566884352 BrakeSwitch 597;
BA_ "SigType" SG_ 2566884352 BrakeSwitch 1.7E-308;
BA_ "SPN" SG_ 2566884352 MessageCounter_GM 4206;
BA_ "SigType" SG_ 2566884352 MessageCounter_GM 1.7E-308;
BA_ "SPN" SG_ 2566884352 MessageChecksum_GM 4207;
BA_ "SigType" SG_ 2566884352 MessageChecksum_GM 1.7E-308;
BA_ "SPN" SG_ 2566842396 CompassBearing 165;
BA_ "SigType" SG_ 2566842396 CompassBearing 1.7E-308;
BA_ "SPN" SG_ 2566877607 pVolumeUnitsSelected 524267;
BA_ "SPN" SG_ 2566877607 pTimeUnitsSelected 524268;
BA_ "SPN" SG_ 2566877607 pTemperatureUnitsSelected 524266;
BA_ "SPN" SG_ 2566877607 pPressureUnitsSelected 524269;
BA_ "SPN" SG_ 2566877607 pHighResTrip2Distance 524264;
BA_ "SPN" SG_ 2566877607 pDistanceUnitsSelected 524265;
BA_ "SPN" SG_ 2566877607 pTPMSLearningStatus 524104;
BA_ "SigType" SG_ 2566877607 pTPMSLearningStatus 1.7E-308;
BA_ "SPN" SG_ 2566877607 pDisplayStatus 524105;
BA_ "SigType" SG_ 2566877607 pDisplayStatus 1.7E-308;
BA_ "SigType" SG_ 2381320220 NMEA_SID 1.7E-308;
BA_ "SigType" SG_ 2381320220 NMEA_Data 1.7E-308;
BA_ "SigType" SG_ 2381320220 NMEA_Source 1.7E-308;
BA_ "SigType" SG_ 2381320220 NMEA_SystemTime 1.7E-308;
BA_ "SigType" SG_ 2314731804 NMEA_Latitude 1.7E-308;
BA_ "SigType" SG_ 2314731804 NMEA_Longitude 1.7E-308;
BA_ "SigType" SG_ 2583298844 NMEA_SID 1.7E-308;
BA_ "SigType" SG_ 2583298844 NMEA_HDOP 1.7E-308;
BA_ "SigType" SG_ 2583298844 NMEA_OpMode 1.7E-308;
BA_ "SigType" SG_ 2583298844 NMEA_SetMode 1.7E-308;
BA_ "SigType" SG_ 2583298844 NMEA_TDOP 1.7E-308;
BA_ "SigType" SG_ 2583298844 NMEA_VDOP 1.7E-308;
BA_ "SigType" SG_ 2314732060 NMEA_COG_Reference 1.7E-308;
BA_ "SigType" SG_ 2314732060 NMEA_CourseOverGround 1.7E-308;
BA_ "SigType" SG_ 2314732060 NMEA_SID 1.7E-308;
BA_ "SigType" SG_ 2314732060 NMEA_SpeedOverGround 1.7E-308;
BA_ "SPN" SG_ 2364607475 HVES1LoCellTModuNo_8243 8243;
BA_ "SPN" SG_ 2364607475 HVES1LoCellTCellNo_8244 8244;
BA_ "SPN" SG_ 2364607475 HVES1HiCellTModuNo_8241 8241;
BA_ "SPN" SG_ 2364607475 HVES1HiCellTCellNo_8242 8242;
BA_ "SPN" SG_ 2364607219 HVES1AvgCellU_8240 8240;
BA_ "SPN" SG_ 2364607219 HVES1LoCellUModuNo_8238 8238;
BA_ "SPN" SG_ 2364607219 HVES1LoCellUCellNo_8239 8239;
BA_ "SPN" SG_ 2364607219 HVES1HiCellUModuNo_8236 8236;
BA_ "SPN" SG_ 2364607219 HVES1HiCellUCellNo_8237 8237;
BA_ "SPN" SG_ 2364606707 HVES1M11OperlSts_8224 8224;
BA_ "SPN" SG_ 2364606707 HVES1M9OperlSts_8222 8222;
BA_ "SPN" SG_ 2364606707 HVES1M8OperlSts_8221 8221;
BA_ "SPN" SG_ 2364606707 HVES1M7OperlSts_8220 8220;
BA_ "SPN" SG_ 2364606707 HVES1M6OperlSts_8219 8219;
BA_ "SPN" SG_ 2364606707 HVES1M5OperlSts_8218 8218;
BA_ "SPN" SG_ 2364606707 HVES1M4OperlSts_8217 8217;
BA_ "SPN" SG_ 2364606707 HVES1M3OperlSts_8216 8216;
BA_ "SPN" SG_ 2364606707 HVES1M2OperlSts_8215 8215;
BA_ "SPN" SG_ 2364606707 HVES1M1OperlSts_8214 8214;
BA_ "SPN" SG_ 2364606707 HVES1M16OperlSts_8229 8229;
BA_ "SPN" SG_ 2364606707 HVES1M15OperlSts_8228 8228;
BA_ "SPN" SG_ 2364606707 HVES1M14OperlSts_8227 8227;
BA_ "SPN" SG_ 2364606707 HVES1M13OperlSts_8226 8226;
BA_ "SPN" SG_ 2364606707 HVES1M12OperlSts_8225 8225;
BA_ "SPN" SG_ 2364606707 HVES1M10OperlSts_8223 8223;
BA_ "SPN" SG_ 2364552947 HVES1CPLDToUndefCause_8114 8114;
BA_ "SPN" SG_ 2364552947 HVES1CPLDTBT_8110 8110;
BA_ "SPN" SG_ 2364552947 HVES1CPLDTBOrCellV_8112 8112;
BA_ "SPN" SG_ 2364552947 HVES1CPLDTBDiagcCdn_8111 8111;
BA_ "SPN" SG_ 2364552947 HVES1CPLDTBCur_8113 8113;
BA_ "SPN" SG_ 2364552947 HVES1DPLDTStOfCha_8109 8109;
BA_ "SPN" SG_ 2364552947 HVES1DPLDTStOfCha_8103 8103;
BA_ "SPN" SG_ 2364552947 HVES1DPLDToUndefCause_8108 8108;
BA_ "SPN" SG_ 2364552947 HVES1DPLDTBT_8104 8104;
BA_ "SPN" SG_ 2364552947 HVES1DPLDTBOrCellV_8106 8106;
BA_ "SPN" SG_ 2364552947 HVES1DPLDTBDiagcCdn_8105 8105;
BA_ "SPN" SG_ 2364552947 HVES1DPLDTBCur_8107 8107;
BA_ "SPN" SG_ 2633785075 HVES1TotEgyThput_8211 8211;
BA_ "SPN" SG_ 2633785075 HVES1TotAccumCha_8212 8212;
BA_ "SPN" SG_ 2633785075 HVES1StOfHealth_8121 8121;
BA_ "SPN" SG_ 2633785075 HVES1CtorOpenUndLoa_8122 8122;
BA_ "SPN" SG_ 2566675955 HVES1RecomMinSOC_8118 8118;
BA_ "SPN" SG_ 2566675955 HVES1RecomMinOpergV_8116 8116;
BA_ "GenSigStartValue" SG_ 2566675955 HVES1RecomMinOpergT_8208 8736;
BA_ "SPN" SG_ 2566675955 HVES1RecomMinOpergT_8208 8208;
BA_ "SPN" SG_ 2566675955 HVES1RecomMaxSOC_8119 8119;
BA_ "SPN" SG_ 2566675955 HVES1RecomMaxOpergV_8117 8117;
BA_ "GenSigStartValue" SG_ 2566675955 HVES1RecomMaxOpergT_8120 8736;
BA_ "SPN" SG_ 2566675955 HVES1RecomMaxOpergT_8120 8120;
BA_ "SPN" SG_ 2566675955 HVES1NomVoltage_8115 8115;
BA_ "SPN" SG_ 2566675955 HVES1CellMinVLim_8210 8210;
BA_ "SPN" SG_ 2566675955 HVES1CellMaxVLim_8209 8209;
BA_ "SPN" SG_ 2364606963 HVES1TMSSLIInPwr_8230 8230;
BA_ "SPN" SG_ 2364606963 HVES1TMSRelHum_8233 8233;
BA_ "SPN" SG_ 2364606963 HVES1TMSMode_8235 8235;
BA_ "SPN" SG_ 2364606963 HVES1TMSHighV_8231 8231;
BA_ "SPN" SG_ 2364606963 HVES1TMSHeatrSts_8234 8234;
BA_ "SPN" SG_ 2364606963 HVES1TMSCpsr_8232 8232;
BA_ "SPN" SG_ 2364580083 HVES1MaxChaVLim_8090 8090;
BA_ "SPN" SG_ 2364580083 HVES1DischaEgyCp_8205 8205;
BA_ "SPN" SG_ 2364580083 HVES1ChaEgyCp_8206 8206;
BA_ "SPN" SG_ 2364577523 HVES1StOfChaSts_8100 8100;
BA_ "SPN" SG_ 2364577523 HVES1OperationlSts_8414 8414;
BA_ "SPN" SG_ 2364577523 HVES1IntChaSts_8207 8207;
BA_ "SPN" SG_ 2364577523 HVES1InertiaSwtSts_8099 8099;
BA_ "SPN" SG_ 2364577523 HVES1HVILSts_8098 8098;
BA_ "SPN" SG_ 2364577523 HVES1HVBusPsvIsoTstSts_8097 8097;
BA_ "SPN" SG_ 2364577523 HVES1HVBusPrechaRlySt_8094 8094;
BA_ "SPN" SG_ 2364577523 HVES1HVBusDiscnctWarn_8093 8093;
BA_ "SPN" SG_ 2364577523 HVES1HVBusCnctnSts_8413 8413;
BA_ "SPN" SG_ 2364577523 HVES1HVBusAcvIsoTstSts_8096 8096;
BA_ "SPN" SG_ 2364577523 HVES1HVBCtorStPos_8091 8091;
BA_ "SPN" SG_ 2364577523 HVES1HVBCtorStNeg_8092 8092;
BA_ "SPN" SG_ 2364577523 HVES1CtrOfPackCtorSt_8095 8095;
BA_ "SPN" SG_ 2364577523 HVES1CellBalnSts_8101 8101;
BA_ "SPN" SG_ 2364577523 HVES1CellBalnAcv_8102 8102;
BA_ "GenSigStartValue" SG_ 2364577267 HVES1ElectronicsT_8204 40;
BA_ "SPN" SG_ 2364577267 HVES1ElectronicsT_8204 8204;
BA_ "GenSigStartValue" SG_ 2364577267 HVES1OutletCooltT_8089 40;
BA_ "SPN" SG_ 2364577267 HVES1OutletCooltT_8089 8089;
BA_ "GenSigStartValue" SG_ 2364577267 HVES1InletCooltT_8088 40;
BA_ "SPN" SG_ 2364577267 HVES1InletCooltT_8088 8088;
BA_ "SPN" SG_ 2364577267 HVES1IgVoltage_8087 8087;
BA_ "SPN" SG_ 2364577267 HVES1BusVoltage_8086 8086;
BA_ "SPN" SG_ 2364577011 HVES1MinCellStOCha_8084 8084;
BA_ "SPN" SG_ 2364577011 HVES1MaxCellStOCha_8085 8085;
BA_ "GenSigStartValue" SG_ 2364577011 HVES1DchaCurLim_8082 32000;
BA_ "SPN" SG_ 2364577011 HVES1DchaCurLim_8082 8082;
BA_ "GenSigStartValue" SG_ 2364577011 HVES1ChaCurLim_8083 32000;
BA_ "SPN" SG_ 2364577011 HVES1ChaCurLim_8083 8083;
BA_ "SPN" SG_ 2364576755 HVES1DischargeCap_8079 8079;
BA_ "SPN" SG_ 2364576755 HVES1ChargeCap_8080 8080;
BA_ "SPN" SG_ 2364576755 HVES1CellBalnCt_8081 8081;
BA_ "GenSigStartValue" SG_ 2364576499 HVES1LowestCellT_8076 8736;
BA_ "SPN" SG_ 2364576499 HVES1LowestCellT_8076 8076;
BA_ "GenSigStartValue" SG_ 2364576499 HVES1HighestCellT_8075 8736;
BA_ "SPN" SG_ 2364576499 HVES1HighestCellT_8075 8075;
BA_ "SPN" SG_ 2364576499 HVES1CellTDftlSts_8078 8078;
BA_ "GenSigStartValue" SG_ 2364576499 HVES1AverageCellT_8077 8736;
BA_ "SPN" SG_ 2364576499 HVES1AverageCellT_8077 8077;
BA_ "SPN" SG_ 2364576243 HVES1LowCellVolt_5923 5923;
BA_ "SPN" SG_ 2364576243 HVES1HiCellVolt_5922 5922;
BA_ "SPN" SG_ 2364576243 HVES1FastUpdStOCh_5921 5921;
BA_ "SPN" SG_ 2364576243 HVES1CellVoltDftlSts_5924 5924;
BA_ "SPN" SG_ 2364575987 HVES1VoltageLevel_5919 5919;
BA_ "GenSigStartValue" SG_ 2364575987 HVES1Current_5920 32000;
BA_ "SPN" SG_ 2364575987 HVES1Current_5920 5920;
BA_ "SPN" SG_ 2364575987 HVES1AvlChPwr_5918 5918;
BA_ "SPN" SG_ 2364575987 HVES1AvlDchaPwr_5917 5917;
BA_ "SPN" SG_ 2558263038 PECPSC_7969 7969;
BA_ "SPN" SG_ 2558263038 PECPPS_7970 7970;
BA_ "SPN" SG_ 2558263038 PECPPH_7968 7968;
BA_ "SPN" SG_ 2558263038 PECPEC_7967 7967;
BA_ "SPN" SG_ 2558197502 PMCPPS_7982 7982;
BA_ "SPN" SG_ 2558197502 PMCPSC_7981 7981;
BA_ "SPN" SG_ 2558197502 PMCPPH_7980 7980;
BA_ "SPN" SG_ 2558197502 PMCPEC_7979 7979;
BA_ "SPN" SG_ 2558131966 PMOPPSC_7994 7994;
BA_ "SPN" SG_ 2558131966 PMOPSC_7993 7993;
BA_ "SPN" SG_ 2558131966 PMOPPH_7992 7992;
BA_ "SPN" SG_ 2558131966 PMOPEC_7991 7991;
BA_ "SPN" SG_ 2558066430 PECF1PS_8006 8006;
BA_ "SPN" SG_ 2558066430 PECF1SC_8005 8005;
BA_ "SPN" SG_ 2558066430 PECF1PH_8004 8004;
BA_ "SPN" SG_ 2558066430 PECF1EC_8003 8003;
BA_ "SPN" SG_ 2558000894 PECF2PS_8018 8018;
BA_ "SPN" SG_ 2558000894 PECF2SC_8017 8017;
BA_ "SPN" SG_ 2558000894 PECF2PH_8016 8016;
BA_ "SPN" SG_ 2558000894 PECF2EC_8015 8015;
BA_ "SPN" SG_ 2557935358 PECF3PS_8030 8030;
BA_ "SPN" SG_ 2557935358 PECF3SC_8029 8029;
BA_ "SPN" SG_ 2557935358 PECF3PH_8028 8028;
BA_ "SPN" SG_ 2557935358 PECF3EC_8027 8027;
BA_ "SPN" SG_ 2557869822 PMCF1PS_8042 8042;
BA_ "SPN" SG_ 2557869822 PMCF1SC_8041 8041;
BA_ "SPN" SG_ 2557869822 PMCF1PH_8040 8040;
BA_ "SPN" SG_ 2557869822 PMCF1EC_8039 8039;
BA_ "SPN" SG_ 2557804286 PMCF2PS_8054 8054;
BA_ "SPN" SG_ 2557804286 PMCF2SC_8053 8053;
BA_ "SPN" SG_ 2557804286 PMCF2PH_8052 8052;
BA_ "SPN" SG_ 2557804286 PMCF2EC_8051 8051;
BA_ "SPN" SG_ 2557738750 PMCF3PS_8066 8066;
BA_ "SPN" SG_ 2557738750 PMCF3SC_8065 8065;
BA_ "SPN" SG_ 2557738750 PMCF3PH_8064 8064;
BA_ "SPN" SG_ 2557738750 PMCF3EC_8063 8063;
BA_ "SPN" SG_ 2557673214 ODMFB5CC_8203 8203;
BA_ "SPN" SG_ 2557673214 ODMFB5CC_8202 8202;
BA_ "SPN" SG_ 2557673214 ODMFB5CC_8201 8201;
BA_ "SPN" SG_ 2557673214 ODMFB5CC_8200 8200;
BA_ "SPN" SG_ 2557673214 ODMFB5CC_8199 8199;
BA_ "SPN" SG_ 2557673214 ODMFB7CC_8198 8197;
BA_ "SPN" SG_ 2557673214 ODMFB6CC_8197 8197;
BA_ "SPN" SG_ 2557673214 ODMFB5CC_8196 8196;
BA_ "SPN" SG_ 2557673214 ODMFB4CC_8195 8195;
BA_ "SPN" SG_ 2557673214 ODMFB2CC_8193 8193;
BA_ "SPN" SG_ 2557673214 ODMFB3CC_8194 8194;
BA_ "SPN" SG_ 2557673214 ODMFB1CC_8192 8192;
BA_ "SPN" SG_ 2557673214 ODMCIN_8191 8191;
BA_ "SPN" SG_ 2350644979 HVES1_HVBLSRCR_8434 8434;
BA_ "SPN" SG_ 2350644979 HVES1_HVBHSRCR_8433 8433;
BA_ "SPN" SG_ 2350644979 HVES1_OC_8412 8412;
BA_ "SPN" SG_ 2350644979 HVES1_EICC_8213 8213;
BA_ "SPN" SG_ 2350644979 HVES1_CBC_8127 8127;
BA_ "SPN" SG_ 2350644979 HVES1_HVBPITC_8126 8126;
BA_ "SPN" SG_ 2350644979 HVES1_HVBAITC_8125 8125;
BA_ "SPN" SG_ 2350644979 HVES1_PDC_8124 8124;
BA_ "SPN" SG_ 2350644979 HVES1_HVBCC_8123 8123;
BA_ "SPN" SG_ 2566658558 TotalHaulCycleCount 7700;
BA_ "SigType" SG_ 2566658558 TotalHaulCycleCount 1;
BA_ "SPN" SG_ 2566658558 TotalDeliveredPayloadWeight 7699;
BA_ "SigType" SG_ 2566658558 TotalDeliveredPayloadWeight 1;
BA_ "SPN" SG_ 2566658302 TotalPayloadTransactionCount 7701;
BA_ "SigType" SG_ 2566658302 TotalPayloadTransactionCount 1;
BA_ "SPN" SG_ 2499548158 RightRearCabDoorLatchPos 7726;
BA_ "SPN" SG_ 2499548158 LeftRearCabDoorLatchPos 7725;
BA_ "SPN" SG_ 2499548158 RightFrontCabDoorLatchPos 7724;
BA_ "SPN" SG_ 2499548158 LeftFrontCabDoorLatchPos 7723;
BA_ "SPN" SG_ 2499547902 MirrorRight2HeatCmd 7744;
BA_ "SigType" SG_ 2499547902 MirrorRight2HeatCmd 5;
BA_ "SPN" SG_ 2499547902 MirrorLeft2HeatCmd 7743;
BA_ "SigType" SG_ 2499547902 MirrorLeft2HeatCmd 5;
BA_ "SPN" SG_ 2499547902 MirrorRight1HeatCmd 7742;
BA_ "SigType" SG_ 2499547902 MirrorRight1HeatCmd 5;
BA_ "SPN" SG_ 2499547902 MirrorLeft1HeatCmd 7741;
BA_ "SigType" SG_ 2499547902 MirrorLeft1HeatCmd 5;
BA_ "SPN" SG_ 2499547902 MirrorRight2VerticalCmd 7740;
BA_ "SigType" SG_ 2499547902 MirrorRight2VerticalCmd 5;
BA_ "SPN" SG_ 2499547902 MirrorRight2HorizontalCmd 7739;
BA_ "SigType" SG_ 2499547902 MirrorRight2HorizontalCmd 5;
BA_ "SPN" SG_ 2499547902 MirrorLeft2VerticalCmd 7738;
BA_ "SigType" SG_ 2499547902 MirrorLeft2VerticalCmd 5;
BA_ "SPN" SG_ 2499547902 MirrorLeft2HorizontalCmd 7737;
BA_ "SigType" SG_ 2499547902 MirrorLeft2HorizontalCmd 5;
BA_ "SPN" SG_ 2499547902 MirrorRight1VerticalCmd 7736;
BA_ "SigType" SG_ 2499547902 MirrorRight1VerticalCmd 5;
BA_ "SPN" SG_ 2499547902 MirrorRight1HorizontalCmd 7735;
BA_ "SigType" SG_ 2499547902 MirrorRight1HorizontalCmd 5;
BA_ "SPN" SG_ 2499547902 MirrorLeft1VerticalCmd 7734;
BA_ "SigType" SG_ 2499547902 MirrorLeft1VerticalCmd 5;
BA_ "SPN" SG_ 2499547902 MirrorLeft1HorizontalCmd 7733;
BA_ "SigType" SG_ 2499547902 MirrorLeft1HorizontalCmd 5;
BA_ "SPN" SG_ 2499547902 RightRearWindowPosCmd 7732;
BA_ "SPN" SG_ 2499547902 LeftRearWindowPosCmd 7731;
BA_ "SPN" SG_ 2499547902 RightFrontWindowPosCmd 7730;
BA_ "SPN" SG_ 2499547902 LeftFrontWindowPosCmd 7729;
BA_ "SPN" SG_ 2499547902 RemoteCabDoorLockReq 7728;
BA_ "SPN" SG_ 2499547902 DoorsLockActCmd 7727;
BA_ "SPN" SG_ 2566656510 EngTotalGasIdleFuelVolumeUsed 7456;
BA_ "SigType" SG_ 2566656510 EngTotalGasIdleFuelVolumeUsed 1;
BA_ "SPN" SG_ 2566656510 EngTotalGasFuelVolumeUsed 7455;
BA_ "SigType" SG_ 2566656510 EngTotalGasFuelVolumeUsed 1;
BA_ "SPN" SG_ 2431710718 Checksum 7758;
BA_ "SPN" SG_ 2431710718 MessageCounter 7757;
BA_ "SPN" SG_ 2431710718 AutomaticEngStartConsentSummary 7756;
BA_ "SigType" SG_ 2431710718 AutomaticEngStartConsentSummary 5;
BA_ "SPN" SG_ 2431710718 OpEngStartConsentSummary 7755;
BA_ "SigType" SG_ 2431710718 OpEngStartConsentSummary 5;
BA_ "SPN" SG_ 2431710718 ReqLatchStatus 7754;
BA_ "SPN" SG_ 2431710718 StarterCmd 7753;
BA_ "SPN" SG_ 2431710718 CtrlMessageRate 7752;
BA_ "SigType" SG_ 2431710718 CtrlMessageRate 5;
BA_ "SPN" SG_ 2431708670 Checksum 7751;
BA_ "SPN" SG_ 2431708670 MessageCounter 7750;
BA_ "SPN" SG_ 2431708670 Starter2Feedback 7749;
BA_ "SPN" SG_ 2431708670 Starter1Feedback 7748;
BA_ "SPN" SG_ 2431708670 AbortReq 7747;
BA_ "SigType" SG_ 2431708670 AbortReq 5;
BA_ "SPN" SG_ 2431708670 Consent 7746;
BA_ "SPN" SG_ 2431708670 Req 7745;
BA_ "SigType" SG_ 2431708670 Req 5;
BA_ "SPN" SG_ 2566661118 EngTotalDieselFuelDemand 7597;
BA_ "SigType" SG_ 2566661118 EngTotalDieselFuelDemand 1;
BA_ "SPN" SG_ 2633769726 TotalEngEnergy 7608;
BA_ "SigType" SG_ 2633769726 TotalEngEnergy 1;
BA_ "SPN" SG_ 2565926142 O2Snsr2PreliminaryFMI 7692;
BA_ "SPN" SG_ 2565926142 NOxSnsr2SelfDiagStatus 7691;
BA_ "SPN" SG_ 2565926142 NOxSnsr2PreliminaryFMI 7690;
BA_ "SPN" SG_ 2565926142 GasSnsr2HtrCtrl 7689;
BA_ "SigType" SG_ 2565926142 GasSnsr2HtrCtrl 5;
BA_ "SPN" SG_ 2565926142 GasSnsr2HtrPreliminaryFMI 7688;
BA_ "SPN" SG_ 2565926142 WRPercentO22ReadingStable 7687;
BA_ "SigType" SG_ 2565926142 WRPercentO22ReadingStable 5;
BA_ "SPN" SG_ 2565926142 NOx2ReadingStable 7686;
BA_ "SigType" SG_ 2565926142 NOx2ReadingStable 5;
BA_ "SPN" SG_ 2565926142 GasSnsr2AtTemp 7685;
BA_ "SigType" SG_ 2565926142 GasSnsr2AtTemp 5;
BA_ "SPN" SG_ 2565926142 GasSnsr2PwrInRange 7684;
BA_ "SigType" SG_ 2565926142 GasSnsr2PwrInRange 5;
BA_ "SPN" SG_ 2565926142 PercentO22 7683;
BA_ "SigType" SG_ 2565926142 PercentO22 1;
BA_ "SPN" SG_ 2565926142 NOx2 7682;
BA_ "SigType" SG_ 2565926142 NOx2 1;
BA_ "SPN" SG_ 2565925886 O2Snsr2PreliminaryFMI 7681;
BA_ "SPN" SG_ 2565925886 NOxSnsr2SelfDiagStatus 7680;
BA_ "SPN" SG_ 2565925886 SCRInNOxSnsr2PreliminaryFMI 7679;
BA_ "SPN" SG_ 2565925886 GasSnsr2HtrCtrl 7678;
BA_ "SigType" SG_ 2565925886 GasSnsr2HtrCtrl 5;
BA_ "SPN" SG_ 2565925886 GasSnsr2HtrPreliminaryFMI 7677;
BA_ "SPN" SG_ 2565925886 WRPercentO22ReadingStable 7676;
BA_ "SigType" SG_ 2565925886 WRPercentO22ReadingStable 5;
BA_ "SPN" SG_ 2565925886 SCRInNOx2ReadingStable 7675;
BA_ "SigType" SG_ 2565925886 SCRInNOx2ReadingStable 5;
BA_ "SPN" SG_ 2565925886 GasSnsr2AtTemp 7674;
BA_ "SigType" SG_ 2565925886 GasSnsr2AtTemp 5;
BA_ "SPN" SG_ 2565925886 GasSnsr2PwrInRange 7673;
BA_ "SigType" SG_ 2565925886 GasSnsr2PwrInRange 5;
BA_ "SPN" SG_ 2565925886 PercentO22 7672;
BA_ "SigType" SG_ 2565925886 PercentO22 1;
BA_ "SPN" SG_ 2565925886 SCRInNOx2 7671;
BA_ "SigType" SG_ 2565925886 SCRInNOx2 1;
BA_ "SPN" SG_ 2565925630 O2Snsr2PreliminaryFMI 7670;
BA_ "SPN" SG_ 2565925630 NOxSnsr2SelfDiagStatus 7669;
BA_ "SPN" SG_ 2565925630 NOxSnsr2PreliminaryFMI 7668;
BA_ "SPN" SG_ 2565925630 Snsr2HtrCtrl 7667;
BA_ "SigType" SG_ 2565925630 Snsr2HtrCtrl 5;
BA_ "SPN" SG_ 2565925630 Snsr2HtrPreliminaryFMI 7666;
BA_ "SPN" SG_ 2565925630 WRPercentO22ReadingStable 7665;
BA_ "SigType" SG_ 2565925630 WRPercentO22ReadingStable 5;
BA_ "SPN" SG_ 2565925630 NOx2ReadingStable 7664;
BA_ "SigType" SG_ 2565925630 NOx2ReadingStable 5;
BA_ "SPN" SG_ 2565925630 Snsr2AtTemp 7663;
BA_ "SigType" SG_ 2565925630 Snsr2AtTemp 5;
BA_ "SPN" SG_ 2565925630 Snsr2PwrInRange 7662;
BA_ "SigType" SG_ 2565925630 Snsr2PwrInRange 5;
BA_ "SPN" SG_ 2565925630 PercentO22 7661;
BA_ "SigType" SG_ 2565925630 PercentO22 1;
BA_ "SPN" SG_ 2565925630 NOx2 7660;
BA_ "SigType" SG_ 2565925630 NOx2 1;
BA_ "SPN" SG_ 2565925374 O2Snsr2PreliminaryFMI 7659;
BA_ "SPN" SG_ 2565925374 NOxSnsr2SelfDiagStatus 7658;
BA_ "SPN" SG_ 2565925374 SCRInNOxSnsr2PreliminaryFMI 7657;
BA_ "SPN" SG_ 2565925374 Snsr2HtrCtrl 7656;
BA_ "SigType" SG_ 2565925374 Snsr2HtrCtrl 5;
BA_ "SPN" SG_ 2565925374 Snsr2HtrPreliminaryFMI 7655;
BA_ "SPN" SG_ 2565925374 WRPercentO22ReadingStable 7654;
BA_ "SigType" SG_ 2565925374 WRPercentO22ReadingStable 5;
BA_ "SPN" SG_ 2565925374 SCRInNOx2ReadingStable 7653;
BA_ "SigType" SG_ 2565925374 SCRInNOx2ReadingStable 5;
BA_ "SPN" SG_ 2565925374 Snsr2AtTemp 7652;
BA_ "SigType" SG_ 2565925374 Snsr2AtTemp 5;
BA_ "SPN" SG_ 2565925374 Snsr2PwrInRange 7651;
BA_ "SigType" SG_ 2565925374 Snsr2PwrInRange 5;
BA_ "SPN" SG_ 2565925374 PercentO22 7650;
BA_ "SigType" SG_ 2565925374 PercentO22 1;
BA_ "SPN" SG_ 2565925374 SCRInNOx2 7649;
BA_ "SigType" SG_ 2565925374 SCRInNOx2 1;
BA_ "SPN" SG_ 2364598526 FuelAct4CtrlCmd 7594;
BA_ "SigType" SG_ 2364598526 FuelAct4CtrlCmd 1;
BA_ "SPN" SG_ 2364598526 FuelAct3CtrlCmd 7593;
BA_ "SigType" SG_ 2364598526 FuelAct3CtrlCmd 1;
BA_ "SPN" SG_ 2558525182 Num7586 7586;
BA_ "SigType" SG_ 2558525182 Num7586 8;
BA_ "SPN" SG_ 2558525182 Location_7585 7585;
BA_ "SPN" SG_ 2558525182 Num_7584 7584;
BA_ "SigType" SG_ 2558525182 Num_7584 1;
BA_ "SPN" SG_ 2558525182 NumOfTireSensors_7583 7583;
BA_ "SigType" SG_ 2558525182 NumOfTireSensors_7583 1;
BA_ "SPN" SG_ 2350841598 TrqRampMaxSpdCmd 7592;
BA_ "SigType" SG_ 2350841598 TrqRampMaxSpdCmd 1;
BA_ "GenSigStartValue" SG_ 2350841598 TrqRampTimeCmd 1;
BA_ "SPN" SG_ 2350841598 TrqRampTimeCmd 7591;
BA_ "SigType" SG_ 2350841598 TrqRampTimeCmd 1;
BA_ "SPN" SG_ 2350841598 ExcitationMaxCurrentLmt 7590;
BA_ "SigType" SG_ 2350841598 ExcitationMaxCurrentLmt 1;
BA_ "SPN" SG_ 2350841598 SetpointVoltageCmd 7589;
BA_ "SigType" SG_ 2350841598 SetpointVoltageCmd 1;
BA_ "SPN" SG_ 2566838014 ShutdownSw 7555;
BA_ "SigType" SG_ 2566838014 ShutdownSw 4;
BA_ "SPN" SG_ 2566838014 PropulsionDisableSw 7554;
BA_ "SigType" SG_ 2566838014 PropulsionDisableSw 4;
BA_ "SPN" SG_ 2566838014 HybrdSystmCstngRgnrtvBrkngLvlSlc 7556;
BA_ "SigType" SG_ 2566838014 HybrdSystmCstngRgnrtvBrkngLvlSlc 1;
BA_ "SPN" SG_ 2566838014 HybrdSystmBrkPdlRgnrtvBrkngDsblS 7553;
BA_ "SigType" SG_ 2566838014 HybrdSystmBrkPdlRgnrtvBrkngDsblS 4;
BA_ "SPN" SG_ 2566838014 HybrdSystmRgnrtvBrkngDsbleSwitch 7552;
BA_ "SigType" SG_ 2566838014 HybrdSystmRgnrtvBrkngDsbleSwitch 4;
BA_ "SPN" SG_ 2566838014 HybrdSystmOffBrdChrgrCnnctnSttus 7551;
BA_ "SigType" SG_ 2566838014 HybrdSystmOffBrdChrgrCnnctnSttus 4;
BA_ "SPN" SG_ 2566838014 HybrdSystmPwrElctrncsClntLvlSwtc 7550;
BA_ "SigType" SG_ 2566838014 HybrdSystmPwrElctrncsClntLvlSwtc 4;
BA_ "SPN" SG_ 2566838014 HybrdSystmPrplsnClantLevelSwitch 7549;
BA_ "SigType" SG_ 2566838014 HybrdSystmPrplsnClantLevelSwitch 4;
BA_ "SPN" SG_ 2566838014 HybrdSystmPrtctionOverrideSwitch 7548;
BA_ "SigType" SG_ 2566838014 HybrdSystmPrtctionOverrideSwitch 4;
BA_ "SPN" SG_ 2566761726 EngIdleFuelFlowRateThreshold 2778;
BA_ "SigType" SG_ 2566761726 EngIdleFuelFlowRateThreshold 1;
BA_ "SPN" SG_ 2566761726 NmbrOfFlCnsmptnMntrngTransducers 2777;
BA_ "SigType" SG_ 2566761726 NmbrOfFlCnsmptnMntrngTransducers 1;
BA_ "SPN" SG_ 2566756350 EngFuelReturnTemp 2776;
BA_ "SigType" SG_ 2566756350 EngFuelReturnTemp 1;
BA_ "SPN" SG_ 2566756350 EngFuelSupplyTemp 2775;
BA_ "SigType" SG_ 2566756350 EngFuelSupplyTemp 1;
BA_ "SPN" SG_ 2566756094 EngFuelReturnFlowRate 2774;
BA_ "SigType" SG_ 2566756094 EngFuelReturnFlowRate 1;
BA_ "SPN" SG_ 2566756094 EngFuelSupplyFlowRate 2773;
BA_ "SigType" SG_ 2566756094 EngFuelSupplyFlowRate 1;
BA_ "SPN" SG_ 2566687998 TimeBetweenRegens 6776;
BA_ "SigType" SG_ 2566687998 TimeBetweenRegens 1;
BA_ "SPN" SG_ 2566687998 ActiveAccumulationTime 6775;
BA_ "SigType" SG_ 2566687998 ActiveAccumulationTime 1;
BA_ "SPN" SG_ 2566687998 RegenSt 6774;
BA_ "SPN" SG_ 2566687998 RegenStatus 6773;
BA_ "SigType" SG_ 2566687998 RegenStatus 5;
BA_ "SPN" SG_ 2566687998 HtrSt 6772;
BA_ "SigType" SG_ 2566687998 HtrSt 5;
BA_ "SPN" SG_ 2566687998 Res 6771;
BA_ "SigType" SG_ 2566687998 Res 1;
VAL_ 2565866752 TransmissionRqstedRange 18464 " H" 19488 " L" 20000 " N" 20512 " P" 21024 " R";
VAL_ 2566844806 TwoSpeedAxleSwitch 0 "LowSpeedRange" 1 "HighSpeedRange" 2 "Error" 3 "NotAvailable";
VAL_ 2566844806 ParkingBrakeSwitch 0 "NotSet" 1 "Set" 2 "Error" 3 "NotAvailable";
VAL_ 2566844806 CruiseCtrlActive 0 "SwitchedOff" 1 "SwitchedOn" 2 "Error" 3 "NotAvailable";
VAL_ 2566844806 CruiseCtrlEnableSwitch 0 "Disabled" 1 "Enabled" 2 "Error" 3 "NotAvailable";
VAL_ 2566844806 BrakeSwitch 0 "PedalReleased" 1 "PedalDepressed" 2 "Error" 3 "NotAvailable";
VAL_ 2566844806 ClutchSwitch 0 "PedalReleased" 1 "PedalDepressed" 2 "Error" 3 "NotAvailable";
VAL_ 2566844806 CruiseCtrlSetSwitch 0 "NotSet" 1 "Set" 2 "Error" 3 "NotAvailable";
VAL_ 2566844806 CruiseCtrlCoastSwitch 0 "NotCoast" 1 "Coast" 2 "Error" 3 "NotAvailable";
VAL_ 2566844806 CruiseCtrlResumeSwitch 0 "NotResume" 1 "Resume" 2 "Error" 3 "NotAvailable";
VAL_ 2566844806 CruiseCtrlAccelerateSwitch 0 "NotAccelerate" 1 "Accelerate" 2 "Error" 3 "NotAvailable";
VAL_ 2566844806 pOdometerDriveBit 0 "State A" 1 "State B" 2 "Error" 3 "Not Available/Initialize";
VAL_ 2566844806 CruiseCtrlPauseSw 0 "Off" 1 "On" 2 "Error" 3 "Take No Action";
VAL_ 2566844806 pCruiseEnableStatus 0 "Not enabled." 1 "Enabled but not activated." 2 "Reserved" 14 "Error Indicator" 15 "Not Available";
VAL_ 2565537345 RqstedPGN 255 "NotAvailable";
VAL_ 2566857216 pRawBrakeStatus 0 "Brake Pedal Released" 1 "Brake Pedal Depressed" 2 "Error" 3 "Not Available";
VAL_ 2365530123 pEngCtlMode 0 "No Control Request" 1 "Engine Speed Request" 2 "Engine Speed Limit" 3 "Engine Torque Request" 4 "Engine Torque Limit" 5 "Reserved for Future Use" 6 "Reserved for Future Use" 7 "Reserved for Future Use" 8 "Reserved for Future Use" 9 "Reserved for Future Use" 10 "Reserved for Future Use" 11 "Reserved for Future Use" 12 "Reserved for Future Use" 13 "Reserved for Future Use" 14 "Error" 15 "Not Available";
VAL_ 2365530123 pEngCtlReq 0 "Low Idle Governor/No Request" 1 "Accel Pedal/Operator Selection" 2 "Cruise Control" 3 "PTO Governor" 4 "Road Speed Governor" 5 "ASR Control" 6 "Transmission Control" 7 "ABS Control" 8 "Torque Limiting" 9 "High Speed Governor" 10 "Braking System" 11 "Remote Accelerator" 12 "Reserved for Future Use" 13 "Reserved for Future Use" 14 "Error" 15 "Not Available";
VAL_ 2566834822 DM_FlashRedStopLamp 0 "Slow Flash (1 Hz, 50% DC)" 1 "Fast Flash (2 Hz, 50% DC)" 2 "Reserved" 3 "Unavailable / Do Not Flash";
VAL_ 2566834822 DM_FlashProtectLamp 0 "Slow Flash (1 Hz, 50% DC)" 1 "Fast Flash (2 Hz, 50% DC)" 2 "Reserved" 3 "Unavailable / Do Not Flash";
VAL_ 2566834822 DM_FlashMalfuncIndicatorLamp 0 "Slow Flash (1 Hz, 50% DC)" 1 "Fast Flash (2 Hz, 50% DC)" 2 "Reserved" 3 "Unavailable / Do Not Flash";
VAL_ 2566834822 DM_FlashAmberWarningLamp 0 "Slow Flash (1 Hz, 50% DC)" 1 "Fast Flash (2 Hz, 50% DC)" 2 "Reserved" 3 "Unavailable / Do Not Flash";
VAL_ 2566834822 DM_ProtectLampStatus 0 "Lamp off" 1 "Lamp on" 2 "Reserved" 3 "Not available";
VAL_ 2566834822 DM_RedStopLampState 0 "Lamp off" 1 "Lamp on" 2 "Reserved" 3 "Not available";
VAL_ 2566834822 DM_AmberWrningLmpStatus 0 "Lamp off" 1 "Lamp on" 2 "Reserved" 3 "Not available";
VAL_ 2566834822 DM_MalfuncnIndicatorLampStatus 0 "Lamp off" 1 "Lamp on" 2 "Reserved" 3 "Not available";
VAL_ 2564358137 DM15_Seed 0 "Seed Complete - send key" 1 "Use Long Seed or Key" 65535 "No Further Key required of Tool";
VAL_ 2564358137 DM15_Error_Ind_EDC_Parameter 0 "No Error" 1 "Error NOT identified" 2 "Currently processing for another" 16 "Currently processing Erase Req" 17 "Currently processing Read Req" 18 "Currently processing Write Req" 19 "Currently processing Status Req" 22 "Currently processing Boot Req" 23 "Currently processing Gen Req" 31 "Currently processing request" 32 "EDC parm not correct for data" 33 "RAM did not verify on Write" 34 "FLASH did not verify on Write" 35 "PROM did not verify on Write" 36 "Internal failure preventing req" 256 "Addressing or DATA General Error" 257 "Addressing Error bounds invalid" 258 "Addressing Error Length invalid" 259 "Addressing Error exceeded memory" 260 "Addressing Error requires erase" 261 "Addressing Error requires erase" 262 "Addressing Error requires trans" 263 "Addressing Error wrong memory" 264 "Addressing Error invalid bounds" 265 "DATA Error invalid value ranges" 266 "DATA Error NAME unexpected value" 4096 "Security Error General" 4097 "Security Error Invalid Password" 4098 "Security Error Invalid User Lvl" 4099 "Security Error Invalid Key" 4100 "Security Error NOT in Diag mode" 4101 "Security Error NOT in Dev mode" 4102 "Security Error - Engine running" 4103 "Security Error - NOT in Park" 65536 "Abort from external" 65537 "Too Many Retries" 65538 "NO response in the time allowed" 65539 "Transport NOT initiated in time" 65540 "Transport NOT completed in time" 16777215 "No Error Indicator Available";
VAL_ 2564358137 DM15_EDCP_Extension 0 "Completed" 2 "More, Higher order EDC Parameter" 3 "More, Lower order EDC Parameter" 6 "Data in Error Indicator" 7 "Data in Error Indicator" 255 "No Error/EDC Parameter Available";
VAL_ 2564358137 DM15_Status 0 "Proceed" 1 "Busy" 2 "Reserved" 3 "Reserved" 4 "Operation Completed" 5 "Operation Failed" 6 "Reserved" 7 "Reserved";
VAL_ 2432656519 pInfotainmentJoystick2 0 "Neutral" 1 "Up" 2 "Down" 3 "Left" 4 "Right" 5 "Center";
VAL_ 2432656519 pInfotainmentJoystick1 0 "Neutral" 1 "Up" 2 "Down" 3 "Left" 4 "Right" 5 "Center";
VAL_ 2432656519 pInfotainmentRemoteButton01 0 "Not Pressed" 1 "Pressed" 2 "Error" 3 "Not Available";
VAL_ 2432656519 pInfotainmentRemoteButton02 0 "Not Pressed" 1 "Pressed" 2 "Error" 3 "Not Available";
VAL_ 2432656519 pInfotainmentRemoteButton03 0 "Not Pressed" 1 "Pressed" 2 "Error" 3 "Not Available";
VAL_ 2432656519 pInfotainmentRemoteButton04 0 "Not Pressed" 1 "Pressed" 2 "Error" 3 "Not Available";
VAL_ 2432656519 pInfotainmentRemoteButton05 0 "Not Pressed" 1 "Pressed" 2 "Error" 3 "Not Available";
VAL_ 2432656519 pInfotainmentRemoteButton06 0 "Not Pressed" 1 "Pressed" 2 "Error" 3 "Not Available";
VAL_ 2432656519 pInfotainmentRemoteButton07 0 "Not Pressed" 1 "Pressed" 2 "Error" 3 "Not Available";
VAL_ 2432656519 pInfotainmentRemoteButton08 0 "Not Pressed" 1 "Pressed" 2 "Error" 3 "Not Available";
VAL_ 2432656519 pInfotainmentRemoteButton09 0 "Not Pressed" 1 "Pressed" 2 "Error" 3 "Not Available";
VAL_ 2432656519 pInfotainmentRemoteButton10 0 "Not Pressed" 1 "Pressed" 2 "Error" 3 "Not Available";
VAL_ 2432656519 pInfotainmentRemoteButton11 0 "Not Pressed" 1 "Pressed" 2 "Error" 3 "Not Available";
VAL_ 2432656519 pInfotainmentRemoteButton12 0 "Not Pressed" 1 "Pressed" 2 "Error" 3 "Not Available";
VAL_ 2432656775 pOperatorButton29 0 "Button Not Pressed" 1 "Button Pressed" 2 "Error" 3 "Not Available";
VAL_ 2432656775 pOperatorButton1 0 "Not Pressed" 1 "Pressed" 2 "Error" 3 "Not Available";
VAL_ 2432656775 pOperatorButton2 0 "Active" 1 "Inactive" 2 "Error" 3 "Not Available";
VAL_ 2432656775 pOperatorButton3 0 "Not Pressed" 1 "Pressed" 2 "Error" 3 "Not Available";
VAL_ 2432656775 pOperatorButton4 0 "Not Pressed" 1 "Pressed" 2 "Error" 3 "Not Available";
VAL_ 2432656775 pOperatorButton5 0 "Not Pressed" 1 "Pressed" 2 "Error" 3 "Not Available";
VAL_ 2432656775 pOperatorButton6 0 "Not Pressed" 1 "Pressed" 2 "Error" 3 "Not Available";
VAL_ 2432656775 pOperatorButton7 0 "Not Pressed" 1 "Pressed" 2 "Error" 3 "Not Available";
VAL_ 2432656775 pOperatorButton8 0 "Not Pressed" 1 "Pressed" 2 "Error" 3 "Not Available";
VAL_ 2432656775 pOperatorButton9 0 "Not Pressed" 1 "Pressed" 2 "Error" 3 "Not Available";
VAL_ 2432656775 pOperatorButton10 0 "Not Pressed" 1 "Pressed" 2 "Error" 3 "Not Available";
VAL_ 2432656775 pOperatorButton11 0 "Not Pressed" 1 "Pressed" 2 "Error" 3 "Not Available";
VAL_ 2432656775 pOperatorButton12 0 "Not Pressed" 1 "Pressed" 2 "Error" 3 "Not Available";
VAL_ 2432656775 pOperatorButton13 0 "Not Pressed" 1 "Pressed" 2 "Error" 3 "Not Available";
VAL_ 2432656775 pOperatorButton14 0 "Not Pressed" 1 "Pressed" 2 "Error" 3 "Not Available";
VAL_ 2432656775 pOperatorButton15 0 "Not Pressed" 1 "Pressed" 2 "Error" 3 "Not Available";
VAL_ 2432656775 pOperatorButton16 0 "Not Pressed" 1 "Pressed" 2 "Error" 3 "Not Available";
VAL_ 2432656775 pOperatorButton17 0 "Not Pressed" 1 "Pressed" 2 "Error" 3 "Not Available";
VAL_ 2432656775 pOperatorButton18 0 "Not Pressed" 1 "Pressed" 2 "Error" 3 "Not Available";
VAL_ 2432656775 pOperatorButton19 0 "Not Pressed" 1 "Pressed" 2 "Error" 3 "Not Available";
VAL_ 2432656775 pOperatorButton20 0 "Not Pressed" 1 "Pressed" 2 "Error" 3 "Not Available";
VAL_ 2432656775 pOperatorButton21 0 "Not Pressed" 1 "Pressed" 2 "Error" 3 "Not Available";
VAL_ 2432656775 pOperatorButton22 0 "Not Pressed" 1 "Pressed" 2 "Error" 3 "Not Available";
VAL_ 2432656775 pOperatorButton23 0 "Not Pressed" 1 "Pressed" 2 "Error" 3 "Not Available";
VAL_ 2432656775 pOperatorButton24 0 "Not Pressed" 1 "Pressed" 2 "Error" 3 "Not Available";
VAL_ 2432656775 pOperatorButton25 0 "Not Pressed" 1 "Pressed" 2 "Error" 3 "Not Available";
VAL_ 2432656775 pOperatorButton26 0 "Not Pressed" 1 "Pressed" 2 "Error" 3 "Not Available";
VAL_ 2432656775 pOperatorButton27 0 "Not Pressed" 1 "Pressed" 2 "Error" 3 "Not Available";
VAL_ 2432656775 pOperatorButton28 0 "Not Pressed" 1 "Pressed" 2 "Error" 3 "Not Available";
VAL_ 2432656775 pSideStandStatus 0 "Side Stand Down" 1 "Side Stand Up" 2 "Error Indicator" 3 "Not Available";
VAL_ 2365449728 HydBrkPressWarnStateCir1 0 "Pressure level sufficient" 1 "Pressure level below warning lev" 2 "Error" 3 "Not available";
VAL_ 2365449728 HydBrkPressWarnStateCir2 0 "Pressure level sufficient" 1 "Pressure level below warning lev" 2 "Error" 3 "Not available";
VAL_ 2365449728 HydBrkPressSupplyStateCir1 0 "Supply is not reliable" 1 "Supply is reliable" 2 "Error" 3 "Not available";
VAL_ 2365449728 HydBrkPressSupplyStateCir2 0 "Supply is not reliable" 1 "Supply is reliable" 2 "Error" 3 "Not available";
VAL_ 2365449728 HydBrakeFluidLevelSwitch 0 "Fluid level is not sufficient" 1 "Fluid level is sufficient" 2 "Error" 3 "Not available";
VAL_ 2566884352 BrakeSwitch 0 "PedalReleased" 1 "PedalDepressed" 2 "Error" 3 "NotAvailable";
VAL_ 2566877607 pVolumeUnitsSelected 0 "Gallons" 1 "Liters" 2 "Imperial Gallons" 3 "Reserved" 4 "Reserved" 5 "Reserved" 6 "Error" 7 "Not Available";
VAL_ 2566877607 pTimeUnitsSelected 0 "12 Hour" 1 "24 Hour" 2 "Error" 3 "Not Available";
VAL_ 2566877607 pTemperatureUnitsSelected 0 "Farenheit" 1 "Celsius" 2 "Error" 3 "Not Avaialable";
VAL_ 2566877607 pPressureUnitsSelected 0 "Pounds Per Square Inch (PSI)" 1 "Kilopascal (kPa)" 2 "Error" 3 "Not Available";
VAL_ 2566877607 pDistanceUnitsSelected 0 "Miles" 1 "Kilometers" 2 "Error" 3 "Not Available";
VAL_ 2566877607 pTPMSLearningStatus 0 "Not Started" 1 "Request to start" 2 "Learning Left Front" 3 "Learning Right Front" 4 "Learning Left Rear" 5 "Learning Right Rear" 6 "Learning successfully completed" 13 "Request to end learning" 14 "Error - Failed Learning" 15 "Not Available";
VAL_ 2566877607 pDisplayStatus 0 "Info cant overide to full screen" 1 "User requested full screen" 2 "Info can overide to full screen" 14 "Info data is not shown" 15 "Not Available";
VAL_ 2381320220 NMEA_Source 0 "GPS" 1 "GLONASS" 2 "WWV" 3 "Local Cesium Clock" 4 "Local Rubidium Clock" 5 "Local Crystal Clock" 6 "Reserved Field" 15 "Null";
VAL_ 2583298844 NMEA_OpMode 0 "1D" 1 "2D" 2 "3D" 3 "Auto" 4 "Reserved Field" 6 "Error" 7 "Null";
VAL_ 2583298844 NMEA_SetMode 0 "1D" 1 "2D" 2 "3D" 3 "Auto" 4 "Reserved Field" 6 "Error" 7 "Null";
VAL_ 2314732060 NMEA_COG_Reference 0 "True" 1 "Magnetic" 2 "Error" 3 "Null";
VAL_ 2364606707 HVES1M11OperlSts_8224 0 "Not Operational" 1 "Operational" 2 "Error" 3 "Not Available";
VAL_ 2364606707 HVES1M9OperlSts_8222 0 "Not Operational" 1 "Operational" 2 "Error" 3 "Not Available";
VAL_ 2364606707 HVES1M8OperlSts_8221 0 "Not Operational" 1 "Operational" 2 "Error" 3 "Not Available";
VAL_ 2364606707 HVES1M7OperlSts_8220 0 "Not Operational" 1 "Operational" 2 "Error" 3 "Not Available";
VAL_ 2364606707 HVES1M6OperlSts_8219 0 "Not Operational" 1 "Operational" 2 "Error" 3 "Not Available";
VAL_ 2364606707 HVES1M5OperlSts_8218 0 "Not Operational" 1 "Operational" 2 "Error" 3 "Not Available";
VAL_ 2364606707 HVES1M4OperlSts_8217 0 "Not Operational" 1 "Operational" 2 "Error" 3 "Not Available";
VAL_ 2364606707 HVES1M3OperlSts_8216 0 "Not Operational" 1 "Operational" 2 "Error" 3 "Not Available";
VAL_ 2364606707 HVES1M2OperlSts_8215 0 "Not Operational" 1 "Operational" 2 "Error" 3 "Not Available";
VAL_ 2364606707 HVES1M1OperlSts_8214 0 "Not Operational" 1 "Operational" 2 "Error" 3 "Not Available";
VAL_ 2364606707 HVES1M16OperlSts_8229 0 "Not Operational" 1 "Operational" 2 "Error" 3 "Not Available";
VAL_ 2364606707 HVES1M15OperlSts_8228 0 "Not Operational" 1 "Operational" 2 "Error" 3 "Not Available";
VAL_ 2364606707 HVES1M14OperlSts_8227 0 "Not Operational" 1 "Operational" 2 "Error" 3 "Not Available";
VAL_ 2364606707 HVES1M13OperlSts_8226 0 "Not Operational" 1 "Operational" 2 "Error" 3 "Not Available";
VAL_ 2364606707 HVES1M12OperlSts_8225 0 "Not Operational" 1 "Operational" 2 "Error" 3 "Not Available";
VAL_ 2364606707 HVES1M10OperlSts_8223 0 "Not Operational" 1 "Operational" 2 "Error" 3 "Not Available";
VAL_ 2364552947 HVES1CPLDToUndefCause_8114 0 "Now power limit for this reason" 1 "Power limited for this reason" 2 "Error" 3 "Not Available";
VAL_ 2364552947 HVES1CPLDTBT_8110 0 "Now power limit for this reason" 1 "Power limited for this reason" 2 "Error" 3 "Not Available";
VAL_ 2364552947 HVES1CPLDTBOrCellV_8112 0 "Now power limit for this reason" 1 "Power limited for this reason" 2 "Error" 3 "Not Available";
VAL_ 2364552947 HVES1CPLDTBDiagcCdn_8111 0 "Now power limit for this reason" 1 "Power limited for this reason" 2 "Error" 3 "Not Available";
VAL_ 2364552947 HVES1CPLDTBCur_8113 0 "Now power limit for this reason" 1 "Power limited for this reason" 2 "Error" 3 "Not Available";
VAL_ 2364552947 HVES1DPLDTStOfCha_8109 0 "Now power limit for this reason" 1 "Power limited for this reason" 2 "Error" 3 "Not Available";
VAL_ 2364552947 HVES1DPLDTStOfCha_8103 0 "Now power limit for this reason" 1 "Power limited for this reason" 2 "Error" 3 "Not Available";
VAL_ 2364552947 HVES1DPLDToUndefCause_8108 0 "Now power limit for this reason" 1 "Power limited for this reason" 2 "Error" 3 "Not Available";
VAL_ 2364552947 HVES1DPLDTBT_8104 0 "Now power limit for this reason" 1 "Power limited for this reason" 2 "Error" 3 "Not Available";
VAL_ 2364552947 HVES1DPLDTBOrCellV_8106 0 "Now power limit for this reason" 1 "Power limited for this reason" 2 "Error" 3 "Not Available";
VAL_ 2364552947 HVES1DPLDTBDiagcCdn_8105 0 "Now power limit for this reason" 1 "Power limited for this reason" 2 "Error" 3 "Not Available";
VAL_ 2364552947 HVES1DPLDTBCur_8107 0 "Now power limit for this reason" 1 "Power limited for this reason" 2 "Error" 3 "Not Available";
VAL_ 2364606963 HVES1TMSMode_8235 0 "Off" 1 "Circulating" 2 "Cooling" 3 "Heating" 4 "Drying" 5 "Reserved" 6 "Reserved" 7 "Reserved" 8 "Reserved" 9 "Reserved" 10 "Reserved" 11 "Reserved" 12 "Reserved" 13 "Reserved" 14 "Error" 15 "Not Available";
VAL_ 2364606963 HVES1TMSHeatrSts_8234 0 "Heater Off" 1 "Heater On" 2 "Error" 3 "Description for the value '3'";
VAL_ 2364577523 HVES1StOfChaSts_8100 0 "SOC level is acceptable" 1 "SOC approach recommend low lim
" 2 "SOC at its recommended lower lim" 3 "SOC below recommended low lim
" 4 " SOC approach recommend up lim" 5 "SOC at its recommended up lim" 6 "SOC above recommended up lim" 7 "Reserved" 8 "Reserved" 9 "Reserved" 10 "Reserved" 11 "Reserved" 12 "Reserved" 13 "Reserved" 14 "Error" 15 "Description for the value '15'";
VAL_ 2364577523 HVES1OperationlSts_8414 0 "Init in proc, HVES powering up" 1 " Init Complete, waiting consent" 2 "Operational" 3 "Norm Pwr-dwn in proc." 4 "Emergency Pwr-dwn in proc" 5 "Disabled by ext cmd. HVES non-op" 6 "Disabled by int dec of HVES" 7 "Reserved" 8 "Reserved" 9 "Reserved" 10 "Reserved" 11 "Reserved" 12 "Reserved" 13 "Reserved" 14 "Error" 15 "Not Available";
VAL_ 2364577523 HVES1IntChaSts_8207 0 "Charging off" 1 "Charging on" 2 "Error" 3 "Not Available";
VAL_ 2364577523 HVES1InertiaSwtSts_8099 0 "No impact sensed" 1 "Impact sensed" 2 "Error" 3 "Description for the value '3'";
VAL_ 2364577523 HVES1HVILSts_8098 0 "HVIL Closed" 1 "HVIL Open" 2 "Error" 3 "Not Available";
VAL_ 2364577523 HVES1HVBusPsvIsoTstSts_8097 0 "No test requested or in process" 1 "Test requested but not in proc" 2 " Test in process
" 3 "Test complete; isolation accept" 4 " Test complete; isolat marginal" 5 "Test complete; isolation fault
" 6 "Reserved" 7 "Reserved" 8 "Reserved" 9 "Reserved" 10 "Reserved" 11 "Reserved" 12 "Reserved" 13 "Reserved" 14 "Error" 15 "Description for the value '15'";
VAL_ 2364577523 HVES1HVBusPrechaRlySt_8094 0 "Relay Open" 1 "Relay Closed" 2 "Error" 3 "Not Available";
VAL_ 2364577523 HVES1HVBusDiscnctWarn_8093 0 "Disconnect not pending" 1 "Discnct imminent-bp V appr min" 2 "Discnct imminent-bp V appr max" 3 "Discnct imminent-mod V appr min" 4 "Dis imminent-mod V appr max" 5 "Dis imminent-cell V appr min" 6 "Dis imminent-cell V appr max" 7 "Dis imminent bp cur appro min" 8 "Reserved" 9 "Reserved" 10 "Reserved" 11 "Reserved" 12 "Reserved" 13 "Dis imminent - no reason given" 14 "Error" 15 "Not Available" 16 "Description for the value '16'";
VAL_ 2364577523 HVES1HVBusCnctnSts_8413 0 "Disconnected.  contactors open." 1 "Connected.  contractors closed" 2 "Connection in Process" 3 "Disconnection in Process" 4 "Disconnected; Precharge Failed" 5 "Reserved" 6 "Reserved" 7 "Reserved" 8 "Reserved" 9 "Reserved" 10 "Reserved" 11 "Reserved" 12 "Reserved" 13 "Reserved" 14 "Error" 15 "Not Available";
VAL_ 2364577523 HVES1HVBusAcvIsoTstSts_8096 0 "No test requested or in process" 1 "Test requested but not in proc" 2 " Test in process
" 3 "Test complete; isolation accept" 4 " Test complete; isolat marginal" 5 "Test complete; isolation fault
" 6 "Reserved" 7 "Reserved" 8 "Reserved" 9 "Reserved" 10 "Reserved" 11 "Reserved" 12 "Reserved" 13 "Reserved" 14 "Error" 15 "Description for the value '15'";
VAL_ 2364577523 HVES1HVBCtorStPos_8091 0 "Contractor Open" 1 "Contractor Closed" 2 "Error" 3 "Not Available";
VAL_ 2364577523 HVES1HVBCtorStNeg_8092 0 "Contractor Open" 1 "Contractor Closed" 2 "Error" 3 "Not Available";
VAL_ 2364577523 HVES1CtrOfPackCtorSt_8095 0 "Contractor Open" 1 "Contractor Closed" 2 "Error" 3 "Description for the value '3'";
VAL_ 2364577523 HVES1CellBalnSts_8101 0 "Cells are balanced" 1 "Cells are unbalanced" 2 "Error" 3 "Not Available";
VAL_ 2364577523 HVES1CellBalnAcv_8102 0 "Cell balancing is not active
" 1 "Cell balancing is active
" 2 "Error" 3 "Not Available";
VAL_ 2364576499 HVES1CellTDftlSts_8078 0 "T dftl within acceptable lmts" 1 "T dftl exceeds acceptable lmts" 2 "Error" 3 "Description for the value '3'";
VAL_ 2364576243 HVES1CellVoltDftlSts_5924 0 "within acceptable limits" 1 "exceeds limits but correctable" 2 "exceeds limits - maint bal reqd" 3 "exceeds limits - can't restore" 4 "exc lim - restorability unknown" 5 "Reserved" 6 "Reserved" 7 "Reserved" 8 "Reserved" 9 "Reserved" 10 "Reserved" 11 "Reserved" 12 "Reserved" 13 "Reserved" 14 "Error" 15 "Description for the value '15'";
VAL_ 2499548158 RightRearCabDoorLatchPos 0 "Door Latch Open" 1 "Door Latch Fully Closed/Latched" 2 "Door Latch Ajar" 3 "Reserved" 4 "Reserved" 5 "Reserved" 6 "Error" 7 "Not Available";
VAL_ 2499548158 LeftRearCabDoorLatchPos 0 "Door Latch Open" 1 "Door Latch Fully Closed/Latched" 2 "Door Latch Ajar" 3 "Reserved" 4 "Reserved" 5 "Reserved" 6 "Error" 7 "Not Available";
VAL_ 2499548158 RightFrontCabDoorLatchPos 0 "Door Latch Open" 1 "Door Latch Fully Closed/Latched" 2 "Door Latch Ajar" 3 "Reserved" 4 "Reserved" 5 "Reserved" 6 "Error" 7 "Not Available";
VAL_ 2499548158 LeftFrontCabDoorLatchPos 0 "Door Latch Open" 1 "Door Latch Fully Closed/Latched" 2 "Door Latch Ajar" 3 "Reserved" 4 "Reserved" 5 "Reserved" 6 "Error" 7 "Not Available";
VAL_ 2499547902 MirrorRight2HeatCmd 0 "Mirror heat off" 1 "Mirror heat on" 2 "Reserved" 3 "Take no action";
VAL_ 2499547902 MirrorLeft2HeatCmd 0 "Mirror heat off" 1 "Mirror heat on" 2 "Reserved" 3 "Take no action";
VAL_ 2499547902 MirrorRight1HeatCmd 0 "Mirror heat off" 1 "Mirror heat on" 2 "Reserved" 3 "Take no action";
VAL_ 2499547902 MirrorLeft1HeatCmd 0 "Mirror heat off" 1 "Mirror heat on" 2 "Reserved" 3 "Take no action";
VAL_ 2499547902 MirrorRight2VerticalCmd 0 "Move up" 1 "Move down" 2 "Reserved" 3 "Take no action";
VAL_ 2499547902 MirrorRight2HorizontalCmd 0 "Move left" 1 "Move right" 2 "Reserved" 3 "Take no action";
VAL_ 2499547902 MirrorLeft2VerticalCmd 0 "Move up" 1 "Move down" 2 "Reserved" 3 "Take no action";
VAL_ 2499547902 MirrorLeft2HorizontalCmd 0 "Move left" 1 "Move right" 2 "Reserved" 3 "Take no action";
VAL_ 2499547902 MirrorRight1VerticalCmd 0 "Move up" 1 "Move down" 2 "Reserved" 3 "Take no action";
VAL_ 2499547902 MirrorRight1HorizontalCmd 0 "Move left" 1 "Move right" 2 "Reserved" 3 "Take no action";
VAL_ 2499547902 MirrorLeft1VerticalCmd 0 "Move up" 1 "Move down" 2 "Reserved" 3 "Take no action";
VAL_ 2499547902 MirrorLeft1HorizontalCmd 0 "Move left" 1 "Move right" 2 "Reserved" 3 "Take no action";
VAL_ 2499547902 RightRearWindowPosCmd 0 "Window move up" 1 "Window move down" 2 "Window auto up" 3 "Window auto down" 4 "Reserved" 5 "Reserved" 6 "Reserved" 7 "Take no action";
VAL_ 2499547902 LeftRearWindowPosCmd 0 "Window move up" 1 "Window move down" 2 "Window auto up" 3 "Window auto down" 4 "Reserved" 5 "Reserved" 6 "Reserved" 7 "Take no action";
VAL_ 2499547902 RightFrontWindowPosCmd 0 "Window move up" 1 "Window move down" 2 "Window auto up" 3 "Window auto down" 4 "Reserved" 5 "Reserved" 6 "Reserved" 7 "Take no action";
VAL_ 2499547902 LeftFrontWindowPosCmd 0 "Window move up" 1 "Window move down" 2 "Window auto up" 3 "Window auto down" 4 "Reserved" 5 "Reserved" 6 "Reserved" 7 "Take no action";
VAL_ 2499547902 RemoteCabDoorLockReq 0 "Request unlock left front cab door latch" 1 "Request unlock right front cab door latch" 2 "Request unlock left rear cab door latch" 3 "Request unlock right rear cab door latch" 4 "Request unlock all cab door latches" 5 "Request lock all cab door latches" 6 "Reserved" 7 "Take no action";
VAL_ 2499547902 DoorsLockActCmd 0 "Unlock left front cab door latch" 1 "Unlock right front cab door latch" 2 "Unlock left rear cab door latch" 3 "Unlock right rear cab door latch" 4 "Unlock all cab door latches" 5 "Lock all cab door latches" 6 "Reserved" 7 "Take no action";
VAL_ 2431710718 AutomaticEngStartConsentSummary 0 "No consent" 1 "Consent" 2 "Error" 3 "Not available";
VAL_ 2431710718 OpEngStartConsentSummary 0 "No consent" 1 "Consent" 2 "Error" 3 "Not available";
VAL_ 2431710718 ReqLatchStatus 0 "Start request not received" 1 "Start request latched, waiting for consent" 2 "Start request latched, consent confirmed" 3 "Start request unlatched, start completed" 4 "Start request unlatched, consent not established within allowed time" 5 "Start request unlatched, start aborted due to abort request" 6 "Start request unlatched, start could not be completed because the starter command was not successful" 15 "Not available";
VAL_ 2431710718 StarterCmd 0 "Command not active" 1 "Command active for starter 1" 2 "Command active for starter 2" 3 "Command withdrawn" 7 "Don’t care / Take no action";
VAL_ 2431710718 CtrlMessageRate 0 "Once every 20 ms" 1 "Once every 250 ms or on change but no faster than 20 ms" 2 "Reserved" 3 "Not available";
VAL_ 2431708670 Starter2Feedback 0 "Starter not commanded" 1 "Starter command latched" 2 "Starter command unlatched,  start completed" 3 "Starter command unlatched,  start abort command received from arbitrator" 4 "Starter command unlatched,  start aborted by starter controller" 7 "Not available";
VAL_ 2431708670 Starter1Feedback 0 "Starter not commanded" 1 "Starter command latched" 2 "Starter command unlatched,  start completed" 3 "Starter command unlatched,  start abort command received from arbitrator" 4 "Starter command unlatched,  start aborted by starter controller" 7 "Not available";
VAL_ 2431708670 AbortReq 0 "Abort not requested" 1 "Abort requested" 2 "Reserved" 3 "Don’t care / Take no action";
VAL_ 2431708670 Consent 0 "No consent" 1 "Consent to operator-requested start only" 2 "Consent to automatic start only" 3 "Consent to both" 7 "Not available";
VAL_ 2431708670 Req 0 "Start not requested" 1 "Start requested,  operator type" 2 "Start requested,  automatic type" 3 "Not available";
VAL_ 2565926142 NOxSnsr2SelfDiagStatus 0 "Diagnosis not active" 1 "NOx Sensor ATO2 Self Diagnosis active flag" 2 "NOx Sensor ATO2 Self Diagnosis Result Complete" 3 "NOx Sensor ATO2 Self Diagnosis aborted" 4 "NOx Sensor ATO2 Self Diagnosis not possible" 7 "Not Supported";
VAL_ 2565926142 GasSnsr2HtrCtrl 0 "Automatic" 1 "Preheat 2" 2 "Preheat 1" 3 "Heater off";
VAL_ 2565926142 WRPercentO22ReadingStable 0 "Not stable" 1 "Stable" 2 "Error" 3 "Not available";
VAL_ 2565926142 NOx2ReadingStable 0 "Not stable" 1 "Stable" 2 "Error" 3 "Not available";
VAL_ 2565926142 GasSnsr2AtTemp 0 "Not in range" 1 "In range" 2 "Error" 3 "Not available";
VAL_ 2565926142 GasSnsr2PwrInRange 0 "Not in range" 1 "In range" 2 "Error" 3 "Not available";
VAL_ 2565925886 NOxSnsr2SelfDiagStatus 0 "Diagnosis not active" 1 "NOx Sensor ATI2 Self Diagnosis active flag" 2 "NOx Sensor ATI2 Self Diagnosis Result Complete" 3 "NOx Sensor ATI2 Self Diagnosis aborted" 4 "NOx Sensor ATI2 Self Diagnosis not possible" 7 "Not Supported";
VAL_ 2565925886 GasSnsr2HtrCtrl 0 "Automatic" 1 "Preheat 2" 2 "Preheat 1" 3 "Heater off";
VAL_ 2565925886 WRPercentO22ReadingStable 0 "Not stable" 1 "Stable" 2 "Error" 3 "Not available";
VAL_ 2565925886 SCRInNOx2ReadingStable 0 "Not stable" 1 "Stable" 2 "Error" 3 "Not available";
VAL_ 2565925886 GasSnsr2AtTemp 0 "Not in range" 1 "In range" 2 "Error" 3 "Not available";
VAL_ 2565925886 GasSnsr2PwrInRange 0 "Not in range" 1 "In range" 2 "Error" 3 "Not available";
VAL_ 2565925630 NOxSnsr2SelfDiagStatus 0 "Diagnosis not active" 1 "NOx Sensor ATO1 Self Diagnosis active flag" 2 "NOx Sensor ATO1 Self Diagnosis Result Complete" 3 "NOx Sensor ATO1 Self Diagnosis aborted" 4 "NOx Sensor ATO1 Self Diagnosis not possible" 7 "Not Supported";
VAL_ 2565925630 Snsr2HtrCtrl 0 "Automatic" 1 "Preheat 2" 2 "Preheat 1" 3 "Heater off";
VAL_ 2565925630 WRPercentO22ReadingStable 0 "Not stable" 1 "Stable" 2 "Error" 3 "Not available";
VAL_ 2565925630 NOx2ReadingStable 0 "Not stable" 1 "Stable" 2 "Error" 3 "Not available";
VAL_ 2565925630 Snsr2AtTemp 0 "Not in range" 1 "In range" 2 "Error" 3 "Not available";
VAL_ 2565925630 Snsr2PwrInRange 0 "Not in range" 1 "In range" 2 "Error" 3 "Not available";
VAL_ 2565925374 NOxSnsr2SelfDiagStatus 0 "Diagnosis not active" 1 "NOx Sensor ATI1 Self Diagnosis active flag" 2 "NOx Sensor ATI1 Self Diagnosis Result Complete" 3 "NOx Sensor ATI1 Self Diagnosis aborted" 4 "NOx Sensor ATI1 Self Diagnosis not possible" 7 "Not Supported";
VAL_ 2565925374 Snsr2HtrCtrl 0 "Automatic" 1 "Preheat 2" 2 "Preheat 1" 3 "Heater off";
VAL_ 2565925374 WRPercentO22ReadingStable 0 "Not stable" 1 "Stable" 2 "Error" 3 "Not available";
VAL_ 2565925374 SCRInNOx2ReadingStable 0 "Not stable" 1 "Stable" 2 "Error" 3 "Not available";
VAL_ 2565925374 Snsr2AtTemp 0 "Not in range" 1 "In range" 2 "Error" 3 "Not available";
VAL_ 2565925374 Snsr2PwrInRange 0 "Not in range" 1 "In range" 2 "Error" 3 "Not available";
VAL_ 2566838014 ShutdownSw 0 "Off" 1 "On" 2 "Error" 3 "Not Available";
VAL_ 2566838014 PropulsionDisableSw 0 "Off" 1 "On" 2 "Error" 3 "Not Available";
VAL_ 2566838014 HybrdSystmBrkPdlRgnrtvBrkngDsblS 0 "Brake pedal regenerative braking disable switch is off" 1 "Brake pedal regenerative braking disable switch is on" 2 "Error" 3 "Not Available";
VAL_ 2566838014 HybrdSystmRgnrtvBrkngDsbleSwitch 0 "Regenerative Braking Disable Switch is off" 1 "Regenerative Braking  Disable Switch is on" 2 "Error" 3 "Not Available";
VAL_ 2566838014 HybrdSystmOffBrdChrgrCnnctnSttus 0 "Off-board charger is not connected" 1 "Off-board charger is connected" 2 "Error" 3 "Not available";
VAL_ 2566838014 HybrdSystmPwrElctrncsClntLvlSwtc 0 "Coolant Level is not sufficient" 1 "Coolant Level is sufficient" 2 "Error" 3 "Not Available";
VAL_ 2566838014 HybrdSystmPrplsnClantLevelSwitch 0 "Coolant Level is not sufficient" 1 "Coolant Level is sufficient" 2 "Error" 3 "Not Available";
VAL_ 2566838014 HybrdSystmPrtctionOverrideSwitch 0 "Not Active" 1 "Active" 2 "Error" 3 "Not Available";
VAL_ 2566687998 RegenSt 0 "Regeneration is not active" 1 "Regneration is active and has been initiated by request via SPN 6783" 2 "Regeneration is active and has been initiated because of sensor conditions" 3 "Regeneration is active and has been initiated due to time based conditions" 15 "Not Available";
VAL_ 2566687998 RegenStatus 0 "Regeneration attempt has not occurred during this operational cycle" 1 "Regeneration was successful" 2 "Regeneration failed" 3 "not available";
VAL_ 2566687998 HtrSt 0 "Heater is in closed loop control" 1 "Heater is being held at a specified level" 2 "Heater is in ramp up mode" 3 "Heater is off";
